[part 4 of 22: package /Cluster]
AUTOSAR XML (schema 4-3-0)
package /Cluster  (continued)
  can cluster E3V_CCAN: baudrate=500000, protocol-name=CAN, protocol-version=2.0, bus-off-recovery={bor-counter-l-1-to-l-2=1, bor-time-l-1=0.05, bor-time-l-2=0.2}  (continued)
    can physical channel CHNL: comm-connectors=CN_E3V_CCAN  (continued)
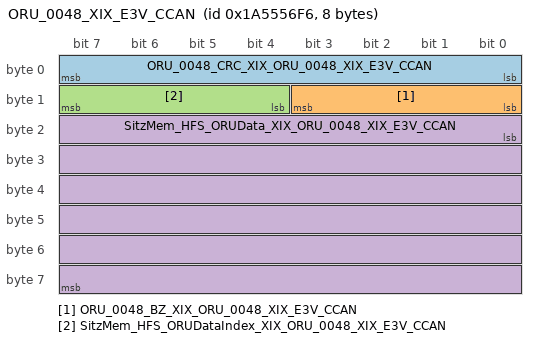
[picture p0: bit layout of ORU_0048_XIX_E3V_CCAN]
      frame ORU_0048_XIX_E3V_CCAN: id 0x1A5556F6, to SAM, frame-length=8, can-addressing-mode=EXTENDED, can-frame-rx-behavior=CAN-20, can-frame-tx-behavior=CAN-20
        pdu ORU_0048_XIX_E3V_CCAN_E2E: length=8, transmission-mode-true-timing=event-controlled-timing={number-of-repetitions=0, repetition-period=0.0}, unused-bit-pattern=0  # Fuer die Botschaft ist das Cyclic-Timing 0.5 zu verwenden.
          signal ORU_0048_CRC_XIX_ORU_0048_XIX_E3V_CCAN: start 0, 8 bit, little-endian, data-type-policy=OVERRIDE, i-signal-type=PRIMITIVE, init-value=0, base-type=BT_ORU_0048_CRC, compu {phys=raw for raw 0..255}, range phys 0..255, raw 0..255, to SAM(timeout 5 s)  # Für MLB: Berechnung siehe Lastenheft "Kommunikationsabsicherung für FlexRay und CAN" Ab MQB und MLBevo: Berechnung siehe Lastenheft "End-to-End Kommunikationsabsicherung" Endwerte siehe Begleitdokument "S-PDU Kennungsfolgen"
          signal ORU_0048_BZ_XIX_ORU_0048_XIX_E3V_CCAN: start 8, 4 bit, little-endian, data-type-policy=OVERRIDE, i-signal-type=PRIMITIVE, init-value=0, base-type=BT_ORU_0048_BZ, compu {phys=raw for raw 0..15}, range phys 0..15, raw 0..15, to SAM(timeout 5 s)  # 4bit Botschaftszähler, wird mit jeder Sendebotschaft inkrementiert
          signal SitzMem_HFS_ORUDataIndex_XIX_ORU_0048_XIX_E3V_CCAN: start 12, 4 bit, little-endian, data-type-policy=OVERRIDE, i-signal-type=PRIMITIVE, init-value=0, base-type=BT_SitzMem_HFS_ORUDataIndex, compu {phys=raw for raw 0..15}, range phys 0..15, raw 0..15, to SAM(timeout 5 s)  # Data index of the last 6 Bytes
          signal SitzMem_HFS_ORUData_XIX_ORU_0048_XIX_E3V_CCAN: start 16, 48 bit, little-endian, data-type-policy=OVERRIDE, i-signal-type=PRIMITIVE, init-value=0, base-type=BT_SitzMem_HFS_ORUData, compu {phys=raw for raw 0..281474976710655}, range phys 0..281474976710655, raw 0..281474976710655, to SAM(timeout 5 s)  # ORU information multiplexed - diagnostic address (2 bytes) - HW-part no (11 bytes) - HW version no. (3 bytes) - SW version no. (4 bytes) - IVD-P Value (64 bytes) need to be sent in combination with ORUDataIndex
          mapping SG_ORU_0048_XIX_E3V_CCAN: i-signal-group=SG_ORU_0048_XIX_E3V_CCAN, transfer-property=TRIGGERED-WITHOUT-REPETITION
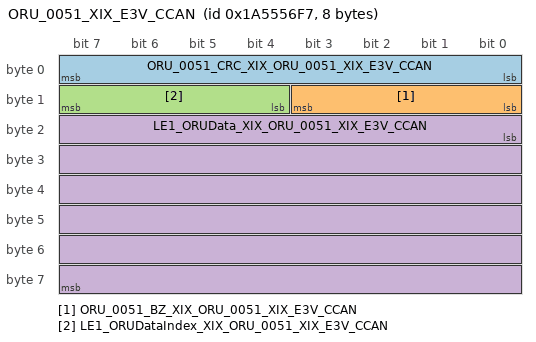
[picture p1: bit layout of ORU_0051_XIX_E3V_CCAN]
      frame ORU_0051_XIX_E3V_CCAN: id 0x1A5556F7, to SAM, frame-length=8, can-addressing-mode=EXTENDED, can-frame-rx-behavior=CAN-20, can-frame-tx-behavior=CAN-20
        pdu ORU_0051_XIX_E3V_CCAN_E2E: length=8, transmission-mode-true-timing=event-controlled-timing={number-of-repetitions=0, repetition-period=0.0}, unused-bit-pattern=0  # Fuer die Botschaft ist das Cyclic-Timing 0.5 zu verwenden.
          signal ORU_0051_CRC_XIX_ORU_0051_XIX_E3V_CCAN: start 0, 8 bit, little-endian, data-type-policy=OVERRIDE, i-signal-type=PRIMITIVE, init-value=0, base-type=BT_ORU_0051_CRC, compu {phys=raw for raw 0..255}, range phys 0..255, raw 0..255, to SAM(timeout 5 s)  # Für MLB: Berechnung siehe Lastenheft "Kommunikationsabsicherung für FlexRay und CAN" Ab MQB und MLBevo: Berechnung siehe Lastenheft "End-to-End Kommunikationsabsicherung" Endwerte siehe Begleitdokument "S-PDU Kennungsfolgen"
          signal ORU_0051_BZ_XIX_ORU_0051_XIX_E3V_CCAN: start 8, 4 bit, little-endian, data-type-policy=OVERRIDE, i-signal-type=PRIMITIVE, init-value=0, base-type=BT_ORU_0051_BZ, compu {phys=raw for raw 0..15}, range phys 0..15, raw 0..15, to SAM(timeout 5 s)  # 4bit Botschaftszähler, wird mit jeder Sendebotschaft inkrementiert
          signal LE1_ORUDataIndex_XIX_ORU_0051_XIX_E3V_CCAN: start 12, 4 bit, little-endian, data-type-policy=OVERRIDE, i-signal-type=PRIMITIVE, init-value=0, base-type=BT_LE1_ORUDataIndex, compu {phys=raw for raw 0..15}, range phys 0..15, raw 0..15, to SAM(timeout 5 s)  # Dataindex of the last 6 bytes
          signal LE1_ORUData_XIX_ORU_0051_XIX_E3V_CCAN: start 16, 48 bit, little-endian, data-type-policy=OVERRIDE, i-signal-type=PRIMITIVE, init-value=0, base-type=BT_LE1_ORUData, compu {phys=raw for raw 0..281474976710655}, range phys 0..281474976710655, raw 0..281474976710655, to SAM(timeout 5 s)  # ORU information multiplexed - diagnostic address (2 bytes) - HW-part no (11 bytes) - HW version no. (3 bytes) - SW version no. (4 bytes) - IVD-P Value (64 bytes) need to be sent in combination with ORUDataIndex
          mapping SG_ORU_0051_XIX_E3V_CCAN: i-signal-group=SG_ORU_0051_XIX_E3V_CCAN, transfer-property=TRIGGERED-WITHOUT-REPETITION
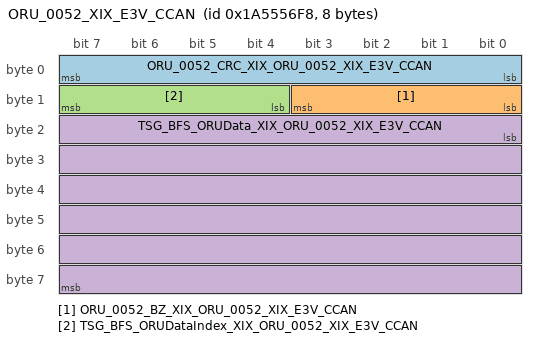
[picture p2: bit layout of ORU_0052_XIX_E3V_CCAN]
      frame ORU_0052_XIX_E3V_CCAN: id 0x1A5556F8, to SAM, frame-length=8, can-addressing-mode=EXTENDED, can-frame-rx-behavior=CAN-20, can-frame-tx-behavior=CAN-20
        pdu ORU_0052_XIX_E3V_CCAN_E2E: length=8, transmission-mode-true-timing=event-controlled-timing={number-of-repetitions=0, repetition-period=0.0}, unused-bit-pattern=0  # Fuer die Botschaft ist das Cyclic-Timing 0.5 zu verwenden.
          signal ORU_0052_CRC_XIX_ORU_0052_XIX_E3V_CCAN: start 0, 8 bit, little-endian, data-type-policy=OVERRIDE, i-signal-type=PRIMITIVE, init-value=0, base-type=BT_ORU_0052_CRC, compu {phys=raw for raw 0..255}, range phys 0..255, raw 0..255, to SAM(timeout 5 s)  # Für MLB: Berechnung siehe Lastenheft "Kommunikationsabsicherung für FlexRay und CAN" Ab MQB und MLBevo: Berechnung siehe Lastenheft "End-to-End Kommunikationsabsicherung" Endwerte siehe Begleitdokument "S-PDU Kennungsfolgen"
          signal ORU_0052_BZ_XIX_ORU_0052_XIX_E3V_CCAN: start 8, 4 bit, little-endian, data-type-policy=OVERRIDE, i-signal-type=PRIMITIVE, init-value=0, base-type=BT_ORU_0052_BZ, compu {phys=raw for raw 0..15}, range phys 0..15, raw 0..15, to SAM(timeout 5 s)  # 4bit Botschaftszähler, wird mit jeder Sendebotschaft inkrementiert
          signal TSG_BFS_ORUDataIndex_XIX_ORU_0052_XIX_E3V_CCAN: start 12, 4 bit, little-endian, data-type-policy=OVERRIDE, i-signal-type=PRIMITIVE, init-value=0, base-type=BT_TSG_BFS_ORUDataIndex, compu {phys=raw for raw 0..15}, range phys 0..15, raw 0..15, to SAM(timeout 5 s)  # Data index of the last 6 Bytes
          signal TSG_BFS_ORUData_XIX_ORU_0052_XIX_E3V_CCAN: start 16, 48 bit, little-endian, data-type-policy=OVERRIDE, i-signal-type=PRIMITIVE, init-value=0, base-type=BT_TSG_BFS_ORUData, compu {phys=raw for raw 0..281474976710655}, range phys 0..281474976710655, raw 0..281474976710655, to SAM(timeout 5 s)  # ORU information multiplexed - diagnostic address (2 bytes) - HW-part no (11 bytes) - HW version no. (3 bytes) - SW version no. (4 bytes) - IVD-P Value (64 bytes) need to be sent in combination with ORUDataIndex
          mapping SG_ORU_0052_XIX_E3V_CCAN: i-signal-group=SG_ORU_0052_XIX_E3V_CCAN, transfer-property=TRIGGERED-WITHOUT-REPETITION
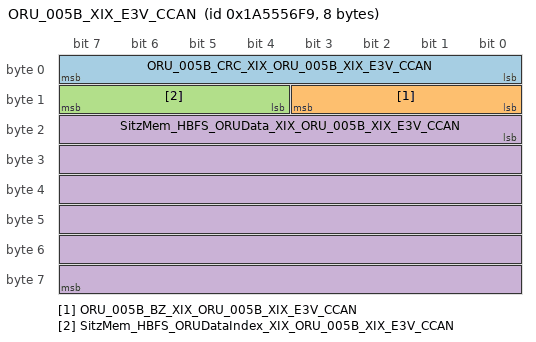
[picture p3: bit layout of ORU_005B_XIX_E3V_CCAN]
      frame ORU_005B_XIX_E3V_CCAN: id 0x1A5556F9, to SAM, frame-length=8, can-addressing-mode=EXTENDED, can-frame-rx-behavior=CAN-20, can-frame-tx-behavior=CAN-20
        pdu ORU_005B_XIX_E3V_CCAN_E2E: length=8, transmission-mode-true-timing=event-controlled-timing={number-of-repetitions=0, repetition-period=0.0}, unused-bit-pattern=0  # Fuer die Botschaft ist das Cyclic-Timing 0.5 zu verwenden.
          signal ORU_005B_CRC_XIX_ORU_005B_XIX_E3V_CCAN: start 0, 8 bit, little-endian, data-type-policy=OVERRIDE, i-signal-type=PRIMITIVE, init-value=0, base-type=BT_ORU_005B_CRC, compu {phys=raw for raw 0..255}, range phys 0..255, raw 0..255, to SAM(timeout 5 s)  # Für MLB: Berechnung siehe Lastenheft "Kommunikationsabsicherung für FlexRay und CAN" Ab MQB und MLBevo: Berechnung siehe Lastenheft "End-to-End Kommunikationsabsicherung" Endwerte siehe Begleitdokument "S-PDU Kennungsfolgen"
          signal ORU_005B_BZ_XIX_ORU_005B_XIX_E3V_CCAN: start 8, 4 bit, little-endian, data-type-policy=OVERRIDE, i-signal-type=PRIMITIVE, init-value=0, base-type=BT_ORU_005B_BZ, compu {phys=raw for raw 0..15}, range phys 0..15, raw 0..15, to SAM(timeout 5 s)  # 4bit Botschaftszähler, wird mit jeder Sendebotschaft inkrementiert
          signal SitzMem_HBFS_ORUDataIndex_XIX_ORU_005B_XIX_E3V_CCAN: start 12, 4 bit, little-endian, data-type-policy=OVERRIDE, i-signal-type=PRIMITIVE, init-value=0, base-type=BT_SitzMem_HBFS_ORUDataIndex, compu {phys=raw for raw 0..15}, range phys 0..15, raw 0..15, to SAM(timeout 5 s)  # Data index of the last 6 Bytes
          signal SitzMem_HBFS_ORUData_XIX_ORU_005B_XIX_E3V_CCAN: start 16, 48 bit, little-endian, data-type-policy=OVERRIDE, i-signal-type=PRIMITIVE, init-value=0, base-type=BT_SitzMem_HBFS_ORUData, compu {phys=raw for raw 0..281474976710655}, range phys 0..281474976710655, raw 0..281474976710655, to SAM(timeout 5 s)  # ORU information multiplexed - diagnostic address (2 bytes) - HW-part no (11 bytes) - HW version no. (3 bytes) - SW version no. (4 bytes) - IVD-P Value (64 bytes) need to be sent in combination with ORUDataIndex
          mapping SG_ORU_005B_XIX_E3V_CCAN: i-signal-group=SG_ORU_005B_XIX_E3V_CCAN, transfer-property=TRIGGERED-WITHOUT-REPETITION
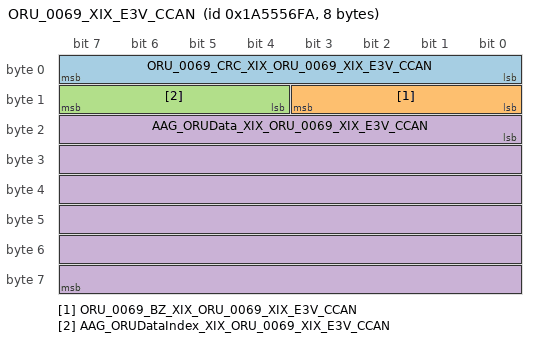
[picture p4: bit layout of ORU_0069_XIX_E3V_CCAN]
      frame ORU_0069_XIX_E3V_CCAN: id 0x1A5556FA, to SAM, frame-length=8, can-addressing-mode=EXTENDED, can-frame-rx-behavior=CAN-20, can-frame-tx-behavior=CAN-20
        pdu ORU_0069_XIX_E3V_CCAN_E2E: length=8, transmission-mode-true-timing=event-controlled-timing={number-of-repetitions=0, repetition-period=0.0}, unused-bit-pattern=0  # Fuer die Botschaft ist das Cyclic-Timing 0.5 zu verwenden.
          signal ORU_0069_CRC_XIX_ORU_0069_XIX_E3V_CCAN: start 0, 8 bit, little-endian, data-type-policy=OVERRIDE, i-signal-type=PRIMITIVE, init-value=0, base-type=BT_ORU_0069_CRC, compu {phys=raw for raw 0..255}, range phys 0..255, raw 0..255, to SAM(timeout 5 s)  # Für MLB: Berechnung siehe Lastenheft "Kommunikationsabsicherung für FlexRay und CAN" Ab MQB und MLBevo: Berechnung siehe Lastenheft "End-to-End Kommunikationsabsicherung" Endwerte siehe Begleitdokument "S-PDU Kennungsfolgen"
          signal ORU_0069_BZ_XIX_ORU_0069_XIX_E3V_CCAN: start 8, 4 bit, little-endian, data-type-policy=OVERRIDE, i-signal-type=PRIMITIVE, init-value=0, base-type=BT_ORU_0069_BZ, compu {phys=raw for raw 0..15}, range phys 0..15, raw 0..15, to SAM(timeout 5 s)  # 4bit Botschaftszähler, wird mit jeder Sendebotschaft inkrementiert
          signal AAG_ORUDataIndex_XIX_ORU_0069_XIX_E3V_CCAN: start 12, 4 bit, little-endian, data-type-policy=OVERRIDE, i-signal-type=PRIMITIVE, init-value=0, base-type=BT_AAG_ORUDataIndex, compu {phys=raw for raw 0..15}, range phys 0..15, raw 0..15, to SAM(timeout 5 s)  # Data index of the last 6 Bytes
          signal AAG_ORUData_XIX_ORU_0069_XIX_E3V_CCAN: start 16, 48 bit, little-endian, data-type-policy=OVERRIDE, i-signal-type=PRIMITIVE, init-value=0, base-type=BT_AAG_ORUData, compu {phys=raw for raw 0..281474976710655}, range phys 0..281474976710655, raw 0..281474976710655, to SAM(timeout 5 s)  # ORU information multiplexed - diagnostic address (2 bytes) - HW-part no (11 bytes) - HW version no. (3 bytes) - SW version no. (4 bytes) - IVD-P Value (64 bytes) need to be sent in combination with ORUDataIndex
          mapping SG_ORU_0069_XIX_E3V_CCAN: i-signal-group=SG_ORU_0069_XIX_E3V_CCAN, transfer-property=TRIGGERED-WITHOUT-REPETITION
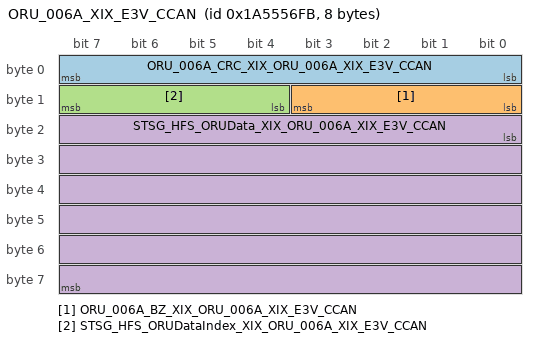
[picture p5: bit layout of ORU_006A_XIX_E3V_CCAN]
      frame ORU_006A_XIX_E3V_CCAN: id 0x1A5556FB, to SAM, frame-length=8, can-addressing-mode=EXTENDED, can-frame-rx-behavior=CAN-20, can-frame-tx-behavior=CAN-20
        pdu ORU_006A_XIX_E3V_CCAN_E2E: length=8, transmission-mode-true-timing=event-controlled-timing={number-of-repetitions=0, repetition-period=0.0}, unused-bit-pattern=0  # Fuer die Botschaft ist das Cyclic-Timing 0.5 zu verwenden.
          signal ORU_006A_CRC_XIX_ORU_006A_XIX_E3V_CCAN: start 0, 8 bit, little-endian, data-type-policy=OVERRIDE, i-signal-type=PRIMITIVE, init-value=0, base-type=BT_ORU_006A_CRC, compu {phys=raw for raw 0..255}, range phys 0..255, raw 0..255, to SAM(timeout 5 s)  # Für MLB: Berechnung siehe Lastenheft "Kommunikationsabsicherung für FlexRay und CAN" Ab MQB und MLBevo: Berechnung siehe Lastenheft "End-to-End Kommunikationsabsicherung" Endwerte siehe Begleitdokument "S-PDU Kennungsfolgen"
          signal ORU_006A_BZ_XIX_ORU_006A_XIX_E3V_CCAN: start 8, 4 bit, little-endian, data-type-policy=OVERRIDE, i-signal-type=PRIMITIVE, init-value=0, base-type=BT_ORU_006A_BZ, compu {phys=raw for raw 0..15}, range phys 0..15, raw 0..15, to SAM(timeout 5 s)  # 4bit Botschaftszähler, wird mit jeder Sendebotschaft inkrementiert
          signal STSG_HFS_ORUDataIndex_XIX_ORU_006A_XIX_E3V_CCAN: start 12, 4 bit, little-endian, data-type-policy=OVERRIDE, i-signal-type=PRIMITIVE, init-value=0, base-type=BT_STSG_HFS_ORUDataIndex, compu {phys=raw for raw 0..15}, range phys 0..15, raw 0..15, to SAM(timeout 5 s)  # Data index of the last 6 Bytes
          signal STSG_HFS_ORUData_XIX_ORU_006A_XIX_E3V_CCAN: start 16, 48 bit, little-endian, data-type-policy=OVERRIDE, i-signal-type=PRIMITIVE, init-value=0, base-type=BT_STSG_HFS_ORUData, compu {phys=raw for raw 0..281474976710655}, range phys 0..281474976710655, raw 0..281474976710655, to SAM(timeout 5 s)  # ORU information multiplexed - diagnostic address (2 bytes) - HW-part no (11 bytes) - HW version no. (3 bytes) - SW version no. (4 bytes) - IVD-P Value (64 bytes) need to be sent in combination with ORUDataIndex
          mapping SG_ORU_006A_XIX_E3V_CCAN: i-signal-group=SG_ORU_006A_XIX_E3V_CCAN, transfer-property=TRIGGERED-WITHOUT-REPETITION
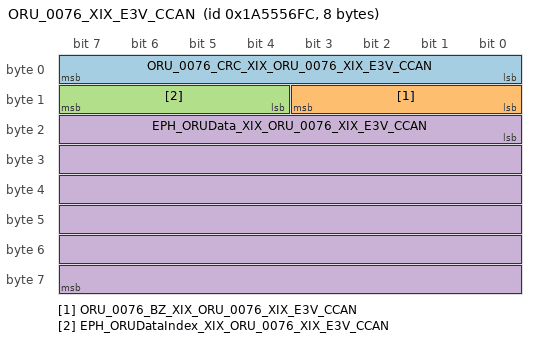
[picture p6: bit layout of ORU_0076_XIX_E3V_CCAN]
      frame ORU_0076_XIX_E3V_CCAN: id 0x1A5556FC, to SAM, frame-length=8, can-addressing-mode=EXTENDED, can-frame-rx-behavior=CAN-20, can-frame-tx-behavior=CAN-20
        pdu ORU_0076_XIX_E3V_CCAN_E2E: length=8, transmission-mode-true-timing=event-controlled-timing={number-of-repetitions=0, repetition-period=0.0}, unused-bit-pattern=0  # Fuer die Botschaft ist das Cyclic-Timing 0.5 zu verwenden.
          signal ORU_0076_CRC_XIX_ORU_0076_XIX_E3V_CCAN: start 0, 8 bit, little-endian, data-type-policy=OVERRIDE, i-signal-type=PRIMITIVE, init-value=0, base-type=BT_ORU_0076_CRC, compu {phys=raw for raw 0..255}, range phys 0..255, raw 0..255, to SAM(timeout 5 s)  # Für MLB: Berechnung siehe Lastenheft "Kommunikationsabsicherung für FlexRay und CAN" Ab MQB und MLBevo: Berechnung siehe Lastenheft "End-to-End Kommunikationsabsicherung" Endwerte siehe Begleitdokument "S-PDU Kennungsfolgen"
          signal ORU_0076_BZ_XIX_ORU_0076_XIX_E3V_CCAN: start 8, 4 bit, little-endian, data-type-policy=OVERRIDE, i-signal-type=PRIMITIVE, init-value=0, base-type=BT_ORU_0076_BZ, compu {phys=raw for raw 0..15}, range phys 0..15, raw 0..15, to SAM(timeout 5 s)  # 4bit Botschaftszähler, wird mit jeder Sendebotschaft inkrementiert
          signal EPH_ORUDataIndex_XIX_ORU_0076_XIX_E3V_CCAN: start 12, 4 bit, little-endian, data-type-policy=OVERRIDE, i-signal-type=PRIMITIVE, init-value=0, base-type=BT_EPH_ORUDataIndex, compu {phys=raw for raw 0..15}, range phys 0..15, raw 0..15, to SAM(timeout 5 s)  # Data index of the last 6 Bytes
          signal EPH_ORUData_XIX_ORU_0076_XIX_E3V_CCAN: start 16, 48 bit, little-endian, data-type-policy=OVERRIDE, i-signal-type=PRIMITIVE, init-value=0, base-type=BT_EPH_ORUData, compu {phys=raw for raw 0..281474976710655}, range phys 0..281474976710655, raw 0..281474976710655, to SAM(timeout 5 s)  # ORU information multiplexed - diagnostic address (2 bytes) - HW-part no (11 bytes) - HW version no. (3 bytes) - SW version no. (4 bytes) - IVD-P Value (64 bytes) need to be sent in combination with ORUDataIndex
          mapping SG_ORU_0076_XIX_E3V_CCAN: i-signal-group=SG_ORU_0076_XIX_E3V_CCAN, transfer-property=TRIGGERED-WITHOUT-REPETITION
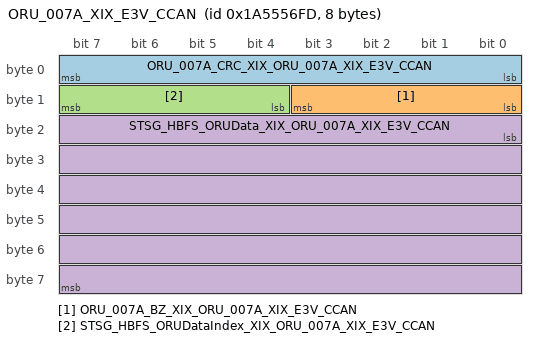
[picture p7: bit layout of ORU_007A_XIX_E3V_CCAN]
      frame ORU_007A_XIX_E3V_CCAN: id 0x1A5556FD, to SAM, frame-length=8, can-addressing-mode=EXTENDED, can-frame-rx-behavior=CAN-20, can-frame-tx-behavior=CAN-20
        pdu ORU_007A_XIX_E3V_CCAN_E2E: length=8, transmission-mode-true-timing=event-controlled-timing={number-of-repetitions=0, repetition-period=0.0}, unused-bit-pattern=0  # Fuer die Botschaft ist das Cyclic-Timing 0.5 zu verwenden.
          signal ORU_007A_CRC_XIX_ORU_007A_XIX_E3V_CCAN: start 0, 8 bit, little-endian, data-type-policy=OVERRIDE, i-signal-type=PRIMITIVE, init-value=0, base-type=BT_ORU_007A_CRC, compu {phys=raw for raw 0..255}, range phys 0..255, raw 0..255, to SAM(timeout 5 s)  # Für MLB: Berechnung siehe Lastenheft "Kommunikationsabsicherung für FlexRay und CAN" Ab MQB und MLBevo: Berechnung siehe Lastenheft "End-to-End Kommunikationsabsicherung" Endwerte siehe Begleitdokument "S-PDU Kennungsfolgen"
          signal ORU_007A_BZ_XIX_ORU_007A_XIX_E3V_CCAN: start 8, 4 bit, little-endian, data-type-policy=OVERRIDE, i-signal-type=PRIMITIVE, init-value=0, base-type=BT_ORU_007A_BZ, compu {phys=raw for raw 0..15}, range phys 0..15, raw 0..15, to SAM(timeout 5 s)  # 4bit Botschaftszähler, wird mit jeder Sendebotschaft inkrementiert
          signal STSG_HBFS_ORUDataIndex_XIX_ORU_007A_XIX_E3V_CCAN: start 12, 4 bit, little-endian, data-type-policy=OVERRIDE, i-signal-type=PRIMITIVE, init-value=0, base-type=BT_STSG_HBFS_ORUDataIndex, compu {phys=raw for raw 0..15}, range phys 0..15, raw 0..15, to SAM(timeout 5 s)  # Data index of the last 6 Bytes
          signal STSG_HBFS_ORUData_XIX_ORU_007A_XIX_E3V_CCAN: start 16, 48 bit, little-endian, data-type-policy=OVERRIDE, i-signal-type=PRIMITIVE, init-value=0, base-type=BT_STSG_HBFS_ORUData, compu {phys=raw for raw 0..281474976710655}, range phys 0..281474976710655, raw 0..281474976710655, to SAM(timeout 5 s)  # ORU information multiplexed - diagnostic address (2 bytes) - HW-part no (11 bytes) - HW version no. (3 bytes) - SW version no. (4 bytes) - IVD-P Value (64 bytes) need to be sent in combination with ORUDataIndex
          mapping SG_ORU_007A_XIX_E3V_CCAN: i-signal-group=SG_ORU_007A_XIX_E3V_CCAN, transfer-property=TRIGGERED-WITHOUT-REPETITION
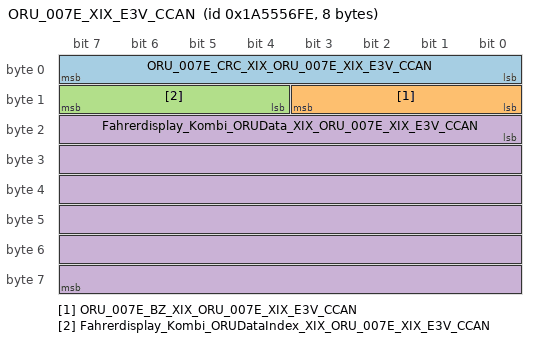
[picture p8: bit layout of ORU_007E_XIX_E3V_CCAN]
      frame ORU_007E_XIX_E3V_CCAN: id 0x1A5556FE, to SAM, frame-length=8, can-addressing-mode=EXTENDED, can-frame-rx-behavior=CAN-20, can-frame-tx-behavior=CAN-20
        pdu ORU_007E_XIX_E3V_CCAN_E2E: length=8, transmission-mode-true-timing=event-controlled-timing={number-of-repetitions=0, repetition-period=0.0}, unused-bit-pattern=0  # Fuer die Botschaft ist das Cyclic-Timing 0.5 zu verwenden.
          signal ORU_007E_CRC_XIX_ORU_007E_XIX_E3V_CCAN: start 0, 8 bit, little-endian, data-type-policy=OVERRIDE, i-signal-type=PRIMITIVE, init-value=0, base-type=BT_ORU_007E_CRC, compu {phys=raw for raw 0..255}, range phys 0..255, raw 0..255, to SAM(timeout 5 s)  # Für MLB: Berechnung siehe Lastenheft "Kommunikationsabsicherung für FlexRay und CAN" Ab MQB und MLBevo: Berechnung siehe Lastenheft "End-to-End Kommunikationsabsicherung" Endwerte siehe Begleitdokument "S-PDU Kennungsfolgen"
          signal ORU_007E_BZ_XIX_ORU_007E_XIX_E3V_CCAN: start 8, 4 bit, little-endian, data-type-policy=OVERRIDE, i-signal-type=PRIMITIVE, init-value=0, base-type=BT_ORU_007E_BZ, compu {phys=raw for raw 0..15}, range phys 0..15, raw 0..15, to SAM(timeout 5 s)  # 4bit Botschaftszähler, wird mit jeder Sendebotschaft inkrementiert
          signal Fahrerdisplay_Kombi_ORUDataIndex_XIX_ORU_007E_XIX_E3V_CCAN: start 12, 4 bit, little-endian, data-type-policy=OVERRIDE, i-signal-type=PRIMITIVE, init-value=0, base-type=BT_Fahrerdisplay_Kombi_ORUDataIndex, compu {phys=raw for raw 0..15}, range phys 0..15, raw 0..15, to SAM(timeout 5 s)  # Data index of the last 6 Bytes
          signal Fahrerdisplay_Kombi_ORUData_XIX_ORU_007E_XIX_E3V_CCAN: start 16, 48 bit, little-endian, data-type-policy=OVERRIDE, i-signal-type=PRIMITIVE, init-value=0, base-type=BT_Fahrerdisplay_Kombi_ORUData, compu {phys=raw for raw 0..281474976710655}, range phys 0..281474976710655, raw 0..281474976710655, to SAM(timeout 5 s)  # '- diagnostic address LowByte=a / Highbyte=b (2 bytes) - HW-part no cde.fgh.ijk.lm (11 bytes ASCII) - HW version no. nop (3 bytes ACII) - SW version no. qrst (4 bytes ASCII) - IVD-P Value (32 bytes) lowest byte = I1 / highest byte = I32
          mapping SG_ORU_007E_XIX_E3V_CCAN: i-signal-group=SG_ORU_007E_XIX_E3V_CCAN, transfer-property=TRIGGERED-WITHOUT-REPETITION
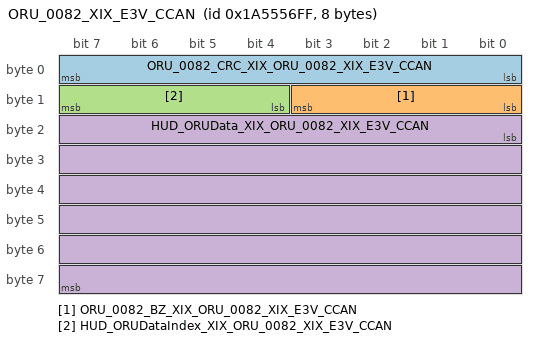
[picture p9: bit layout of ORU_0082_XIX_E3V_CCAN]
      frame ORU_0082_XIX_E3V_CCAN: id 0x1A5556FF, to SAM, frame-length=8, can-addressing-mode=EXTENDED, can-frame-rx-behavior=CAN-20, can-frame-tx-behavior=CAN-20
        pdu ORU_0082_XIX_E3V_CCAN_E2E: length=8, transmission-mode-true-timing=event-controlled-timing={number-of-repetitions=0, repetition-period=0.0}, unused-bit-pattern=0  # Fuer die Botschaft ist das Cyclic-Timing 0.5 zu verwenden.
          signal ORU_0082_CRC_XIX_ORU_0082_XIX_E3V_CCAN: start 0, 8 bit, little-endian, data-type-policy=OVERRIDE, i-signal-type=PRIMITIVE, init-value=0, base-type=BT_ORU_0082_CRC, compu {phys=raw for raw 0..255}, range phys 0..255, raw 0..255, to SAM(timeout 5 s)  # Für MLB: Berechnung siehe Lastenheft "Kommunikationsabsicherung für FlexRay und CAN" Ab MQB und MLBevo: Berechnung siehe Lastenheft "End-to-End Kommunikationsabsicherung" Endwerte siehe Begleitdokument "S-PDU Kennungsfolgen"
          signal ORU_0082_BZ_XIX_ORU_0082_XIX_E3V_CCAN: start 8, 4 bit, little-endian, data-type-policy=OVERRIDE, i-signal-type=PRIMITIVE, init-value=0, base-type=BT_ORU_0082_BZ, compu {phys=raw for raw 0..15}, range phys 0..15, raw 0..15, to SAM(timeout 5 s)  # 4bit Botschaftszähler, wird mit jeder Sendebotschaft inkrementiert
          signal HUD_ORUDataIndex_XIX_ORU_0082_XIX_E3V_CCAN: start 12, 4 bit, little-endian, data-type-policy=OVERRIDE, i-signal-type=PRIMITIVE, init-value=0, base-type=BT_HUD_ORUDataIndex, compu {phys=raw for raw 0..15}, range phys 0..15, raw 0..15, to SAM(timeout 5 s)  # Data index of the last 6 Bytes
          signal HUD_ORUData_XIX_ORU_0082_XIX_E3V_CCAN: start 16, 48 bit, little-endian, data-type-policy=OVERRIDE, i-signal-type=PRIMITIVE, init-value=0, base-type=BT_HUD_ORUData, compu {phys=raw for raw 0..281474976710655}, range phys 0..281474976710655, raw 0..281474976710655, to SAM(timeout 5 s)  # ORU information multiplexed - diagnostic address (2 bytes) - HW-part no (11 bytes) - HW version no. (3 bytes) - SW version no. (4 bytes) - IVD-P Value (64 bytes) need to be sent in combination with ORUDataIndex
          mapping SG_ORU_0082_XIX_E3V_CCAN: i-signal-group=SG_ORU_0082_XIX_E3V_CCAN, transfer-property=TRIGGERED-WITHOUT-REPETITION
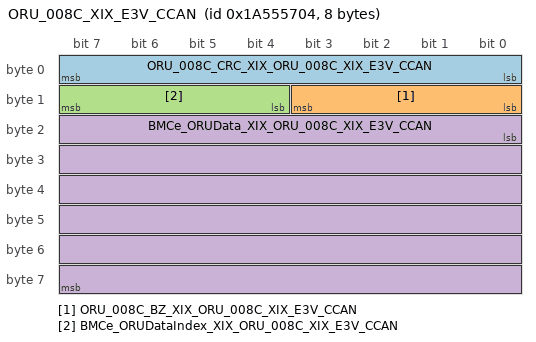
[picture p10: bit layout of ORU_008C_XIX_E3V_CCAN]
      frame ORU_008C_XIX_E3V_CCAN: id 0x1A555704, to SAM, frame-length=8, can-addressing-mode=EXTENDED, can-frame-rx-behavior=CAN-20, can-frame-tx-behavior=CAN-20
        pdu ORU_008C_XIX_E3V_CCAN_E2E: length=8, transmission-mode-true-timing=event-controlled-timing={number-of-repetitions=0, repetition-period=0.0}, unused-bit-pattern=0  # Fuer die Botschaft ist das Cyclic-Timing 0.5 zu verwenden.
          signal ORU_008C_CRC_XIX_ORU_008C_XIX_E3V_CCAN: start 0, 8 bit, little-endian, data-type-policy=OVERRIDE, i-signal-type=PRIMITIVE, init-value=0, base-type=BT_ORU_008C_CRC, compu {phys=raw for raw 0..255}, range phys 0..255, raw 0..255, to SAM(timeout 5 s)  # Für MLB: Berechnung siehe Lastenheft "Kommunikationsabsicherung für FlexRay und CAN" Ab MQB und MLBevo: Berechnung siehe Lastenheft "End-to-End Kommunikationsabsicherung" Endwerte siehe Begleitdokument "S-PDU Kennungsfolgen"
          signal ORU_008C_BZ_XIX_ORU_008C_XIX_E3V_CCAN: start 8, 4 bit, little-endian, data-type-policy=OVERRIDE, i-signal-type=PRIMITIVE, init-value=0, base-type=BT_ORU_008C_BZ, compu {phys=raw for raw 0..15}, range phys 0..15, raw 0..15, to SAM(timeout 5 s)  # 4bit Botschaftszähler, wird mit jeder Sendebotschaft inkrementiert
          signal BMCe_ORUDataIndex_XIX_ORU_008C_XIX_E3V_CCAN: start 12, 4 bit, little-endian, data-type-policy=OVERRIDE, i-signal-type=PRIMITIVE, init-value=0, base-type=BT_BMCe_ORUDataIndex, compu {phys=raw for raw 0..15}, range phys 0..15, raw 0..15, to SAM(timeout 5 s)  # Data index of the last 6 Bytes
          signal BMCe_ORUData_XIX_ORU_008C_XIX_E3V_CCAN: start 16, 48 bit, little-endian, data-type-policy=OVERRIDE, i-signal-type=PRIMITIVE, init-value=0, base-type=BT_BMCe_ORUData, compu {phys=raw for raw 0..281474976710655}, range phys 0..281474976710655, raw 0..281474976710655, to SAM(timeout 5 s)  # ORU information multiplexed - diagnostic address (2 bytes) - HW-part no (11 bytes) - HW version no. (3 bytes) - SW version no. (4 bytes) - IVD-P Value (64 bytes) need to be sent in combination with ORUDataIndex
          mapping SG_ORU_008C_XIX_E3V_CCAN: i-signal-group=SG_ORU_008C_XIX_E3V_CCAN, transfer-property=TRIGGERED-WITHOUT-REPETITION
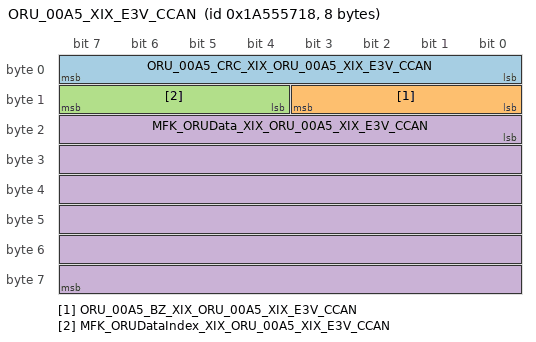
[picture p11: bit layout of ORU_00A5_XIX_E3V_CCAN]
      frame ORU_00A5_XIX_E3V_CCAN: id 0x1A555718, to SAM, frame-length=8, can-addressing-mode=EXTENDED, can-frame-rx-behavior=CAN-20, can-frame-tx-behavior=CAN-20
        pdu ORU_00A5_XIX_E3V_CCAN_E2E: length=8, transmission-mode-true-timing=event-controlled-timing={number-of-repetitions=0, repetition-period=0.0}, unused-bit-pattern=0  # Fuer die Botschaft ist das Cyclic-Timing 0.5 zu verwenden.
          signal ORU_00A5_CRC_XIX_ORU_00A5_XIX_E3V_CCAN: start 0, 8 bit, little-endian, data-type-policy=OVERRIDE, i-signal-type=PRIMITIVE, init-value=0, base-type=BT_ORU_00A5_CRC, compu {phys=raw for raw 0..255}, range phys 0..255, raw 0..255, to SAM(timeout 5 s)  # Für MLB: Berechnung siehe Lastenheft "Kommunikationsabsicherung für FlexRay und CAN" Ab MQB und MLBevo: Berechnung siehe Lastenheft "End-to-End Kommunikationsabsicherung" Endwerte siehe Begleitdokument "S-PDU Kennungsfolgen"
          signal ORU_00A5_BZ_XIX_ORU_00A5_XIX_E3V_CCAN: start 8, 4 bit, little-endian, data-type-policy=OVERRIDE, i-signal-type=PRIMITIVE, init-value=0, base-type=BT_ORU_00A5_BZ, compu {phys=raw for raw 0..15}, range phys 0..15, raw 0..15, to SAM(timeout 5 s)  # 4bit Botschaftszähler, wird mit jeder Sendebotschaft inkrementiert
          signal MFK_ORUDataIndex_XIX_ORU_00A5_XIX_E3V_CCAN: start 12, 4 bit, little-endian, data-type-policy=OVERRIDE, i-signal-type=PRIMITIVE, init-value=0, base-type=BT_MFK_ORUDataIndex, compu {0=Cx0_Init_no_data_is_transmitted (CM_MFK_ORUDataIndex_Cx0_Init_no_data_is_transmitted), 1=Cx1_index_for_data (CM_MFK_ORUDataIndex_Cx1_index_for_data), 2=Cx2_index_for_data (CM_MFK_ORUDataIndex_Cx2_index_for_data), 3=Cx3_index_for_data (CM_MFK_ORUDataIndex_Cx3_index_for_data), 4=Cx4_index_for_data (CM_MFK_ORUDataIndex_Cx4_index_for_data), 5=Cx5_index_for_data (CM_MFK_ORUDataIndex_Cx5_index_for_data), 6=Cx6_index_for_data (CM_MFK_ORUDataIndex_Cx6_index_for_data), 7=Cx7_index_for_data (CM_MFK_ORUDataIndex_Cx7_index_for_data), 8=Cx8_index_for_data (CM_MFK_ORUDataIndex_Cx8_index_for_data), 9=Cx9_index_for_data (CM_MFK_ORUDataIndex_Cx9_index_for_data), 10=Cxa_index_for_data (CM_MFK_ORUDataIndex_Cxa_index_for_data), 11=Cxb_index_for_data (CM_MFK_ORUDataIndex_Cxb_index_for_data), 12=Cxc_index_for_data (CM_MFK_ORUDataIndex_Cxc_index_for_data), 13=Cxd_index_for_data (CM_MFK_ORUDataIndex_Cxd_index_for_data), 14=Cxe_index_for_data (CM_MFK_ORUDataIndex_Cxe_index_for_data), 15=Cxf_unused (CM_MFK_ORUDataIndex_Cxf_unused)}, range raw 0..15, to SAM(timeout 5 s)  # Data index of the last 6 Bytes
          signal MFK_ORUData_XIX_ORU_00A5_XIX_E3V_CCAN: start 16, 48 bit, little-endian, data-type-policy=OVERRIDE, i-signal-type=PRIMITIVE, init-value=0, base-type=BT_MFK_ORUData, compu {phys=raw for raw 0..281474976710655}, range phys 0..281474976710655, raw 0..281474976710655, to SAM(timeout 5 s)  # - diagnostic address LowByte=a / Highbyte=b (2 bytes) - HW-part no cde.fgh.ijk.lm (11 bytes ASCII) - HW version no. nop (3 bytes ACII) - SW version no. qrst (4 bytes ASCII) - IVD-P Value (32 bytes) lowest byte = I1 / highest byte = I32
          mapping SG_ORU_00A5_XIX_E3V_CCAN: i-signal-group=SG_ORU_00A5_XIX_E3V_CCAN, transfer-property=TRIGGERED-WITHOUT-REPETITION
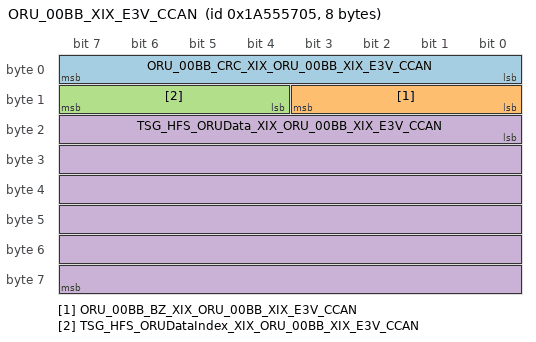
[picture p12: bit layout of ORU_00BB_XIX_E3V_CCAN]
      frame ORU_00BB_XIX_E3V_CCAN: id 0x1A555705, to SAM, frame-length=8, can-addressing-mode=EXTENDED, can-frame-rx-behavior=CAN-20, can-frame-tx-behavior=CAN-20
        pdu ORU_00BB_XIX_E3V_CCAN_E2E: length=8, transmission-mode-true-timing=event-controlled-timing={number-of-repetitions=0, repetition-period=0.0}, unused-bit-pattern=0  # Fuer die Botschaft ist das Cyclic-Timing 0.5 zu verwenden.
          signal ORU_00BB_CRC_XIX_ORU_00BB_XIX_E3V_CCAN: start 0, 8 bit, little-endian, data-type-policy=OVERRIDE, i-signal-type=PRIMITIVE, init-value=0, base-type=BT_ORU_00BB_CRC, compu {phys=raw for raw 0..255}, range phys 0..255, raw 0..255, to SAM(timeout 5 s)  # Für MLB: Berechnung siehe Lastenheft "Kommunikationsabsicherung für FlexRay und CAN" Ab MQB und MLBevo: Berechnung siehe Lastenheft "End-to-End Kommunikationsabsicherung" Endwerte siehe Begleitdokument "S-PDU Kennungsfolgen"
          signal ORU_00BB_BZ_XIX_ORU_00BB_XIX_E3V_CCAN: start 8, 4 bit, little-endian, data-type-policy=OVERRIDE, i-signal-type=PRIMITIVE, init-value=0, base-type=BT_ORU_00BB_BZ, compu {phys=raw for raw 0..15}, range phys 0..15, raw 0..15, to SAM(timeout 5 s)  # 4bit Botschaftszähler, wird mit jeder Sendebotschaft inkrementiert
          signal TSG_HFS_ORUDataIndex_XIX_ORU_00BB_XIX_E3V_CCAN: start 12, 4 bit, little-endian, data-type-policy=OVERRIDE, i-signal-type=PRIMITIVE, init-value=0, base-type=BT_TSG_HFS_ORUDataIndex, compu {phys=raw for raw 0..15}, range phys 0..15, raw 0..15, to SAM(timeout 5 s)  # Data index of the last 6 Bytes
          signal TSG_HFS_ORUData_XIX_ORU_00BB_XIX_E3V_CCAN: start 16, 48 bit, little-endian, data-type-policy=OVERRIDE, i-signal-type=PRIMITIVE, init-value=0, base-type=BT_TSG_HFS_ORUData, compu {phys=raw for raw 0..281474976710655}, range phys 0..281474976710655, raw 0..281474976710655, to SAM(timeout 5 s)  # ORU information multiplexed - diagnostic address (2 bytes) - HW-part no (11 bytes) - HW version no. (3 bytes) - SW version no. (4 bytes) - IVD-P Value (64 bytes) need to be sent in combination with ORUDataIndex
          mapping SG_ORU_00BB_XIX_E3V_CCAN: i-signal-group=SG_ORU_00BB_XIX_E3V_CCAN, transfer-property=TRIGGERED-WITHOUT-REPETITION
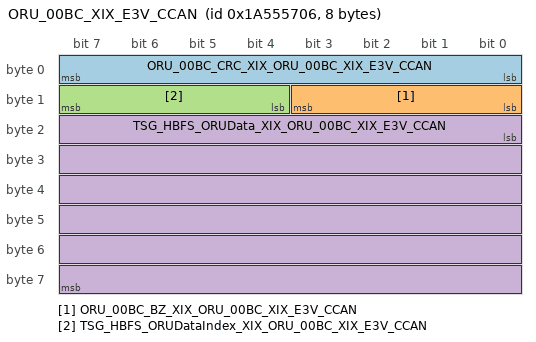
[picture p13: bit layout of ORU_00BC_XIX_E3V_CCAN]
      frame ORU_00BC_XIX_E3V_CCAN: id 0x1A555706, to SAM, frame-length=8, can-addressing-mode=EXTENDED, can-frame-rx-behavior=CAN-20, can-frame-tx-behavior=CAN-20
        pdu ORU_00BC_XIX_E3V_CCAN_E2E: length=8, transmission-mode-true-timing=event-controlled-timing={number-of-repetitions=0, repetition-period=0.0}, unused-bit-pattern=0  # Fuer die Botschaft ist das Cyclic-Timing 0.5 zu verwenden.
          signal ORU_00BC_CRC_XIX_ORU_00BC_XIX_E3V_CCAN: start 0, 8 bit, little-endian, data-type-policy=OVERRIDE, i-signal-type=PRIMITIVE, init-value=0, base-type=BT_ORU_00BC_CRC, compu {phys=raw for raw 0..255}, range phys 0..255, raw 0..255, to SAM(timeout 5 s)  # Für MLB: Berechnung siehe Lastenheft "Kommunikationsabsicherung für FlexRay und CAN" Ab MQB und MLBevo: Berechnung siehe Lastenheft "End-to-End Kommunikationsabsicherung" Endwerte siehe Begleitdokument "S-PDU Kennungsfolgen"
          signal ORU_00BC_BZ_XIX_ORU_00BC_XIX_E3V_CCAN: start 8, 4 bit, little-endian, data-type-policy=OVERRIDE, i-signal-type=PRIMITIVE, init-value=0, base-type=BT_ORU_00BC_BZ, compu {phys=raw for raw 0..15}, range phys 0..15, raw 0..15, to SAM(timeout 5 s)  # 4bit Botschaftszähler, wird mit jeder Sendebotschaft inkrementiert
          signal TSG_HBFS_ORUDataIndex_XIX_ORU_00BC_XIX_E3V_CCAN: start 12, 4 bit, little-endian, data-type-policy=OVERRIDE, i-signal-type=PRIMITIVE, init-value=0, base-type=BT_TSG_HBFS_ORUDataIndex, compu {phys=raw for raw 0..15}, range phys 0..15, raw 0..15, to SAM(timeout 5 s)  # Data index of the last 6 Bytes
          signal TSG_HBFS_ORUData_XIX_ORU_00BC_XIX_E3V_CCAN: start 16, 48 bit, little-endian, data-type-policy=OVERRIDE, i-signal-type=PRIMITIVE, init-value=0, base-type=BT_TSG_HBFS_ORUData, compu {phys=raw for raw 0..281474976710655}, range phys 0..281474976710655, raw 0..281474976710655, to SAM(timeout 5 s)  # ORU information multiplexed - diagnostic address (2 bytes) - HW-part no (11 bytes) - HW version no. (3 bytes) - SW version no. (4 bytes) - IVD-P Value (64 bytes) need to be sent in combination with ORUDataIndex
          mapping SG_ORU_00BC_XIX_E3V_CCAN: i-signal-group=SG_ORU_00BC_XIX_E3V_CCAN, transfer-property=TRIGGERED-WITHOUT-REPETITION
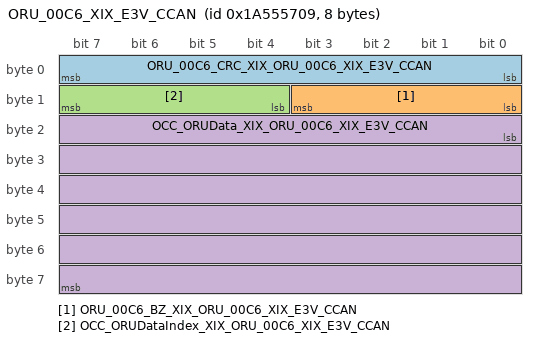
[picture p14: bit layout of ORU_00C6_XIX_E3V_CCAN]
      frame ORU_00C6_XIX_E3V_CCAN: id 0x1A555709, to SAM, frame-length=8, can-addressing-mode=EXTENDED, can-frame-rx-behavior=CAN-20, can-frame-tx-behavior=CAN-20
        pdu ORU_00C6_XIX_E3V_CCAN_E2E: length=8, transmission-mode-true-timing=event-controlled-timing={number-of-repetitions=0, repetition-period=0.0}, unused-bit-pattern=0  # Fuer die Botschaft ist das Cyclic-Timing 0.5 zu verwenden.
          signal ORU_00C6_CRC_XIX_ORU_00C6_XIX_E3V_CCAN: start 0, 8 bit, little-endian, data-type-policy=OVERRIDE, i-signal-type=PRIMITIVE, init-value=0, base-type=BT_ORU_00C6_CRC, compu {phys=raw for raw 0..255}, range phys 0..255, raw 0..255, to SAM(timeout 5 s)  # Für MLB: Berechnung siehe Lastenheft "Kommunikationsabsicherung für FlexRay und CAN" Ab MQB und MLBevo: Berechnung siehe Lastenheft "End-to-End Kommunikationsabsicherung" Endwerte siehe Begleitdokument "S-PDU Kennungsfolgen"
          signal ORU_00C6_BZ_XIX_ORU_00C6_XIX_E3V_CCAN: start 8, 4 bit, little-endian, data-type-policy=OVERRIDE, i-signal-type=PRIMITIVE, init-value=0, base-type=BT_ORU_00C6_BZ, compu {phys=raw for raw 0..15}, range phys 0..15, raw 0..15, to SAM(timeout 5 s)  # 4bit Botschaftszähler, wird mit jeder Sendebotschaft inkrementiert
          signal OCC_ORUDataIndex_XIX_ORU_00C6_XIX_E3V_CCAN: start 12, 4 bit, little-endian, data-type-policy=OVERRIDE, i-signal-type=PRIMITIVE, init-value=0, base-type=BT_OCC_ORUDataIndex, compu {phys=raw for raw 0..15}, range phys 0..15, raw 0..15, to SAM(timeout 5 s)  # Data index of the last 6 Bytes
          signal OCC_ORUData_XIX_ORU_00C6_XIX_E3V_CCAN: start 16, 48 bit, little-endian, data-type-policy=OVERRIDE, i-signal-type=PRIMITIVE, init-value=0, base-type=BT_OCC_ORUData, compu {phys=raw for raw 0..281474976710655}, range phys 0..281474976710655, raw 0..281474976710655, to SAM(timeout 5 s)  # ORU information multiplexed - diagnostic address (2 bytes) - HW-part no (11 bytes) - HW version no. (3 bytes) - SW version no. (4 bytes) - IVD-P Value (64 bytes) need to be sent in combination with ORUDataIndex
          mapping SG_ORU_00C6_XIX_E3V_CCAN: i-signal-group=SG_ORU_00C6_XIX_E3V_CCAN, transfer-property=TRIGGERED-WITHOUT-REPETITION
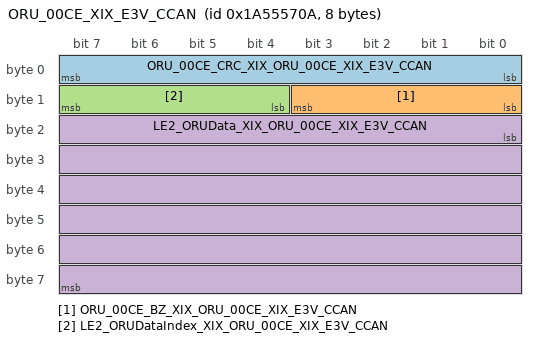
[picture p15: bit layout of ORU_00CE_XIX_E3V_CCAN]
      frame ORU_00CE_XIX_E3V_CCAN: id 0x1A55570A, to SAM, frame-length=8, can-addressing-mode=EXTENDED, can-frame-rx-behavior=CAN-20, can-frame-tx-behavior=CAN-20
        pdu ORU_00CE_XIX_E3V_CCAN_E2E: length=8, transmission-mode-true-timing=event-controlled-timing={number-of-repetitions=0, repetition-period=0.0}, unused-bit-pattern=0  # Fuer die Botschaft ist das Cyclic-Timing 0.5 zu verwenden.
          signal ORU_00CE_CRC_XIX_ORU_00CE_XIX_E3V_CCAN: start 0, 8 bit, little-endian, data-type-policy=OVERRIDE, i-signal-type=PRIMITIVE, init-value=0, base-type=BT_ORU_00CE_CRC, compu {phys=raw for raw 0..255}, range phys 0..255, raw 0..255, to SAM(timeout 5 s)  # Für MLB: Berechnung siehe Lastenheft "Kommunikationsabsicherung für FlexRay und CAN" Ab MQB und MLBevo: Berechnung siehe Lastenheft "End-to-End Kommunikationsabsicherung" Endwerte siehe Begleitdokument "S-PDU Kennungsfolgen"
          signal ORU_00CE_BZ_XIX_ORU_00CE_XIX_E3V_CCAN: start 8, 4 bit, little-endian, data-type-policy=OVERRIDE, i-signal-type=PRIMITIVE, init-value=0, base-type=BT_ORU_00CE_BZ, compu {phys=raw for raw 0..15}, range phys 0..15, raw 0..15, to SAM(timeout 5 s)  # 4bit Botschaftszähler, wird mit jeder Sendebotschaft inkrementiert
          signal LE2_ORUDataIndex_XIX_ORU_00CE_XIX_E3V_CCAN: start 12, 4 bit, little-endian, data-type-policy=OVERRIDE, i-signal-type=PRIMITIVE, init-value=0, base-type=BT_LE2_ORUDataIndex, compu {phys=raw for raw 0..15}, range phys 0..15, raw 0..15, to SAM(timeout 5 s)  # Data index of the last 6 Bytes
          signal LE2_ORUData_XIX_ORU_00CE_XIX_E3V_CCAN: start 16, 48 bit, little-endian, data-type-policy=OVERRIDE, i-signal-type=PRIMITIVE, init-value=0, base-type=BT_LE2_ORUData, compu {phys=raw for raw 0..281474976710655}, range phys 0..281474976710655, raw 0..281474976710655, to SAM(timeout 5 s)  # ORU information multiplexed - diagnostic address (2 bytes) - HW-part no (11 bytes) - HW version no. (3 bytes) - SW version no. (4 bytes) - IVD-P Value (64 bytes) need to be sent in combination with ORUDataIndex
          mapping SG_ORU_00CE_XIX_E3V_CCAN: i-signal-group=SG_ORU_00CE_XIX_E3V_CCAN, transfer-property=TRIGGERED-WITHOUT-REPETITION
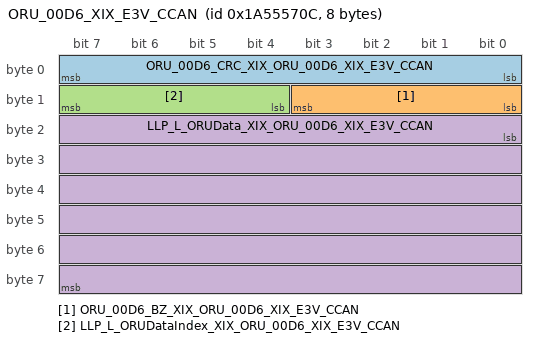
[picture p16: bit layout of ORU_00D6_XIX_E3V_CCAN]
      frame ORU_00D6_XIX_E3V_CCAN: id 0x1A55570C, to SAM, frame-length=8, can-addressing-mode=EXTENDED, can-frame-rx-behavior=CAN-20, can-frame-tx-behavior=CAN-20
        pdu ORU_00D6_XIX_E3V_CCAN_E2E: length=8, transmission-mode-true-timing=event-controlled-timing={number-of-repetitions=0, repetition-period=0.0}, unused-bit-pattern=0  # Fuer die Botschaft ist das Cyclic-Timing 0.5 zu verwenden.
          signal ORU_00D6_CRC_XIX_ORU_00D6_XIX_E3V_CCAN: start 0, 8 bit, little-endian, data-type-policy=OVERRIDE, i-signal-type=PRIMITIVE, init-value=0, base-type=BT_ORU_00D6_CRC, compu {phys=raw for raw 0..255}, range phys 0..255, raw 0..255, to SAM(timeout 5 s)  # Für MLB: Berechnung siehe Lastenheft "Kommunikationsabsicherung für FlexRay und CAN" Ab MQB und MLBevo: Berechnung siehe Lastenheft "End-to-End Kommunikationsabsicherung" Endwerte siehe Begleitdokument "S-PDU Kennungsfolgen"
          signal ORU_00D6_BZ_XIX_ORU_00D6_XIX_E3V_CCAN: start 8, 4 bit, little-endian, data-type-policy=OVERRIDE, i-signal-type=PRIMITIVE, init-value=0, base-type=BT_ORU_00D6_BZ, compu {phys=raw for raw 0..15}, range phys 0..15, raw 0..15, to SAM(timeout 5 s)  # 4bit Botschaftszähler, wird mit jeder Sendebotschaft inkrementiert
          signal LLP_L_ORUDataIndex_XIX_ORU_00D6_XIX_E3V_CCAN: start 12, 4 bit, little-endian, data-type-policy=OVERRIDE, i-signal-type=PRIMITIVE, init-value=0, base-type=BT_LLP_L_ORUDataIndex, compu {phys=raw for raw 0..15}, range phys 0..15, raw 0..15, to SAM(timeout 5 s)  # Data index of the last 6 Bytes
          signal LLP_L_ORUData_XIX_ORU_00D6_XIX_E3V_CCAN: start 16, 48 bit, little-endian, data-type-policy=OVERRIDE, i-signal-type=PRIMITIVE, init-value=0, base-type=BT_LLP_L_ORUData, compu {phys=raw for raw 0..281474976710655}, range phys 0..281474976710655, raw 0..281474976710655, to SAM(timeout 5 s)  # ORU information multiplexed - diagnostic address (2 bytes) - HW-part no (11 bytes) - HW version no. (3 bytes) - SW version no. (4 bytes) - IVD-P Value (64 bytes) need to be sent in combination with ORUDataIndex
          mapping SG_ORU_00D6_XIX_E3V_CCAN: i-signal-group=SG_ORU_00D6_XIX_E3V_CCAN, transfer-property=TRIGGERED-WITHOUT-REPETITION
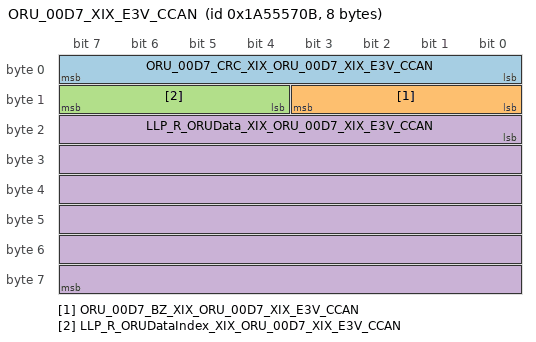
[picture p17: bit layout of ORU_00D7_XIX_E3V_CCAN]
      frame ORU_00D7_XIX_E3V_CCAN: id 0x1A55570B, to SAM, frame-length=8, can-addressing-mode=EXTENDED, can-frame-rx-behavior=CAN-20, can-frame-tx-behavior=CAN-20
        pdu ORU_00D7_XIX_E3V_CCAN_E2E: length=8, transmission-mode-true-timing=event-controlled-timing={number-of-repetitions=0, repetition-period=0.0}, unused-bit-pattern=0  # Fuer die Botschaft ist das Cyclic-Timing 0.5 zu verwenden.
          signal ORU_00D7_CRC_XIX_ORU_00D7_XIX_E3V_CCAN: start 0, 8 bit, little-endian, data-type-policy=OVERRIDE, i-signal-type=PRIMITIVE, init-value=0, base-type=BT_ORU_00D7_CRC, compu {phys=raw for raw 0..255}, range phys 0..255, raw 0..255, to SAM(timeout 5 s)  # Für MLB: Berechnung siehe Lastenheft "Kommunikationsabsicherung für FlexRay und CAN" Ab MQB und MLBevo: Berechnung siehe Lastenheft "End-to-End Kommunikationsabsicherung" Endwerte siehe Begleitdokument "S-PDU Kennungsfolgen"
          signal ORU_00D7_BZ_XIX_ORU_00D7_XIX_E3V_CCAN: start 8, 4 bit, little-endian, data-type-policy=OVERRIDE, i-signal-type=PRIMITIVE, init-value=0, base-type=BT_ORU_00D7_BZ, compu {phys=raw for raw 0..15}, range phys 0..15, raw 0..15, to SAM(timeout 5 s)  # 4bit Botschaftszähler, wird mit jeder Sendebotschaft inkrementiert
          signal LLP_R_ORUDataIndex_XIX_ORU_00D7_XIX_E3V_CCAN: start 12, 4 bit, little-endian, data-type-policy=OVERRIDE, i-signal-type=PRIMITIVE, init-value=0, base-type=BT_LLP_R_ORUDataIndex, compu {phys=raw for raw 0..15}, range phys 0..15, raw 0..15, to SAM(timeout 5 s)  # Data index of the last 6 Bytes
          signal LLP_R_ORUData_XIX_ORU_00D7_XIX_E3V_CCAN: start 16, 48 bit, little-endian, data-type-policy=OVERRIDE, i-signal-type=PRIMITIVE, init-value=0, base-type=BT_LLP_R_ORUData, compu {phys=raw for raw 0..281474976710655}, range phys 0..281474976710655, raw 0..281474976710655, to SAM(timeout 5 s)  # ORU information multiplexed - diagnostic address (2 bytes) - HW-part no (11 bytes) - HW version no. (3 bytes) - SW version no. (4 bytes) - IVD-P Value (64 bytes) need to be sent in combination with ORUDataIndex
          mapping SG_ORU_00D7_XIX_E3V_CCAN: i-signal-group=SG_ORU_00D7_XIX_E3V_CCAN, transfer-property=TRIGGERED-WITHOUT-REPETITION
      frame ORU_03_XIX_E3V_CCAN: id 0x1A555842, to SAM, frame-length=8, can-addressing-mode=EXTENDED, can-frame-rx-behavior=CAN-20, can-frame-tx-behavior=CAN-20
        pdu ORU_03_XIX_E3V_CCAN: length=8, transmission-mode-true-timing=cyclic-timing={time-offset=0, time-period=1.0}, unused-bit-pattern=0
          signal ORU_AP_Mode_XIX_ORU_03_XIX_E3V_CCAN: start 12, 2 bit, little-endian, data-type-policy=OVERRIDE, i-signal-type=PRIMITIVE, init-value=3, base-type=BT_ORU_AP_Mode, compu {0=Cx0_NO_AP_MODE (CM_ORU_AP_Mode_Cx0_NO_AP_MODE), 1=Cx1_AP_MODE (CM_ORU_AP_Mode_Cx1_AP_MODE), 2=Cx2_RESERVED (CM_ORU_AP_Mode_Cx2_RESERVED), 3=Cx3_INIT (CM_ORU_AP_Mode_Cx3_INIT)}, range raw 0..3, transfer-property=PENDING, to SAM(timeout 5 s)  # AfterProd Mode für ORU@Factory und weitere zukünftige Anwendungsfälle wie AFiF
      frame ORU_0631_XIX_E3V_CCAN: id 0x1A55570D, to SAM, frame-length=8, can-addressing-mode=EXTENDED, can-frame-rx-behavior=CAN-20, can-frame-tx-behavior=CAN-20
        pdu ORU_0631_XIX_E3V_CCAN_E2E: length=8, transmission-mode-true-timing=event-controlled-timing={number-of-repetitions=0, repetition-period=0.0}, unused-bit-pattern=0  # Fuer die Botschaft ist das Cyclic-Timing 0.5 zu verwenden.
          signal ORU_0631_CRC_XIX_ORU_0631_XIX_E3V_CCAN: start 0, 8 bit, little-endian, data-type-policy=OVERRIDE, i-signal-type=PRIMITIVE, init-value=0, base-type=BT_ORU_0631_CRC, compu {phys=raw for raw 0..255}, range phys 0..255, raw 0..255, to SAM(timeout 5 s)  # Für MLB: Berechnung siehe Lastenheft "Kommunikationsabsicherung für FlexRay und CAN" Ab MQB und MLBevo: Berechnung siehe Lastenheft "End-to-End Kommunikationsabsicherung" Endwerte siehe Begleitdokument "S-PDU Kennungsfolgen"
          signal ORU_0631_BZ_XIX_ORU_0631_XIX_E3V_CCAN: start 8, 4 bit, little-endian, data-type-policy=OVERRIDE, i-signal-type=PRIMITIVE, init-value=0, base-type=BT_ORU_0631_BZ, compu {phys=raw for raw 0..15}, range phys 0..15, raw 0..15, to SAM(timeout 5 s)  # 4bit Botschaftszähler, wird mit jeder Sendebotschaft inkrementiert
          signal MFL_CAN_ORUDataIndex_XIX_ORU_0631_XIX_E3V_CCAN: start 12, 4 bit, little-endian, data-type-policy=OVERRIDE, i-signal-type=PRIMITIVE, init-value=0, base-type=BT_MFL_CAN_ORUDataIndex, compu {phys=raw for raw 0..15}, range phys 0..15, raw 0..15, to SAM(timeout 5 s)  # Data index of the last 6 Bytes
          signal MFL_CAN_ORUData_XIX_ORU_0631_XIX_E3V_CCAN: start 16, 48 bit, little-endian, data-type-policy=OVERRIDE, i-signal-type=PRIMITIVE, init-value=0, base-type=BT_MFL_CAN_ORUData, compu {phys=raw for raw 0..281474976710655}, range phys 0..281474976710655, raw 0..281474976710655, to SAM(timeout 5 s)  # ORU information multiplexed - diagnostic address (2 bytes) - HW-part no (11 bytes) - HW version no. (3 bytes) - SW version no. (4 bytes) - IVD-P Value (64 bytes) need to be sent in combination with ORUDataIndex
          mapping SG_ORU_0631_XIX_E3V_CCAN: i-signal-group=SG_ORU_0631_XIX_E3V_CCAN, transfer-property=TRIGGERED-WITHOUT-REPETITION
      frame ORU_8105_XIX_E3V_CCAN: id 0x1A55570E, to SAM, frame-length=8, can-addressing-mode=EXTENDED, can-frame-rx-behavior=CAN-20, can-frame-tx-behavior=CAN-20
        pdu ORU_8105_XIX_E3V_CCAN_E2E: length=8, transmission-mode-true-timing=event-controlled-timing={number-of-repetitions=0, repetition-period=0.0}, unused-bit-pattern=0  # Fuer die Botschaft ist das Cyclic-Timing 0.5 zu verwenden.
          signal ORU_8105_CRC_XIX_ORU_8105_XIX_E3V_CCAN: start 0, 8 bit, little-endian, data-type-policy=OVERRIDE, i-signal-type=PRIMITIVE, init-value=0, base-type=BT_ORU_8105_CRC, compu {phys=raw for raw 0..255}, range phys 0..255, raw 0..255, to SAM(timeout 5 s)  # Für MLB: Berechnung siehe Lastenheft "Kommunikationsabsicherung für FlexRay und CAN" Ab MQB und MLBevo: Berechnung siehe Lastenheft "End-to-End Kommunikationsabsicherung" Endwerte siehe Begleitdokument "S-PDU Kennungsfolgen"
          signal ORU_8105_BZ_XIX_ORU_8105_XIX_E3V_CCAN: start 8, 4 bit, little-endian, data-type-policy=OVERRIDE, i-signal-type=PRIMITIVE, init-value=0, base-type=BT_ORU_8105_BZ, compu {phys=raw for raw 0..15}, range phys 0..15, raw 0..15, to SAM(timeout 5 s)  # 4bit Botschaftszähler, wird mit jeder Sendebotschaft inkrementiert
          signal DCDC_NV_ORUDataIndex_XIX_ORU_8105_XIX_E3V_CCAN: start 12, 4 bit, little-endian, data-type-policy=OVERRIDE, i-signal-type=PRIMITIVE, init-value=0, base-type=BT_DCDC_NV_ORUDataIndex, compu {phys=raw for raw 0..15}, range phys 0..15, raw 0..15, to SAM(timeout 5 s)  # Data index of the last 6 Bytes
          signal DCDC_ORUData_XIX_ORU_8105_XIX_E3V_CCAN: start 16, 48 bit, little-endian, data-type-policy=OVERRIDE, i-signal-type=PRIMITIVE, init-value=0, base-type=BT_DCDC_ORUData, compu {phys=raw for raw 0..281474976710655}, range phys 0..281474976710655, raw 0..281474976710655, to SAM(timeout 5 s)  # ORU information multiplexed - diagnostic address (2 bytes) - HW-part no (11 bytes) - HW version no. (3 bytes) - SW version no. (4 bytes) - IVD-P Value (64 bytes) need to be sent in combination with ORUDataIndex
          mapping SG_ORU_8105_XIX_E3V_CCAN: i-signal-group=SG_ORU_8105_XIX_E3V_CCAN, transfer-property=TRIGGERED-WITHOUT-REPETITION
      frame ORU_8109_XIX_E3V_CCAN: id 0x1A55583A, to SAM, frame-length=8, can-addressing-mode=EXTENDED, can-frame-rx-behavior=CAN-20, can-frame-tx-behavior=CAN-20
        pdu ORU_8109_XIX_E3V_CCAN_E2E: length=8, transmission-mode-true-timing=event-controlled-timing={number-of-repetitions=0, repetition-period=0.0}, unused-bit-pattern=0  # Fuer die Botschaft ist das Cyclic-Timing 0.5 zu verwenden.
          signal ORU_8109_CRC_XIX_ORU_8109_XIX_E3V_CCAN: start 0, 8 bit, little-endian, data-type-policy=OVERRIDE, i-signal-type=PRIMITIVE, init-value=0, base-type=BT_ORU_8109_CRC, compu {phys=raw for raw 0..255}, range phys 0..255, raw 0..255, to SAM(timeout 5 s)  # Für MLB: Berechnung siehe Lastenheft "Kommunikationsabsicherung für FlexRay und CAN" Ab MQB und MLBevo: Berechnung siehe Lastenheft "End-to-End Kommunikationsabsicherung" Endwerte siehe Begleitdokument "S-PDU Kennungsfolgen"
          signal ORU_8109_BZ_XIX_ORU_8109_XIX_E3V_CCAN: start 8, 4 bit, little-endian, data-type-policy=OVERRIDE, i-signal-type=PRIMITIVE, init-value=0, base-type=BT_ORU_8109_BZ, compu {phys=raw for raw 0..15}, range phys 0..15, raw 0..15, to SAM(timeout 5 s)  # 4bit Botschaftszähler, wird mit jeder Sendebotschaft inkrementiert
          signal NR1_ORUDataIndex_XIX_ORU_8109_XIX_E3V_CCAN: start 12, 4 bit, little-endian, data-type-policy=OVERRIDE, i-signal-type=PRIMITIVE, init-value=0, base-type=BT_NR1_ORUDataIndex, compu {phys=raw for raw 0..15}, range phys 0..15, raw 0..15, to SAM(timeout 5 s)  # Data index of the last 6 Bytes
          signal NR1_ORUData_XIX_ORU_8109_XIX_E3V_CCAN: start 16, 48 bit, little-endian, data-type-policy=OVERRIDE, i-signal-type=PRIMITIVE, init-value=0, base-type=BT_NR1_ORUData, compu {phys=raw for raw 0..281474976710655}, range phys 0..281474976710655, raw 0..281474976710655, to SAM(timeout 5 s)  # ORU information multiplexed - diagnostic address (2 bytes) - HW-part no (11 bytes) - HW version no. (3 bytes) - SW version no. (4 bytes) - IVD-P Value (32 bytes) need to be sent in combination with ORUDataIndex
          mapping SG_ORU_8109_XIX_E3V_CCAN: i-signal-group=SG_ORU_8109_XIX_E3V_CCAN, transfer-property=TRIGGERED-WITHOUT-REPETITION
      frame ORU_810A_XIX_E3V_CCAN: id 0x1A555839, to SAM, frame-length=8, can-addressing-mode=EXTENDED, can-frame-rx-behavior=CAN-20, can-frame-tx-behavior=CAN-20
        pdu ORU_810A_XIX_E3V_CCAN_E2E: length=8, transmission-mode-true-timing=event-controlled-timing={number-of-repetitions=0, repetition-period=0.0}, unused-bit-pattern=0  # Fuer die Botschaft ist das Cyclic-Timing 0.5 zu verwenden.
          signal ORU_810A_CRC_XIX_ORU_810A_XIX_E3V_CCAN: start 0, 8 bit, little-endian, data-type-policy=OVERRIDE, i-signal-type=PRIMITIVE, init-value=0, base-type=BT_ORU_810A_CRC, compu {phys=raw for raw 0..255}, range phys 0..255, raw 0..255, to SAM(timeout 5 s)  # Für MLB: Berechnung siehe Lastenheft "Kommunikationsabsicherung für FlexRay und CAN" Ab MQB und MLBevo: Berechnung siehe Lastenheft "End-to-End Kommunikationsabsicherung" Endwerte siehe Begleitdokument "S-PDU Kennungsfolgen"
          signal ORU_810A_BZ_XIX_ORU_810A_XIX_E3V_CCAN: start 8, 4 bit, little-endian, data-type-policy=OVERRIDE, i-signal-type=PRIMITIVE, init-value=0, base-type=BT_ORU_810A_BZ, compu {phys=raw for raw 0..15}, range phys 0..15, raw 0..15, to SAM(timeout 5 s)  # 4bit Botschaftszähler, wird mit jeder Sendebotschaft inkrementiert
          signal NR2_ORUDataIndex_XIX_ORU_810A_XIX_E3V_CCAN: start 12, 4 bit, little-endian, data-type-policy=OVERRIDE, i-signal-type=PRIMITIVE, init-value=0, base-type=BT_NR2_ORUDataIndex, compu {phys=raw for raw 0..15}, range phys 0..15, raw 0..15, to SAM(timeout 5 s)  # Data index of the last 6 Bytes
          signal NR2_ORUData_XIX_ORU_810A_XIX_E3V_CCAN: start 16, 48 bit, little-endian, data-type-policy=OVERRIDE, i-signal-type=PRIMITIVE, init-value=0, base-type=BT_NR2_ORUData, compu {phys=raw for raw 0..281474976710655}, range phys 0..281474976710655, raw 0..281474976710655, to SAM(timeout 5 s)  # ORU information multiplexed - diagnostic address (2 bytes) - HW-part no (11 bytes) - HW version no. (3 bytes) - SW version no. (4 bytes) - IVD-P Value (32 bytes) need to be sent in combination with ORUDataIndex
          mapping SG_ORU_810A_XIX_E3V_CCAN: i-signal-group=SG_ORU_810A_XIX_E3V_CCAN, transfer-property=TRIGGERED-WITHOUT-REPETITION
      frame ORU_810B_XIX_E3V_CCAN: id 0x1A555841, to SAM, frame-length=8, can-addressing-mode=EXTENDED, can-frame-rx-behavior=CAN-20, can-frame-tx-behavior=CAN-20
        pdu ORU_810B_XIX_E3V_CCAN_E2E: length=8, transmission-mode-true-timing=event-controlled-timing={number-of-repetitions=0, repetition-period=0.0}, unused-bit-pattern=0  # Fuer die Botschaft ist das Cyclic-Timing 0.5 zu verwenden.
          signal ORU_810B_CRC_XIX_ORU_810B_XIX_E3V_CCAN: start 0, 8 bit, little-endian, data-type-policy=OVERRIDE, i-signal-type=PRIMITIVE, init-value=0, base-type=BT_ORU_810B_CRC, compu {phys=raw for raw 0..255}, range phys 0..255, raw 0..255, to SAM(timeout 5 s)  # Für MLB: "Berechnung siehe Lastenheft "Kommunikationsabsicherung für FlexRay und CAN"" Ab MQB und MLBevo: "Berechnung siehe Lastenheft "End-to-End Kommunikationsabsicherung"" Endwerte siehe Begleitdokument "S-PDU Kennungsfolgen"
          signal ORU_810B_BZ_XIX_ORU_810B_XIX_E3V_CCAN: start 8, 4 bit, little-endian, data-type-policy=OVERRIDE, i-signal-type=PRIMITIVE, init-value=0, base-type=BT_ORU_810B_BZ, compu {phys=raw for raw 0..15}, range phys 0..15, raw 0..15, to SAM(timeout 5 s)
          signal NR3_ORUDataIndex_XIX_ORU_810B_XIX_E3V_CCAN: start 12, 4 bit, little-endian, data-type-policy=OVERRIDE, i-signal-type=PRIMITIVE, init-value=0, base-type=BT_NR3_ORUDataIndex, compu {phys=raw for raw 0..15}, range phys 0..15, raw 0..15, to SAM(timeout 5 s)  # Data index of the last 6 Bytes
          signal NR3_ORUData_XIX_ORU_810B_XIX_E3V_CCAN: start 16, 48 bit, little-endian, data-type-policy=OVERRIDE, i-signal-type=PRIMITIVE, init-value=0, base-type=BT_NR3_ORUData, compu {phys=raw for raw 0..281474976710655}, range phys 0..281474976710655, raw 0..281474976710655, to SAM(timeout 5 s)  # ORU information multiplexed - diagnostic address (2 bytes) - HW-part no (11 bytes) - HW version no. (3 bytes) - SW version no. (4 bytes) - IVD-P Value (32 bytes) need to be sent in combination with ORUDataIndex
          mapping SG_ORU_810B_XIX_E3V_CCAN: i-signal-group=SG_ORU_810B_XIX_E3V_CCAN, transfer-property=TRIGGERED-WITHOUT-REPETITION
      frame ORU_810C_XIX_E3V_CCAN: id 0x1A55583F, to SAM, frame-length=8, can-addressing-mode=EXTENDED, can-frame-rx-behavior=CAN-20, can-frame-tx-behavior=CAN-20
        pdu ORU_810C_XIX_E3V_CCAN_E2E: length=8, transmission-mode-true-timing=event-controlled-timing={number-of-repetitions=0, repetition-period=0.0}, unused-bit-pattern=0  # Fuer die Botschaft ist das Cyclic-Timing 0.5 zu verwenden.
          signal ORU_810C_CRC_XIX_ORU_810C_XIX_E3V_CCAN: start 0, 8 bit, little-endian, data-type-policy=OVERRIDE, i-signal-type=PRIMITIVE, base-type=BT_ORU_810C_CRC, compu {phys=raw for raw 0..255}, range phys 0..255, raw 0..255, to SAM(timeout 5 s)  # Für MLB: "Berechnung siehe Lastenheft "Kommunikationsabsicherung für FlexRay und CAN"" Ab MQB und MLBevo: "Berechnung siehe Lastenheft "End-to-End Kommunikationsabsicherung"" Endwerte siehe Begleitdokument "S-PDU Kennungsfolgen"
          signal ORU_810C_BZ_XIX_ORU_810C_XIX_E3V_CCAN: start 8, 4 bit, little-endian, data-type-policy=OVERRIDE, i-signal-type=PRIMITIVE, base-type=BT_ORU_810C_BZ, compu {phys=raw for raw 0..15}, range phys 0..15, raw 0..15, to SAM(timeout 5 s)
          signal NR4_ORUDataIndex_XIX_ORU_810C_XIX_E3V_CCAN: start 12, 4 bit, little-endian, data-type-policy=OVERRIDE, i-signal-type=PRIMITIVE, init-value=0, base-type=BT_NR4_ORUDataIndex, compu {phys=raw for raw 0..15}, range phys 0..15, raw 0..15, to SAM(timeout 5 s)  # Data index of the last 6 Bytes
          signal NR4_ORUData_XIX_ORU_810C_XIX_E3V_CCAN: start 16, 48 bit, little-endian, data-type-policy=OVERRIDE, i-signal-type=PRIMITIVE, init-value=0, base-type=BT_NR4_ORUData, compu {phys=raw for raw 0..281474976710655}, range phys 0..281474976710655, raw 0..281474976710655, to SAM(timeout 5 s)  # Data index of the last 6 Bytes ORU information multiplexed - diagnostic address (2 bytes) - HW-part no (11 bytes) - HW version no. (3 bytes) - SW version no. (4 bytes) - IVD-P Value (32 bytes)
          mapping SG_ORU_810C_XIX_E3V_CCAN: i-signal-group=SG_ORU_810C_XIX_E3V_CCAN, transfer-property=TRIGGERED-WITHOUT-REPETITION
      frame SAM_01_XIX_E3V_CCAN: id 0x205, from SAM, frame-length=8, can-addressing-mode=STANDARD, can-frame-rx-behavior=CAN-20, can-frame-tx-behavior=CAN-20
        pdu SAM_01_XIX_E3V_CCAN_E2E: length=8, minimum-delay=0.01, transmission-mode-true-timing=event-controlled-timing={number-of-repetitions=0, repetition-period=0.0}, unused-bit-pattern=0  # Fuer die Botschaft ist das Cyclic-Timing 0.2 zu verwenden.
          signal SAM_01_CRC_XIX_SAM_01_XIX_E3V_CCAN: start 0, 8 bit, little-endian, data-type-policy=OVERRIDE, i-signal-type=PRIMITIVE, base-type=BT_SAM_01_CRC, compu {phys=raw for raw 0..255}, range phys 0..255, raw 0..255  # Für MLB: Berechnung siehe Lastenheft "Kommunikationsabsicherung für FlexRay und CAN" Ab MQB und MLBevo: Berechnung siehe Lastenheft "End-to-End Kommunikationsabsicherung" Endwerte siehe Begleitdokument "S-PDU Kennungsfolgen"
          signal SAM_01_BZ_XIX_SAM_01_XIX_E3V_CCAN: start 8, 4 bit, little-endian, data-type-policy=OVERRIDE, i-signal-type=PRIMITIVE, base-type=BT_SAM_01_BZ, compu {phys=raw for raw 0..15}, range phys 0..15, raw 0..15  # 4bit Botschaftszähler, wird mit jeder Sendebotschaft inkrementiert
          signal ZV_Ladeklappe_VerEntriegeln_XIX_SAM_01_XIX_E3V_CCAN: start 12, 2 bit, little-endian, data-type-policy=OVERRIDE, i-signal-type=PRIMITIVE, init-value=0, base-type=BT_ZV_Ladeklappe_VerEntriegeln, compu {0=Cx0_Init (CM_ZV_Ladeklappe_VerEntriegeln_Cx0_Init), 1=Cx1_Ladeklappe_verriegeln (CM_ZV_Ladeklappe_VerEntriegeln_Cx1_Ladeklappe_verriegeln), 2=Cx2_Ladeklappe_entriegeln (CM_ZV_Ladeklappe_VerEntriegeln_Cx2_Ladeklappe_entriegeln), 3=Cx3_keine_Anforderung (CM_ZV_Ladeklappe_VerEntriegeln_Cx3_keine_Anforderung)}, range raw 0..3  # Ver- u. Entriegeln der Ladeklappe
          signal ZV_LadeklappenStatus_XIX_SAM_01_XIX_E3V_CCAN: start 14, 1 bit, little-endian, data-type-policy=OVERRIDE, i-signal-type=PRIMITIVE, init-value=0, base-type=BT_ZV_LadeklappenStatus, compu {0=Cx0_Ladeklappe_geschlossen (CM_ZV_LadeklappenStatus_Cx0_Ladeklappe_geschlossen), 1=Cx1_Ladeklappe_geoeffnet (CM_ZV_LadeklappenStatus_Cx1_Ladeklappe_geoeffnet)}, range raw 0..1  # Gibt den Staus der Ladeklappe aus
          signal ISignalVoid_SAM_01_XIX_E3V_CCAN_0: start 15, 1 bit, little-endian, system signal SignalVoid_SAM_01_0, data-type-policy=OVERRIDE, i-signal-type=PRIMITIVE, base-type=BT_SignalVoid
          signal ISignalVoid_SAM_01_XIX_E3V_CCAN_1: start 16, 8 bit, little-endian, system signal SignalVoid_SAM_01_1, data-type-policy=OVERRIDE, i-signal-type=PRIMITIVE, base-type=BT_SignalVoid
          signal ISignalVoid_SAM_01_XIX_E3V_CCAN_2: start 24, 5 bit, little-endian, system signal SignalVoid_SAM_01_2, data-type-policy=OVERRIDE, i-signal-type=PRIMITIVE, base-type=BT_SignalVoid
          signal SAM_Fehler_DC_LWR_XIX_SAM_01_XIX_E3V_CCAN: start 29, 1 bit, little-endian, data-type-policy=OVERRIDE, i-signal-type=PRIMITIVE, init-value=0, base-type=BT_SAM_Fehler_DC_LWR, invalid-value=Invalid_SAM_Fehler_DC_LWR_XIX_SAM_01_XIX_E3V_CCAN:1, compu {0=Cx0_kein_Fehler (CM_SAM_Fehler_DC_LWR_Cx0_kein_Fehler), 1=Cx1_Fehler (CM_SAM_Fehler_DC_LWR_Cx1_Fehler)}, range raw 0..1  # Fehler im DC-Steller
          signal BCM_Bremsbelag_Sensor_Rdw_XIX_SAM_01_XIX_E3V_CCAN: start 30, 2 bit, little-endian, data-type-policy=OVERRIDE, i-signal-type=PRIMITIVE, init-value=0, base-type=BT_BCM_Bremsbelag_Sensor_Rdw, compu {0=Cx0_OK (CM_BCM_Bremsbelag_Sensor_Rdw_Cx0_OK), 1=Cx1_Bremsbelag_unter_min_iID (CM_BCM_Bremsbelag_Sensor_Rdw_Cx1_Bremsbelag_unter_min_iID), 2=Cx2_Bremsbelag_unter_min_MOD (CM_BCM_Bremsbelag_Sensor_Rdw_Cx2_Bremsbelag_unter_min_MOD)}, range raw 0..2  # Fahrerinformation Warnfall RdW wenn ISO-Symbol (ggf. auch im Display) oder auch für US, wenn eigene BRAKE WARE- Symbolik vorhanden.
          signal BCM_Bremsbelag_Sensor_NAR_XIX_SAM_01_XIX_E3V_CCAN: start 32, 1 bit, little-endian, data-type-policy=OVERRIDE, i-signal-type=PRIMITIVE, init-value=0, base-type=BT_BCM_Bremsbelag_Sensor_NAR, compu {0=Cx0_OK (CM_BCM_Bremsbelag_Sensor_NAR_Cx0_OK), 1=Cx1_Bremsbelag_unter_min (CM_BCM_Bremsbelag_Sensor_NAR_Cx1_Bremsbelag_unter_min)}, range raw 0..1  # Fahrerinformation Warnfall US (sofern keine eigne BRAKE WARE- Symbolik vorhanden und daher die Gesetzeserfüllung über eine statische BKL-Ansteuerung erfolgen muss.
          signal BCM_Bremsbelag_Sensor_CND_XIX_SAM_01_XIX_E3V_CCAN: start 33, 1 bit, little-endian, data-type-policy=OVERRIDE, i-signal-type=PRIMITIVE, init-value=0, base-type=BT_BCM_Bremsbelag_Sensor_CND, compu {0=Cx0_OK (CM_BCM_Bremsbelag_Sensor_CND_Cx0_OK), 1=Cx1_Bremsbelag_unter_min (CM_BCM_Bremsbelag_Sensor_CND_Cx1_Bremsbelag_unter_min)}, range raw 0..1  # Fahrerinformation Warnfall CND wenn ISO-Symbol (ggf. auch im Display)
          signal KST_BSW_Klemme_15_HW_Ist_XIX_SAM_01_XIX_E3V_CCAN: start 34, 2 bit, little-endian, data-type-policy=OVERRIDE, i-signal-type=PRIMITIVE, init-value=0, base-type=BT_KST_BSW_Klemme_15_HW_Ist, invalid-value=Invalid_KST_BSW_Klemme_15_HW_Ist_XIX_SAM_01_XIX_E3V_CCAN:3, compu {0=Cx0_Klemme15HW_aus (CM_KST_BSW_Klemme_15_HW_Ist_Cx0_Klemme15HW_aus), 1=Cx1_Klemme15HW_ein (CM_KST_BSW_Klemme_15_HW_Ist_Cx1_Klemme15HW_ein), 3=Cx3_Fehler (CM_KST_BSW_Klemme_15_HW_Ist_Cx3_Fehler)}, range raw 0..3  # Spiegelung des Klemme 15 Hardware Status auf dem CAN, welcher im MEB durch das SAM gesetzt wird
          signal BRL_Bremslicht_Schalter_XIX_SAM_01_XIX_E3V_CCAN: start 36, 1 bit, little-endian, data-type-policy=OVERRIDE, i-signal-type=PRIMITIVE, init-value=0, base-type=BT_BRL_Bremslicht_Schalter, compu {0=Cx0_nicht_betaetigt (CM_BRL_Bremslicht_Schalter_Cx0_nicht_betaetigt), 1=Cx1_betaetigt (CM_BRL_Bremslicht_Schalter_Cx1_betaetigt)}, range raw 0..1  # Einlesen des Bremslicht-Schalters
          signal SAL_li1_Blinker_Status_XIX_SAM_01_XIX_E3V_CCAN: start 37, 1 bit, little-endian, data-type-policy=OVERRIDE, i-signal-type=PRIMITIVE, init-value=0, base-type=BT_SAL_li1_Blinker_Status, compu {0=Cx0_Blinker_aus (CM_SAL_li1_Blinker_Status_Cx0_Blinker_aus), 1=Cx1_Blinker_an (CM_SAL_li1_Blinker_Status_Cx1_Blinker_an)}, range raw 0..1  # Blinker-Statusüberwachung des SAM zur Erfüllung der funktionalen Sicherheit (Falschblinken, Blinken ohne Anforderung).
          signal SAL_re1_Blinker_Status_XIX_SAM_01_XIX_E3V_CCAN: start 38, 1 bit, little-endian, data-type-policy=OVERRIDE, i-signal-type=PRIMITIVE, init-value=0, base-type=BT_SAL_re1_Blinker_Status, compu {0=Cx0_Blinker_aus (CM_SAL_re1_Blinker_Status_Cx0_Blinker_aus), 1=Cx1_Blinker_an (CM_SAL_re1_Blinker_Status_Cx1_Blinker_an)}, range raw 0..1  # Blinker-Statusüberwachung des SAM zur Erfüllung der funktionalen Sicherheit (Falschblinken, Blinken ohne Anforderung).
          signal KST_BSW_Fehlermode2_XIX_SAM_01_XIX_E3V_CCAN: start 39, 1 bit, little-endian, data-type-policy=OVERRIDE, i-signal-type=PRIMITIVE, init-value=0, base-type=BT_KST_BSW_Fehlermode2, compu {0=Cx0_Aus (CM_KST_BSW_Fehlermode2_Cx0_Aus), 1=Cx1_Ein (CM_KST_BSW_Fehlermode2_Cx1_Ein)}, range raw 0..1  # Signal wird gesetzt, wenn das SAM einen klemmensteuerungs-relevanten Fehler diagnostiziert. Fehler, die das Weiterfahren mit der Anforderung eines zeitnahen Werkstattbesuches erlauben, werden in den Fehlermode 2 eingestuft.
          signal HW_Drehfalle_Tuer_HR_XIX_SAM_01_XIX_E3V_CCAN: start 40, 1 bit, little-endian, data-type-policy=OVERRIDE, i-signal-type=PRIMITIVE, init-value=0, base-type=BT_HW_Drehfalle_Tuer_HR, compu {0=Cx0_geschlossen (CM_HW_Drehfalle_Tuer_HR_Cx0_geschlossen), 1=Cx1_offen (CM_HW_Drehfalle_Tuer_HR_Cx1_offen)}, range raw 0..1  # Hardwaresignal der Drehfalle der Tür Hinten Rechts
          signal HW_Drehfalle_Tuer_HL_XIX_SAM_01_XIX_E3V_CCAN: start 41, 1 bit, little-endian, data-type-policy=OVERRIDE, i-signal-type=PRIMITIVE, init-value=0, base-type=BT_HW_Drehfalle_Tuer_HL, compu {0=Cx0_geschlossen (CM_HW_Drehfalle_Tuer_HL_Cx0_geschlossen), 1=Cx1_offen (CM_HW_Drehfalle_Tuer_HL_Cx1_offen)}, range raw 0..1  # Hardwaresignal der Drehfalle der Tür Hinten Links
          signal HW_Status_Schloss_verriegelt_HR_XIX_SAM_01_XIX_E3V_CCAN: start 42, 1 bit, little-endian, data-type-policy=OVERRIDE, i-signal-type=PRIMITIVE, init-value=0, base-type=BT_HW_Status_Schloss_verriegelt_HR, compu {0=Cx0_nicht_verriegelt (CM_HW_Status_Schloss_verriegelt_HR_Cx0_nicht_verriegelt), 1=Cx1_verriegelt (CM_HW_Status_Schloss_verriegelt_HR_Cx1_verriegelt)}, range raw 0..1  # Hardwaresignal Schlossstatus verriegelt
          signal HW_Status_Schloss_verriegelt_HL_XIX_SAM_01_XIX_E3V_CCAN: start 43, 1 bit, little-endian, data-type-policy=OVERRIDE, i-signal-type=PRIMITIVE, init-value=0, base-type=BT_HW_Status_Schloss_verriegelt_HL, compu {0=Cx0_nicht_verriegelt (CM_HW_Status_Schloss_verriegelt_HL_Cx0_nicht_verriegelt), 1=Cx1_verriegelt (CM_HW_Status_Schloss_verriegelt_HL_Cx1_verriegelt)}, range raw 0..1  # Hardwaresignal Schlossstatus verriegelt
          signal HW_Status_Schloss_gesafet_HR_XIX_SAM_01_XIX_E3V_CCAN: start 44, 1 bit, little-endian, data-type-policy=OVERRIDE, i-signal-type=PRIMITIVE, init-value=0, base-type=BT_HW_Status_Schloss_gesafet_HR, compu {0=Cx0_nicht_gesafet (CM_HW_Status_Schloss_gesafet_HR_Cx0_nicht_gesafet), 1=Cx1_gesafet (CM_HW_Status_Schloss_gesafet_HR_Cx1_gesafet)}, range raw 0..1  # HW-Signal Schlossstatus gesafet
          signal HW_Status_Schloss_gesafet_HL_XIX_SAM_01_XIX_E3V_CCAN: start 45, 1 bit, little-endian, data-type-policy=OVERRIDE, i-signal-type=PRIMITIVE, init-value=0, base-type=BT_HW_Status_Schloss_gesafet_HL, compu {0=Cx0_nicht_gesafet (CM_HW_Status_Schloss_gesafet_HL_Cx0_nicht_gesafet), 1=Cx1_gesafet (CM_HW_Status_Schloss_gesafet_HL_Cx1_gesafet)}, range raw 0..1  # HW-Signal Schlossstatus gesafet
          signal HW_Tankdeckel_offen_XIX_SAM_01_XIX_E3V_CCAN: start 46, 1 bit, little-endian, data-type-policy=OVERRIDE, i-signal-type=PRIMITIVE, init-value=0, base-type=BT_HW_Tankdeckel_offen, compu {0=Cx0_geschlossen (CM_HW_Tankdeckel_offen_Cx0_geschlossen), 1=Cx1_offen (CM_HW_Tankdeckel_offen_Cx1_offen)}, range raw 0..1  # Signal zum Erfassen des Status des Tankdeckels. Signal vom Aktor Steuergerät für die Auswertung im ZV-Master
          signal BCM_KiSi_Umschalt_gesperrt_XIX_SAM_01_XIX_E3V_CCAN: start 47, 1 bit, little-endian, data-type-policy=OVERRIDE, i-signal-type=PRIMITIVE, init-value=0, base-type=BT_BCM_KiSi_Umschalt_gesperrt, compu {0=Cx0_nicht_gesperrt (CM_BCM_KiSi_Umschalt_gesperrt_Cx0_nicht_gesperrt), 1=Cx1_gesperrt (CM_BCM_KiSi_Umschalt_gesperrt_Cx1_gesperrt)}, range raw 0..1  # Umschalten der Kindersicherung gesperrt
          signal Fronthaube_geoeffnet_XIX_SAM_01_XIX_E3V_CCAN: start 48, 1 bit, little-endian, data-type-policy=OVERRIDE, i-signal-type=PRIMITIVE, init-value=0, base-type=BT_Fronthaube_geoeffnet, compu {0=Cx0_geschlossen (CM_Fronthaube_geoeffnet_Cx0_geschlossen), 1=Cx1_geoeffnet (CM_Fronthaube_geoeffnet_Cx1_geoeffnet)}, range raw 0..1  # Information über den Status der Fronthaube
          signal Wischer_aktiv_XIX_SAM_01_XIX_E3V_CCAN: start 49, 1 bit, little-endian, data-type-policy=OVERRIDE, i-signal-type=PRIMITIVE, init-value=0, base-type=BT_Wischer_aktiv, compu {0=Cx0_inaktiv (CM_Wischer_aktiv_Cx0_inaktiv), 1=Cx1_aktiv (CM_Wischer_aktiv_Cx1_aktiv)}, range raw 0..1  # Frontwischermotor aktiv
          signal ISignalVoid_SAM_01_XIX_E3V_CCAN_3: start 50, 2 bit, little-endian, system signal SignalVoid_SAM_01_3, data-type-policy=OVERRIDE, i-signal-type=PRIMITIVE, base-type=BT_SignalVoid
          signal HW_HSB_erkannt_XIX_SAM_01_XIX_E3V_CCAN: start 52, 1 bit, little-endian, data-type-policy=OVERRIDE, i-signal-type=PRIMITIVE, init-value=0, base-type=BT_HW_HSB_erkannt, compu {0=Cx0_nicht_aktiv (CM_HW_HSB_erkannt_Cx0_nicht_aktiv), 1=Cx1_aktiv (CM_HW_HSB_erkannt_Cx1_aktiv)}, range raw 0..1  # Signal wird verwendet, um den DWA-Master einen Heckscheibenbruch zu signalisieren. Die Qualifizierung erfolgt im Sensorsteuergerät.
          signal HD_Hauptraste_XIX_SAM_01_XIX_E3V_CCAN: start 53, 1 bit, little-endian, data-type-policy=OVERRIDE, i-signal-type=PRIMITIVE, init-value=0, base-type=BT_HD_Hauptraste, compu {0=Cx0_geschlossen (CM_HD_Hauptraste_Cx0_geschlossen), 1=Cx1_offen (CM_HD_Hauptraste_Cx1_offen)}, range raw 0..1  # SBL-Schloss (MQB/MLBevo): Drehfalle Heckdeckel sonst (MQB): Hauptraste Heckdeckel
          signal HD_Vorraste_XIX_SAM_01_XIX_E3V_CCAN: start 54, 1 bit, little-endian, data-type-policy=OVERRIDE, i-signal-type=PRIMITIVE, init-value=0, base-type=BT_HD_Vorraste, compu {0=Cx0_geschlossen (CM_HD_Vorraste_Cx0_geschlossen), 1=Cx1_offen (CM_HD_Vorraste_Cx1_offen)}, range raw 0..1  # SBL_Schloss (MQB/MLBevo): Sperrklinke Heckdeckel sonst (MQB): Vorraste Heckdeckel
          signal KST_BSW_Klemmenhochschalten_Sper_XIX_SAM_01_XIX_E3V_CCAN: start 55, 1 bit, little-endian, data-type-policy=OVERRIDE, i-signal-type=PRIMITIVE, init-value=0, base-type=BT_KST_BSW_Klemmenhochschalten_Sper, compu {0=Cx0_nicht_gesperrt (CM_KST_BSW_Klemmenhochschalten_Sper_Cx0_nicht_gesperrt), 1=Cx1_gesperrt (CM_KST_BSW_Klemmenhochschalten_Sper_Cx1_gesperrt)}, range raw 0..1  # Hochschalten der Klemmen im SAM gesperrt
          signal BCM_Tankklappensteller_Fehler_XIX_SAM_01_XIX_E3V_CCAN: start 56, 1 bit, little-endian, data-type-policy=OVERRIDE, i-signal-type=PRIMITIVE, init-value=0, base-type=BT_BCM_Tankklappensteller_Fehler, invalid-value=Invalid_BCM_Tankklappensteller_Fehler_XIX_SAM_01_XIX_E3V_CCAN:1, compu {0=Cx0_kein_Fehler (CM_BCM_Tankklappensteller_Fehler_Cx0_kein_Fehler), 1=Cx1_Fehler (CM_BCM_Tankklappensteller_Fehler_Cx1_Fehler)}, range raw 0..1  # Fehler: nicht Funktionalität des Tankklappenstellers
          signal HW_HD_Taste_Innenraum_XIX_SAM_01_XIX_E3V_CCAN: start 57, 1 bit, little-endian, data-type-policy=OVERRIDE, i-signal-type=PRIMITIVE, init-value=0, base-type=BT_HW_HD_Taste_Innenraum, compu {0=Cx0_Innentaster_nicht_betaetigt (CM_HW_HD_Taste_Innenraum_Cx0_Innentaster_nicht_betaetigt), 1=Cx1_Innentaster_betaetigt (CM_HW_HD_Taste_Innenraum_Cx1_Innentaster_betaetigt)}, range raw 0..1  # Hardwaresignal des Heckdeckeltasters im Innenraum
          signal HW_Softtouch_betaetigt_XIX_SAM_01_XIX_E3V_CCAN: start 58, 1 bit, little-endian, data-type-policy=OVERRIDE, i-signal-type=PRIMITIVE, init-value=0, base-type=BT_HW_Softtouch_betaetigt, compu {0=Cx0_Softtouch_nicht_betaetigt (CM_HW_Softtouch_betaetigt_Cx0_Softtouch_nicht_betaetigt), 1=Cx1_Softtouch_betaetigt (CM_HW_Softtouch_betaetigt_Cx1_Softtouch_betaetigt)}, range raw 0..1  # Hardwaresignal des Softtouchs.
          signal ISignalVoid_SAM_01_XIX_E3V_CCAN_4: start 59, 3 bit, little-endian, system signal SignalVoid_SAM_01_4, data-type-policy=OVERRIDE, i-signal-type=PRIMITIVE, base-type=BT_SignalVoid
          signal KST_BSW_Not_Taster_betaetigt_XIX_SAM_01_XIX_E3V_CCAN: start 62, 1 bit, little-endian, data-type-policy=OVERRIDE, i-signal-type=PRIMITIVE, init-value=0, base-type=BT_KST_BSW_Not_Taster_betaetigt, compu {0=Cx0_nicht_betaetigt (CM_KST_BSW_Not_Taster_betaetigt_Cx0_nicht_betaetigt), 1=Cx1_betaetigt (CM_KST_BSW_Not_Taster_betaetigt_Cx1_betaetigt)}, range raw 0..1  # Not-Taster betätigt
          signal KST_BSW_ZAT_betaetigt_XIX_SAM_01_XIX_E3V_CCAN: start 63, 1 bit, little-endian, data-type-policy=OVERRIDE, i-signal-type=PRIMITIVE, init-value=0, base-type=BT_KST_BSW_ZAT_betaetigt, compu {0=Cx0_Aus (CM_KST_BSW_ZAT_betaetigt_Cx0_Aus), 1=Cx1_Ein (CM_KST_BSW_ZAT_betaetigt_Cx1_Ein)}, range raw 0..1  # Zündanlass-Taster (ZAT) betätigt
          mapping SG_SAM_01_XIX_E3V_CCAN: i-signal-group=SG_SAM_01_XIX_E3V_CCAN, transfer-property=TRIGGERED-WITHOUT-REPETITION
      frame Systeminfo_01_XIX_E3V_CCAN: id 0x585, to SAM, frame-length=8, can-addressing-mode=STANDARD, can-frame-rx-behavior=CAN-20, can-frame-tx-behavior=CAN-20
        pdu Systeminfo_01_XIX_E3V_CCAN: length=8, minimum-delay=0.01, transmission-mode-true-timing={cyclic-timing={time-offset=0.0, time-period=1.0}, event-controlled-timing={number-of-repetitions=0, repetition-period=0.0}}, unused-bit-pattern=0  # MQB, MLBevo
          signal SI_Sammel_SG_Fehler_XIX_Systeminfo_01_XIX_E3V_CCAN: start 0, 6 bit, little-endian, data-type-policy=OVERRIDE, i-signal-type=PRIMITIVE, init-value=63, base-type=BT_SI_Sammel_SG_Fehler, compu {phys=raw for raw 0..60, 61=Cx3d_Reserviert (CM_SI_Sammel_SG_Fehler_Cx3d_Reserviert), 62=Cx3e_Overflow (CM_SI_Sammel_SG_Fehler_Cx3e_Overflow), 63=Cx3f_ungueltig (CM_SI_Sammel_SG_Fehler_Cx3f_ungueltig)}, range phys 0..60, raw 0..63, transfer-property=PENDING  # Anzahl der gesetzten KD-Fehler direkt angeschlossener Steuergeräte der DK3 und DK4 gemäß 80127. Hinweis: Ein Subbusmaster stellt nur die gesammelte Information der an ihn angeschlossenen Steuergeräte der DK3 und DK4 zur Verfügung. Für ServiceKey Auswertung
          signal SI_P_Mode_gueltig_XIX_Systeminfo_01_XIX_E3V_CCAN: start 6, 1 bit, little-endian, data-type-policy=OVERRIDE, i-signal-type=PRIMITIVE, init-value=0, base-type=BT_SI_P_Mode_gueltig, compu {0=Cx0_dezentraler_Produktionsmode (CM_SI_P_Mode_gueltig_Cx0_dezentraler_Produktionsmode), 1=Cx1_zentraler_Produktionsmode (CM_SI_P_Mode_gueltig_Cx1_zentraler_Produktionsmode)}, range raw 0..1, transfer-property=TRIGGERED-ON-CHANGE-WITHOUT-REPETITION, to SAM(timeout 5 s)  # zeigt an, ob es sich um ein Fahrzeug mit zentraler oder dezentraler Steu-erung des Produktionsmodes handelt Siehe Q-LAH Produktionsmode (LAH.DUM.907.AS)
          signal SI_Diagnose_Aktiv_XIX_Systeminfo_01_XIX_E3V_CCAN: start 7, 1 bit, little-endian, data-type-policy=OVERRIDE, i-signal-type=PRIMITIVE, init-value=0, base-type=BT_SI_Diagnose_Aktiv, compu {0=Cx0_inaktiv (CM_SI_Diagnose_Aktiv_Cx0_inaktiv), 1=Cx1_aktiv (CM_SI_Diagnose_Aktiv_Cx1_aktiv)}, range raw 0..1, transfer-property=TRIGGERED-ON-CHANGE-WITHOUT-REPETITION  # Gibt an ob Diagnose-Botschaften empfangen werden und somit eine Diagnose aktiv ist. MQB: Gibt an ob Diagnose-Bus Botschaften empfangen werden und somit eine Diagnose aktiv ist.
          signal SI_QRS_Mode_XIX_Systeminfo_01_XIX_E3V_CCAN: start 8, 1 bit, little-endian, data-type-policy=OVERRIDE, i-signal-type=PRIMITIVE, init-value=0, base-type=BT_SI_QRS_Mode, compu {0=Cx0_QRS_Messmodus_nicht_aktiv (CM_SI_QRS_Mode_Cx0_QRS_Messmodus_nicht_aktiv), 1=Cx1_QRS_Messmodus_aktiv (CM_SI_QRS_Mode_Cx1_QRS_Messmodus_aktiv)}, range raw 0..1, transfer-property=TRIGGERED-ON-CHANGE-WITHOUT-REPETITION, to SAM(timeout 5 s)  # Messmodus Quick-Ruhestrom
          signal SI_T_Mode_XIX_Systeminfo_01_XIX_E3V_CCAN: start 9, 1 bit, little-endian, data-type-policy=OVERRIDE, i-signal-type=PRIMITIVE, init-value=0, base-type=BT_SI_T_Mode, compu {0=Cx0_Transportmodus_nicht_aktiv (CM_SI_T_Mode_Cx0_Transportmodus_nicht_aktiv), 1=Cx1_Transportmodus_aktiv (CM_SI_T_Mode_Cx1_Transportmodus_aktiv)}, range raw 0..1, transfer-property=TRIGGERED-ON-CHANGE-WITHOUT-REPETITION, to SAM(timeout 5 s)  # 0x0: Transportmodus nicht aktiv 0x1: Transportmodus aktiv
          signal SI_NWDF_XIX_Systeminfo_01_XIX_E3V_CCAN: start 10, 1 bit, little-endian, data-type-policy=OVERRIDE, i-signal-type=PRIMITIVE, init-value=0, base-type=BT_SI_NWDF, compu {0=Cx0_Ueberwachung_nicht_freigegeben (CM_SI_NWDF_Cx0_Ueberwachung_nicht_freigegeben), 1=Cx1_Ueberwachung_freigegeben (CM_SI_NWDF_Cx1_Ueberwachung_freigegeben)}, range raw 0..1, transfer-property=TRIGGERED-ON-CHANGE-WITHOUT-REPETITION, to SAM(timeout 5 s)  # Netzwerk-Diagnose Freigebe zur zentralen Aktivierung der Netzwerkdiagnose
          signal SI_NWDF_gueltig_XIX_Systeminfo_01_XIX_E3V_CCAN: start 11, 1 bit, little-endian, data-type-policy=OVERRIDE, i-signal-type=PRIMITIVE, base-type=BT_SI_NWDF_gueltig, compu {0=Cx0_NWDF_wird_nicht_unterstuetzt (CM_SI_NWDF_gueltig_Cx0_NWDF_wird_nicht_unterstuetzt), 1=Cx1_NWDF_wird_unterstuetzt (CM_SI_NWDF_gueltig_Cx1_NWDF_wird_unterstuetzt)}, range raw 0..1, transfer-property=TRIGGERED-ON-CHANGE-WITHOUT-REPETITION, to SAM(timeout 5 s)  # Gültigkeitsbit zu SI_NWDF gemäß Lastenheft: Zentrale Aktivierung Netzwerkdiagnose
          signal SI_Sammelfehler_XIX_Systeminfo_01_XIX_E3V_CCAN: start 12, 1 bit, little-endian, data-type-policy=OVERRIDE, i-signal-type=PRIMITIVE, init-value=0, base-type=BT_SI_Sammelfehler, compu {0=Cx0_kein_Sammelfehler (CM_SI_Sammelfehler_Cx0_kein_Sammelfehler), 1=Cx1_Sammelfehler (CM_SI_Sammelfehler_Cx1_Sammelfehler)}, range raw 0..1, transfer-property=TRIGGERED-ON-CHANGE-WITHOUT-REPETITION  # Sammelfehlermeldung zur Anzeige im Kombi - siehe Spez. Sammelfehlermeldung Hinweis: Einzelne Steuergeräte können zur Anpassung an den Produktionsprozess im Gateway auskodiert werden!
          signal GW_KD_Fehler_XIX_Systeminfo_01_XIX_E3V_CCAN: start 13, 1 bit, little-endian, data-type-policy=OVERRIDE, i-signal-type=PRIMITIVE, init-value=0, base-type=BT_GW_KD_Fehler, compu {0=Cx0_kein_KD_Fehler (CM_GW_KD_Fehler_Cx0_kein_KD_Fehler), 1=Cx1_KD_Fehler (CM_GW_KD_Fehler_Cx1_KD_Fehler)}, range raw 0..1, transfer-property=TRIGGERED-ON-CHANGE-WITHOUT-REPETITION  # Kundendienstfehlerbit Gateway zur Anzeige eines im Gateway abgelegten Fehlerspeichereintrages.
          signal SI_T_Schutz_XIX_Systeminfo_01_XIX_E3V_CCAN: start 14, 1 bit, little-endian, data-type-policy=OVERRIDE, i-signal-type=PRIMITIVE, init-value=0, base-type=BT_SI_T_Schutz, compu {0=Cx0_Transportschutz_nicht_aktiv (CM_SI_T_Schutz_Cx0_Transportschutz_nicht_aktiv), 1=Cx1_Transportschutz_aktiv (CM_SI_T_Schutz_Cx1_Transportschutz_aktiv)}, range raw 0..1, transfer-property=TRIGGERED-ON-CHANGE-WITHOUT-REPETITION, to SAM(timeout 5 s)  # Transportschutz-Signal, das bei Transportmodus und Motorlauf aktiv bleibt 0x0: Transportschutz nicht aktiv 0x1: Transportschutz aktiv
          signal SI_P_Mode_XIX_Systeminfo_01_XIX_E3V_CCAN: start 15, 1 bit, little-endian, data-type-policy=OVERRIDE, i-signal-type=PRIMITIVE, init-value=0, base-type=BT_SI_P_Mode, compu {0=Cx0_inaktiv (CM_SI_P_Mode_Cx0_inaktiv), 1=Cx1_aktiv (CM_SI_P_Mode_Cx1_aktiv)}, range raw 0..1, transfer-property=TRIGGERED-ON-CHANGE-WITHOUT-REPETITION, to SAM(timeout 5 s)  # Zentrale Steuerung des Produktionsmodes gemäß Q-LAH-Produktionsmode (LAH.DUM.907.AS)
          signal SI_BUS_01_XIX_Systeminfo_01_XIX_E3V_CCAN: start 16, 1 bit, little-endian, data-type-policy=OVERRIDE, i-signal-type=PRIMITIVE, init-value=1, base-type=BT_SI_BUS_01, compu {0=Cx0_keine_Busruhe (CM_SI_BUS_01_Cx0_keine_Busruhe), 1=Cx1_Busruhe (CM_SI_BUS_01_Cx1_Busruhe)}, range raw 0..1, transfer-property=TRIGGERED-ON-CHANGE-WITHOUT-REPETITION, to SAM(timeout 5 s)  # MQB/MQB_A0/PQ26: ACAN MQB2020: ACAN(FD) MLBevo: HCAN E3_Volumen: ACAN(FD) MQBw_Baseline: ACAN(FD)
          signal SI_BUS_02_XIX_Systeminfo_01_XIX_E3V_CCAN: start 17, 1 bit, little-endian, data-type-policy=OVERRIDE, i-signal-type=PRIMITIVE, init-value=1, base-type=BT_SI_BUS_02, compu {0=Cx0_keine_Busruhe (CM_SI_BUS_02_Cx0_keine_Busruhe), 1=Cx1_Busruhe (CM_SI_BUS_02_Cx1_Busruhe)}, range raw 0..1, transfer-property=TRIGGERED-ON-CHANGE-WITHOUT-REPETITION, to SAM(timeout 5 s)  # MQB/MQB A0 Standard+, High: FCAN MQB2020: FCAN(FD) MLBevo: Frei E3_Volumen: FCAN(FD) MQBw_Baseline: FCAN(FD)
          signal SI_BUS_03_XIX_Systeminfo_01_XIX_E3V_CCAN: start 18, 1 bit, little-endian, data-type-policy=OVERRIDE, i-signal-type=PRIMITIVE, init-value=1, base-type=BT_SI_BUS_03, compu {0=Cx0_keine_Busruhe (CM_SI_BUS_03_Cx0_keine_Busruhe), 1=Cx1_Busruhe (CM_SI_BUS_03_Cx1_Busruhe)}, range raw 0..1, transfer-property=TRIGGERED-ON-CHANGE-WITHOUT-REPETITION, to SAM(timeout 5 s)  # MQB/MQB A0/PQ26: KCAN MQB2020: KCAN MLBevo: KCAN E3_Volumen: KCAN(HS) / K2CAN(FD) (Buskopplung) MQBw_Baseline: KCAN(HS)
          signal SI_BUS_04_XIX_Systeminfo_01_XIX_E3V_CCAN: start 19, 1 bit, little-endian, data-type-policy=OVERRIDE, i-signal-type=PRIMITIVE, init-value=1, base-type=BT_SI_BUS_04, compu {0=Cx0_keine_Busruhe (CM_SI_BUS_04_Cx0_keine_Busruhe), 1=Cx1_Busruhe (CM_SI_BUS_04_Cx1_Busruhe)}, range raw 0..1, transfer-property=TRIGGERED-ON-CHANGE-WITHOUT-REPETITION  # MQB/MQB A0 Standard+, High: ICAN MQB2020: ICAN(HS) MLBevo: ICAN E3_Volumen: ABCAN(FD) MQBw_Baseline: ICAN(HS)
          signal SI_BUS_05_XIX_Systeminfo_01_XIX_E3V_CCAN: start 20, 1 bit, little-endian, data-type-policy=OVERRIDE, i-signal-type=PRIMITIVE, init-value=1, base-type=BT_SI_BUS_05, compu {0=Cx0_keine_Busruhe (CM_SI_BUS_05_Cx0_keine_Busruhe), 1=Cx1_Busruhe (CM_SI_BUS_05_Cx1_Busruhe)}, range raw 0..1, transfer-property=TRIGGERED-ON-CHANGE-WITHOUT-REPETITION, to SAM(timeout 5 s)  # MQB/MQB A0/PQ26: DiagCAN MQB2020: DiagCAN(FD) MLBevo: DiagCAN E3_Volumen: DiagCAN(FD) MQBw_Baseline: DiagCAN(FD)
          signal SI_BUS_06_XIX_Systeminfo_01_XIX_E3V_CCAN: start 21, 1 bit, little-endian, data-type-policy=OVERRIDE, i-signal-type=PRIMITIVE, init-value=1, base-type=BT_SI_BUS_06, compu {0=Cx0_keine_Busruhe (CM_SI_BUS_06_Cx0_keine_Busruhe), 1=Cx1_Busruhe (CM_SI_BUS_06_Cx1_Busruhe)}, range raw 0..1, transfer-property=TRIGGERED-ON-CHANGE-WITHOUT-REPETITION, to SAM(timeout 5 s)  # MQB/MQB A0/PQ26: ECAN MQB2020: FASCAN(FD) MLBevo: ECAN E3_Volumen: FASCAN_1(FD) MQBw_Baseline: FASCAN_1(FD)
          signal SI_BUS_07_XIX_Systeminfo_01_XIX_E3V_CCAN: start 22, 1 bit, little-endian, data-type-policy=OVERRIDE, i-signal-type=PRIMITIVE, init-value=1, base-type=BT_SI_BUS_07, compu {0=Cx0_keine_Busruhe (CM_SI_BUS_07_Cx0_keine_Busruhe), 1=Cx1_Busruhe (CM_SI_BUS_07_Cx1_Busruhe)}, range raw 0..1, transfer-property=TRIGGERED-ON-CHANGE-WITHOUT-REPETITION  # MQB: LIN1 (Energie) MQB2020: LIN1 (Energie) MLBevo: LIN1 (Energie) E3_Volumen: LIN 1 (Energie) MQBw_Baseline: LIN1 (Energie)
          signal SI_BUS_08_XIX_Systeminfo_01_XIX_E3V_CCAN: start 23, 1 bit, little-endian, data-type-policy=OVERRIDE, i-signal-type=PRIMITIVE, init-value=1, base-type=BT_SI_BUS_08, compu {0=Cx0_keine_Busruhe (CM_SI_BUS_08_Cx0_keine_Busruhe), 1=Cx1_Busruhe (CM_SI_BUS_08_Cx1_Busruhe)}, range raw 0..1, transfer-property=TRIGGERED-ON-CHANGE-WITHOUT-REPETITION  # MQB: LIN2 (MFL) MQB2020: LIN2 (MFL) MLBevo: LIN2 (MFL) E3_Volumen: LIN2 (MFL) MQBw_Baseline: LIN2 (MFL)
          signal SI_BUS_09_XIX_Systeminfo_01_XIX_E3V_CCAN: start 24, 1 bit, little-endian, data-type-policy=OVERRIDE, i-signal-type=PRIMITIVE, init-value=1, base-type=BT_SI_BUS_09, compu {0=Cx0_keine_Busruhe (CM_SI_BUS_09_Cx0_keine_Busruhe), 1=Cx1_Busruhe (CM_SI_BUS_09_Cx1_Busruhe)}, range raw 0..1, transfer-property=TRIGGERED-ON-CHANGE-WITHOUT-REPETITION, to SAM(timeout 5 s)  # MQB: LIN3 (unbelegt) MQB2020: LIN3 (Uhr/FES) MLBevo: LIN3 (Energie2) MEB: LIN3 E³ 1.1 UNECE: MDKCAN
          signal SI_BUS_10_XIX_Systeminfo_01_XIX_E3V_CCAN: start 25, 1 bit, little-endian, data-type-policy=OVERRIDE, i-signal-type=PRIMITIVE, init-value=1, base-type=BT_SI_BUS_10, compu {0=Cx0_keine_Busruhe (CM_SI_BUS_10_Cx0_keine_Busruhe), 1=Cx1_Busruhe (CM_SI_BUS_10_Cx1_Busruhe)}, range raw 0..1, transfer-property=TRIGGERED-ON-CHANGE-WITHOUT-REPETITION, to SAM(timeout 5 s)  # MLBevo: Flexray MQB2020: MCAN MQBw_Baseline: FASCAN_2(FD) E³ 1.1 UNECE: FASCAN_2(FD)
          signal SI_BUS_11_XIX_Systeminfo_01_XIX_E3V_CCAN: start 26, 1 bit, little-endian, data-type-policy=OVERRIDE, i-signal-type=PRIMITIVE, init-value=1, base-type=BT_SI_BUS_11, compu {0=Cx0_keine_Busruhe (CM_SI_BUS_11_Cx0_keine_Busruhe), 1=Cx1_Busruhe (CM_SI_BUS_11_Cx1_Busruhe)}, range raw 0..1, transfer-property=TRIGGERED-ON-CHANGE-WITHOUT-REPETITION  # MLBevo: Ethernet MEB: LIN4
          signal SI_BUS_12_XIX_Systeminfo_01_XIX_E3V_CCAN: start 27, 1 bit, little-endian, data-type-policy=OVERRIDE, i-signal-type=PRIMITIVE, init-value=1, base-type=BT_SI_BUS_12, compu {0=Cx0_keine_Busruhe (CM_SI_BUS_12_Cx0_keine_Busruhe), 1=Cx1_Busruhe (CM_SI_BUS_12_Cx1_Busruhe)}, range raw 0..1, transfer-property=TRIGGERED-ON-CHANGE-WITHOUT-REPETITION  # MQB: unbelegt MLBevo: K2CAN E3_Volumen: MFLCAN MQBw_Baseline: K2CAN(FD)
          signal SI_BUS_13_XIX_Systeminfo_01_XIX_E3V_CCAN: start 28, 1 bit, little-endian, data-type-policy=OVERRIDE, i-signal-type=PRIMITIVE, init-value=1, base-type=BT_SI_BUS_13, compu {0=Cx0_keine_Busruhe (CM_SI_BUS_13_Cx0_keine_Busruhe), 1=Cx1_Busruhe (CM_SI_BUS_13_Cx1_Busruhe)}, range raw 0..1, transfer-property=TRIGGERED-ON-CHANGE-WITHOUT-REPETITION, to SAM(timeout 5 s)  # MQB: unbelegt MLBevo: DCAN MEB: CCAN MQBw_Baseline: K3CAN(FD)
          signal SI_BUS_14_XIX_Systeminfo_01_XIX_E3V_CCAN: start 29, 1 bit, little-endian, data-type-policy=OVERRIDE, i-signal-type=PRIMITIVE, init-value=1, base-type=BT_SI_BUS_14, compu {0=Cx0_keine_Busruhe (CM_SI_BUS_14_Cx0_keine_Busruhe), 1=Cx1_Busruhe (CM_SI_BUS_14_Cx1_Busruhe)}, range raw 0..1, transfer-property=TRIGGERED-ON-CHANGE-WITHOUT-REPETITION, to SAM(timeout 5 s)  # MQB/MQB A0: unbelegt MQB2020: HCAN MLBevo: CCAN E3_Volumen: EVCAN(FD) MQBw_Baseline: EVCANFD(FD)
          signal SI_BUS_15_XIX_Systeminfo_01_XIX_E3V_CCAN: start 30, 1 bit, little-endian, data-type-policy=OVERRIDE, i-signal-type=PRIMITIVE, init-value=1, base-type=BT_SI_BUS_15, compu {0=Cx0_keine_Busruhe (CM_SI_BUS_15_Cx0_keine_Busruhe), 1=Cx1_Busruhe (CM_SI_BUS_15_Cx1_Busruhe)}, range raw 0..1, transfer-property=TRIGGERED-ON-CHANGE-WITHOUT-REPETITION  # MQB: frei MQB2020: frei MLBevo: frei MEB: AFSCAN
          signal SI_NWDF_30_XIX_Systeminfo_01_XIX_E3V_CCAN: start 31, 1 bit, little-endian, data-type-policy=OVERRIDE, i-signal-type=PRIMITIVE, init-value=0, base-type=BT_SI_NWDF_30, compu {0=Cx0_Ueberwachung_nicht_freigegeben (CM_SI_NWDF_30_Cx0_Ueberwachung_nicht_freigegeben), 1=Cx1_Ueberwachung_freigegeben (CM_SI_NWDF_30_Cx1_Ueberwachung_freigegeben)}, range raw 0..1, transfer-property=PENDING  # Netzwerk-Diagnose Freigabe zur zentralen Aktivierung der Netzwerkdiagnose (keine Ausblendbedingung aktiv)
          signal SI_Bus_Identifikation_XIX_Systeminfo_01_XIX_E3V_CCAN: start 32, 8 bit, little-endian, data-type-policy=OVERRIDE, i-signal-type=PRIMITIVE, base-type=BT_SI_Bus_Identifikation, compu {16=Cx10_CAN_Diagnose (CM_SI_Bus_Identifikation_Cx10_CAN_Diagnose), 17=Cx11_CAN_Antrieb (CM_SI_Bus_Identifikation_Cx11_CAN_Antrieb), 18=Cx12_CAN_Komfort (CM_SI_Bus_Identifikation_Cx12_CAN_Komfort), 19=Cx13_CAN_Infotainment (CM_SI_Bus_Identifikation_Cx13_CAN_Infotainment), 20=Cx14_CAN_Fahrwerk (CM_SI_Bus_Identifikation_Cx14_CAN_Fahrwerk), 21=Cx15_CAN_Extended (CM_SI_Bus_Identifikation_Cx15_CAN_Extended), 22=Cx16_CAN_Hybrid (CM_SI_Bus_Identifikation_Cx16_CAN_Hybrid), 23=Cx17_CAN_Lade (CM_SI_Bus_Identifikation_Cx17_CAN_Lade), 24=Cx18_CAN_Kombi (CM_SI_Bus_Identifikation_Cx18_CAN_Kombi), 25=Cx19_CAN_Komfort_2 (CM_SI_Bus_Identifikation_Cx19_CAN_Komfort_2), 26=Cx1a_CAN_AFS (CM_SI_Bus_Identifikation_Cx1a_CAN_AFS), 27=Cx1b_CAN_MIB (CM_SI_Bus_Identifikation_Cx1b_CAN_MIB), 28=Cx1c_CAN_Batterie_BMC (CM_SI_Bus_Identifikation_Cx1c_CAN_Batterie_BMC), 29=Cx1d_CAN_Motor (CM_SI_Bus_Identifikation_Cx1d_CAN_Motor), 31=Cx1f_CAN_Airbag_Sicherheitssysteme (CM_SI_Bus_Identifikation_Cx1f_CAN_Airbag_Sicherheitssysteme), 33=Cx21_CAN_FahrerAssistenzSysteme (CM_SI_Bus_Identifikation_Cx21_CAN_FahrerAssistenzSysteme), 34=Cx22_CAN_Migration (CM_SI_Bus_Identifikation_Cx22_CAN_Migration), 35=Cx23_CAN_Connect (CM_SI_Bus_Identifikation_Cx23_CAN_Connect), 36=Cx24_CAN_AnzeigeBedienung (CM_SI_Bus_Identifikation_Cx24_CAN_AnzeigeBedienung), 37=Cx25_CAN_ElectricalVehicle (CM_SI_Bus_Identifikation_Cx25_CAN_ElectricalVehicle), 40=Cx28_CAN_Telematik (CM_SI_Bus_Identifikation_Cx28_CAN_Telematik), 41=Cx29_CAN_MFL (CM_SI_Bus_Identifikation_Cx29_CAN_MFL), 42=Cx2a_CAN_FahrerAssistenzSysteme_2 (CM_SI_Bus_Identifikation_Cx2a_CAN_FahrerAssistenzSysteme_2), 43=Cx2b_CAN_FahrerAssistenzSysteme_3 (CM_SI_Bus_Identifikation_Cx2b_CAN_FahrerAssistenzSysteme_3), 45=Cx2d_CAN_Fahrwerk_2 (CM_SI_Bus_Identifikation_Cx2d_CAN_Fahrwerk_2), 47=Cx2f_CAN_Komfort_3 (CM_SI_Bus_Identifikation_Cx2f_CAN_Komfort_3), 48=Cx30_FlexRay_A (CM_SI_Bus_Identifikation_Cx30_FlexRay_A), 49=Cx31_FlexRay_B (CM_SI_Bus_Identifikation_Cx31_FlexRay_B), 70=Cx46_CAN_PowerSupply (CM_SI_Bus_Identifikation_Cx46_CAN_PowerSupply), 71=Cx47_CAN_Passenger (CM_SI_Bus_Identifikation_Cx47_CAN_Passenger), 72=Cx48_CAN_Connect_2 (CM_SI_Bus_Identifikation_Cx48_CAN_Connect_2), 73=Cx49_CAN_ElectricalVehicle_2 (CM_SI_Bus_Identifikation_Cx49_CAN_ElectricalVehicle_2), 74=Cx4a_CAN_ElectricalVehicle_3 (CM_SI_Bus_Identifikation_Cx4a_CAN_ElectricalVehicle_3), 75=Cx4b_CAN_ElectricalVehicle_4 (CM_SI_Bus_Identifikation_Cx4b_CAN_ElectricalVehicle_4), 76=Cx4c_CAN_AutonomousDriving_1 (CM_SI_Bus_Identifikation_Cx4c_CAN_AutonomousDriving_1), 77=Cx4d_CAN_AutonomousDriving_2 (CM_SI_Bus_Identifikation_Cx4d_CAN_AutonomousDriving_2), 78=Cx4e_CAN_Drive (CM_SI_Bus_Identifikation_Cx4e_CAN_Drive), 79=Cx4f_CAN_NVEV (CM_SI_Bus_Identifikation_Cx4f_CAN_NVEV), 97=Cx61_VLAN_FAS (CM_SI_Bus_Identifikation_Cx61_VLAN_FAS), 98=Cx62_VLAN_Infotainment (CM_SI_Bus_Identifikation_Cx62_VLAN_Infotainment), 99=Cx63_VLAN_Connect (CM_SI_Bus_Identifikation_Cx63_VLAN_Connect), 100=Cx64_VLAN_Komfort (CM_SI_Bus_Identifikation_Cx64_VLAN_Komfort), 101=Cx65_VLAN_Antrieb (CM_SI_Bus_Identifikation_Cx65_VLAN_Antrieb), 102=Cx66_VLAN_Diagnose (CM_SI_Bus_Identifikation_Cx66_VLAN_Diagnose), 103=Cx67_VLAN_Internet (CM_SI_Bus_Identifikation_Cx67_VLAN_Internet), 104=Cx68_VLAN_Gateway (CM_SI_Bus_Identifikation_Cx68_VLAN_Gateway), 105=Cx69_VLAN_Remote_FC (CM_SI_Bus_Identifikation_Cx69_VLAN_Remote_FC), 106=Cx6a_VLAN_Connect_2 (CM_SI_Bus_Identifikation_Cx6a_VLAN_Connect_2), 107=Cx6b_VLAN_Licht (CM_SI_Bus_Identifikation_Cx6b_VLAN_Licht), 108=Cx6c_VLAN_Charge (CM_SI_Bus_Identifikation_Cx6c_VLAN_Charge), 109=Cx6d_VLAN_Cockpit (CM_SI_Bus_Identifikation_Cx6d_VLAN_Cockpit), 110=Cx6e_VLAN_Connect_3 (CM_SI_Bus_Identifikation_Cx6e_VLAN_Connect_3), 111=Cx6f_VLAN_IoT (CM_SI_Bus_Identifikation_Cx6f_VLAN_IoT), 112=Cx70_VLAN_CarPerformance (CM_SI_Bus_Identifikation_Cx70_VLAN_CarPerformance), 113=Cx71_VLAN_ConMod (CM_SI_Bus_Identifikation_Cx71_VLAN_ConMod), 114=Cx72_VLAN_FAS2 (CM_SI_Bus_Identifikation_Cx72_VLAN_FAS2), 115=Cx73_VLAN_DMZ_1 (CM_SI_Bus_Identifikation_Cx73_VLAN_DMZ_1), 116=Cx74_VLAN_SDS (CM_SI_Bus_Identifikation_Cx74_VLAN_SDS), 117=Cx75_VLAN_Rechenplattform (CM_SI_Bus_Identifikation_Cx75_VLAN_Rechenplattform), 118=Cx76_VLAN_Internet_2 (CM_SI_Bus_Identifikation_Cx76_VLAN_Internet_2), 119=Cx77_VLAN_MaaS (CM_SI_Bus_Identifikation_Cx77_VLAN_MaaS), 176=Cxb0_HCP1_CANFD01 (CM_SI_Bus_Identifikation_Cxb0_HCP1_CANFD01), 177=Cxb1_HCP1_CANFD02 (CM_SI_Bus_Identifikation_Cxb1_HCP1_CANFD02), 178=Cxb2_HCP1_CANFD03 (CM_SI_Bus_Identifikation_Cxb2_HCP1_CANFD03), 179=Cxb3_HCP1_CANFD04 (CM_SI_Bus_Identifikation_Cxb3_HCP1_CANFD04), 180=Cxb4_HCP1_CANFD05 (CM_SI_Bus_Identifikation_Cxb4_HCP1_CANFD05), 181=Cxb5_HCP1_CANFD06 (CM_SI_Bus_Identifikation_Cxb5_HCP1_CANFD06), 182=Cxb6_HCP1_CANFD07 (CM_SI_Bus_Identifikation_Cxb6_HCP1_CANFD07), 183=Cxb7_HCP1_CANFD08 (CM_SI_Bus_Identifikation_Cxb7_HCP1_CANFD08), 186=Cxba_HCP4_CANFD03 (CM_SI_Bus_Identifikation_Cxba_HCP4_CANFD03), 187=Cxbb_HCP4_CANFD04 (CM_SI_Bus_Identifikation_Cxbb_HCP4_CANFD04), 188=Cxbc_HCP1_CANFD09 (CM_SI_Bus_Identifikation_Cxbc_HCP1_CANFD09), 189=Cxbd_HCP4_CANFD06 (CM_SI_Bus_Identifikation_Cxbd_HCP4_CANFD06), 190=Cxbe_HCP4_CANFD07 (CM_SI_Bus_Identifikation_Cxbe_HCP4_CANFD07), 191=Cxbf_HCP4_CANFD08 (CM_SI_Bus_Identifikation_Cxbf_HCP4_CANFD08), 192=Cxc0_HCP4_CANFD09 (CM_SI_Bus_Identifikation_Cxc0_HCP4_CANFD09), 193=Cxc1_HCP4_CANFD10 (CM_SI_Bus_Identifikation_Cxc1_HCP4_CANFD10), 194=Cxc2_HCP1_CANFD10 (CM_SI_Bus_Identifikation_Cxc2_HCP1_CANFD10), 195=Cxc3_ICAS1_CANFD2_HCP5_CANFD02 (CM_SI_Bus_Identifikation_Cxc3_ICAS1_CANFD2_HCP5_CANFD02), 196=Cxc4_HCP1_CANFD11 (CM_SI_Bus_Identifikation_Cxc4_HCP1_CANFD11), 197=Cxc5_WU_HCP1_CANFD (CM_SI_Bus_Identifikation_Cxc5_WU_HCP1_CANFD), 199=Cxc7_WU_HCP2_CANFD (CM_SI_Bus_Identifikation_Cxc7_WU_HCP2_CANFD), 200=Cxc8_WU_HCP3_CANFD (CM_SI_Bus_Identifikation_Cxc8_WU_HCP3_CANFD), 201=Cxc9_WU_HCP4_CANFD (CM_SI_Bus_Identifikation_Cxc9_WU_HCP4_CANFD), 202=Cxca_HCP3_CANFD02 (CM_SI_Bus_Identifikation_Cxca_HCP3_CANFD02), 204=Cxcc_ESC_CANFD (CM_SI_Bus_Identifikation_Cxcc_ESC_CANFD), 205=Cxcd_HCP4_CANFD11 (CM_SI_Bus_Identifikation_Cxcd_HCP4_CANFD11), 206=Cxce_HCP4_CANFD12 (CM_SI_Bus_Identifikation_Cxce_HCP4_CANFD12), 207=Cxcf_CAN_Innenraumsensorik (CM_SI_Bus_Identifikation_Cxcf_CAN_Innenraumsensorik), 212=Cxd4_WU_ConMod_CANFD (CM_SI_Bus_Identifikation_Cxd4_WU_ConMod_CANFD), 213=Cxd5_WU_PASD_CANFD (CM_SI_Bus_Identifikation_Cxd5_WU_PASD_CANFD), 215=Cxd7_CAN_MobileDeviceKey (CM_SI_Bus_Identifikation_Cxd7_CAN_MobileDeviceKey), 217=Cxd9_CAN_Tuerantrieb_VL (CM_SI_Bus_Identifikation_Cxd9_CAN_Tuerantrieb_VL), 218=Cxda_CAN_Tuerantrieb_VR (CM_SI_Bus_Identifikation_Cxda_CAN_Tuerantrieb_VR), 219=Cxdb_CAN_Tuerantrieb_HL (CM_SI_Bus_Identifikation_Cxdb_CAN_Tuerantrieb_HL), 220=Cxdc_CAN_Tuerantrieb_HR (CM_SI_Bus_Identifikation_Cxdc_CAN_Tuerantrieb_HR), 221=Cxdd_CAN_Komfort_4 (CM_SI_Bus_Identifikation_Cxdd_CAN_Komfort_4), 222=Cxde_CAN_Komfort_5 (CM_SI_Bus_Identifikation_Cxde_CAN_Komfort_5)}, range raw 16..222, transfer-property=PENDING, to SAM(timeout 5 s)  # Das Signal identifiziert den Bus eindeutig. Das Signal ist konstant auf jedem Bus. Der Signalwert entspricht dem Wert "Busnummer" aus der VW80127 Gateway_component_list_databus_identification (0x2A2D) "Bus-Identifier".
          signal SI_CAB_V15_XIX_Systeminfo_01_XIX_E3V_CCAN: start 40, 24 bit, opaque, data-type-policy=OVERRIDE, i-signal-type=ARRAY, base-type=BT_SI_CAB_V15, compu {0=Cx0_Init (CM_SI_CAB_V15_Cx0_Init), 1=Cx1_CAB_01_Antrieb (CM_SI_CAB_V15_Cx1_CAB_01_Antrieb), 2=Cx2_CAB_02_Hybrid_Laden (CM_SI_CAB_V15_Cx2_CAB_02_Hybrid_Laden), 4=Cx4_CAB_03_Fahrwerk (CM_SI_CAB_V15_Cx4_CAB_03_Fahrwerk), 8=Cx8_CAB_04_Fahrerassistenz (CM_SI_CAB_V15_Cx8_CAB_04_Fahrerassistenz), 16=Cx10_CAB_05_Komfort (CM_SI_CAB_V15_Cx10_CAB_05_Komfort), 32=Cx20_CAB_06_Anzeige (CM_SI_CAB_V15_Cx20_CAB_06_Anzeige), 64=Cx40_CAB_07_Connect (CM_SI_CAB_V15_Cx40_CAB_07_Connect), 128=Cx80_CAB_08_MIB (CM_SI_CAB_V15_Cx80_CAB_08_MIB), 256=Cx100_CAB_09_Standheizung (CM_SI_CAB_V15_Cx100_CAB_09_Standheizung), 512=Cx200_CAB_10_MDK (CM_SI_CAB_V15_Cx200_CAB_10_MDK), 1024=Cx400_CAB_11_VLAN_Fahrerassistenz (CM_SI_CAB_V15_Cx400_CAB_11_VLAN_Fahrerassistenz), 4096=Cx1000_CAB_13_VLAN_Connect (CM_SI_CAB_V15_Cx1000_CAB_13_VLAN_Connect), 8192=Cx2000_CAB_14_VLAN_Infotainment (CM_SI_CAB_V15_Cx2000_CAB_14_VLAN_Infotainment), 16384=Cx4000_CAB_15_Laden (CM_SI_CAB_V15_Cx4000_CAB_15_Laden), 32768=Cx8000_CAB_16_Licht (CM_SI_CAB_V15_Cx8000_CAB_16_Licht), 65536=Cx10000_CAB_17_RTM (CM_SI_CAB_V15_Cx10000_CAB_17_RTM)}, range raw 0..65536, transfer-property=TRIGGERED-ON-CHANGE-WITHOUT-REPETITION  # CAB = Clusteraktivbits (V15)
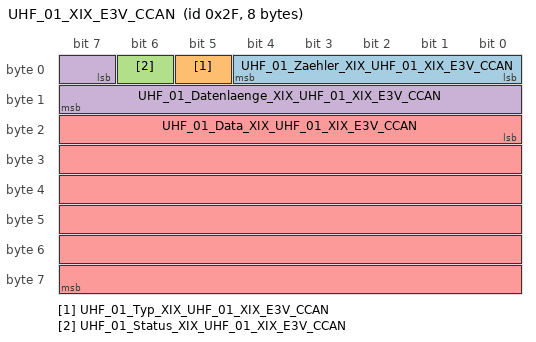
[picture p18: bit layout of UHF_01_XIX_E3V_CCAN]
      frame UHF_01_XIX_E3V_CCAN: id 0x2F, to SAM, frame-length=8, can-addressing-mode=STANDARD, can-frame-rx-behavior=CAN-20, can-frame-tx-behavior=CAN-20
        pdu UHF_01_XIX_E3V_CCAN: length=8, minimum-delay=0.007, transmission-mode-true-timing=event-controlled-timing={number-of-repetitions=0, repetition-period=0.0}, unused-bit-pattern=0
          signal UHF_01_Zaehler_XIX_UHF_01_XIX_E3V_CCAN: start 0, 5 bit, little-endian, data-type-policy=OVERRIDE, i-signal-type=PRIMITIVE, init-value=0, base-type=BT_UHF_01_Zaehler, compu {phys=raw for raw 0..31}, range phys 0..31, raw 0..31, transfer-property=TRIGGERED-ON-CHANGE-WITHOUT-REPETITION, to SAM  # Zähler der UHF-Botschaft
          signal UHF_01_Typ_XIX_UHF_01_XIX_E3V_CCAN: start 5, 1 bit, little-endian, data-type-policy=OVERRIDE, i-signal-type=PRIMITIVE, init-value=0, base-type=BT_UHF_01_Typ, compu {0=Cx0_CRC (CM_UHF_01_Typ_Cx0_CRC), 1=Cx1_Response (CM_UHF_01_Typ_Cx1_Response)}, range raw 0..1, transfer-property=TRIGGERED-ON-CHANGE-WITHOUT-REPETITION, to SAM  # Typ der Botschaft
          signal UHF_01_Status_XIX_UHF_01_XIX_E3V_CCAN: start 6, 1 bit, little-endian, data-type-policy=OVERRIDE, i-signal-type=PRIMITIVE, init-value=0, base-type=BT_UHF_01_Status, compu {0=Cx0_false (CM_UHF_01_Status_Cx0_false), 1=Cx1_true (CM_UHF_01_Status_Cx1_true)}, range raw 0..1, transfer-property=TRIGGERED-ON-CHANGE-WITHOUT-REPETITION, to SAM  # Status der Botschaft
          signal UHF_01_Datenlaenge_XIX_UHF_01_XIX_E3V_CCAN: start 7, 9 bit, little-endian, data-type-policy=OVERRIDE, i-signal-type=PRIMITIVE, init-value=0, base-type=BT_UHF_01_Datenlaenge, compu {phys=raw for raw 0..511; unit Unit_Bit}, range phys 0..511 Unit_Bit, raw 0..511, unit=Unit_Bit, transfer-property=TRIGGERED-ON-CHANGE-WITHOUT-REPETITION, to SAM  # Anzahl der zu übertragenden Bits in der UHF-Botschaft
          signal UHF_01_Data_XIX_UHF_01_XIX_E3V_CCAN: start 16, 48 bit, little-endian, data-type-policy=OVERRIDE, i-signal-type=PRIMITIVE, init-value=0, base-type=BT_UHF_01_Data, compu {phys=raw for raw 0..281474976710655; unit Unit_None}, range phys 0..281474976710655 Unit_None, raw 0..281474976710655, unit=Unit_None, transfer-property=TRIGGERED-ON-CHANGE-WITHOUT-REPETITION, to SAM  # Daten der UHF-Botschaft
      frame UHF_02_XIX_E3V_CCAN: id 0x30, to SAM, frame-length=8, can-addressing-mode=STANDARD, can-frame-rx-behavior=CAN-20, can-frame-tx-behavior=CAN-20
        pdu UHF_02_XIX_E3V_CCAN: length=8, minimum-delay=0.007, transmission-mode-true-timing=event-controlled-timing={number-of-repetitions=0, repetition-period=0.0}, unused-bit-pattern=0
          signal UHF_02_Zaehler_XIX_UHF_02_XIX_E3V_CCAN: start 0, 5 bit, little-endian, data-type-policy=OVERRIDE, i-signal-type=PRIMITIVE, init-value=0, base-type=BT_UHF_02_Zaehler, compu {phys=raw for raw 0..31}, range phys 0..31, raw 0..31, transfer-property=TRIGGERED-ON-CHANGE-WITHOUT-REPETITION, to SAM  # Zähler der UHF-Botschaft
          signal UHF_02_Data_XIX_UHF_02_XIX_E3V_CCAN: start 8, 56 bit, little-endian, data-type-policy=OVERRIDE, i-signal-type=PRIMITIVE, init-value=0, base-type=BT_UHF_02_Data, compu {phys=raw for raw 0..72057594037927935; unit Unit_None}, range phys 0..72057594037927935 Unit_None, raw 0..72057594037927935, unit=Unit_None, transfer-property=TRIGGERED-ON-CHANGE-WITHOUT-REPETITION, to SAM  # Daten der UHF-Botschaft
      frame UHF_03_XIX_E3V_CCAN: id 0x31, to SAM, frame-length=8, can-addressing-mode=STANDARD, can-frame-rx-behavior=CAN-20, can-frame-tx-behavior=CAN-20
        pdu UHF_03_XIX_E3V_CCAN: length=8, minimum-delay=0.007, transmission-mode-true-timing=event-controlled-timing={number-of-repetitions=0, repetition-period=0.0}, unused-bit-pattern=0
          signal UHF_03_Zaehler_XIX_UHF_03_XIX_E3V_CCAN: start 0, 5 bit, little-endian, data-type-policy=OVERRIDE, i-signal-type=PRIMITIVE, init-value=0, base-type=BT_UHF_03_Zaehler, compu {phys=raw for raw 0..31}, range phys 0..31, raw 0..31, transfer-property=TRIGGERED-ON-CHANGE-WITHOUT-REPETITION, to SAM  # Zähler der UHF-Botschaft
          signal UHF_03_Data_XIX_UHF_03_XIX_E3V_CCAN: start 8, 56 bit, little-endian, data-type-policy=OVERRIDE, i-signal-type=PRIMITIVE, init-value=0, base-type=BT_UHF_03_Data, compu {phys=raw for raw 0..72057594037927935; unit Unit_None}, range phys 0..72057594037927935 Unit_None, raw 0..72057594037927935, unit=Unit_None, transfer-property=TRIGGERED-ON-CHANGE-WITHOUT-REPETITION, to SAM  # Daten der UHF-Botschaft
      frame UHF_04_XIX_E3V_CCAN: id 0x32, to SAM, frame-length=8, can-addressing-mode=STANDARD, can-frame-rx-behavior=CAN-20, can-frame-tx-behavior=CAN-20
        pdu UHF_04_XIX_E3V_CCAN: length=8, minimum-delay=0.007, transmission-mode-true-timing=event-controlled-timing={number-of-repetitions=0, repetition-period=0.0}, unused-bit-pattern=0
          signal UHF_04_Zaehler_XIX_UHF_04_XIX_E3V_CCAN: start 0, 5 bit, little-endian, data-type-policy=OVERRIDE, i-signal-type=PRIMITIVE, init-value=0, base-type=BT_UHF_04_Zaehler, compu {phys=raw for raw 0..31}, range phys 0..31, raw 0..31, transfer-property=TRIGGERED-ON-CHANGE-WITHOUT-REPETITION, to SAM  # Zähler der UHF-Botschaft
          signal UHF_04_Data_XIX_UHF_04_XIX_E3V_CCAN: start 8, 56 bit, little-endian, data-type-policy=OVERRIDE, i-signal-type=PRIMITIVE, init-value=0, base-type=BT_UHF_04_Data, compu {phys=raw for raw 0..72057594037927935; unit Unit_None}, range phys 0..72057594037927935 Unit_None, raw 0..72057594037927935, unit=Unit_None, transfer-property=TRIGGERED-ON-CHANGE-WITHOUT-REPETITION, to SAM  # Daten der UHF-Botschaft
      frame UHF_05_XIX_E3V_CCAN: id 0x33, to SAM, frame-length=8, can-addressing-mode=STANDARD, can-frame-rx-behavior=CAN-20, can-frame-tx-behavior=CAN-20
        pdu UHF_05_XIX_E3V_CCAN: length=8, minimum-delay=0.007, transmission-mode-true-timing=event-controlled-timing={number-of-repetitions=0, repetition-period=0.0}, unused-bit-pattern=0
          signal UHF_05_Zaehler_XIX_UHF_05_XIX_E3V_CCAN: start 0, 5 bit, little-endian, data-type-policy=OVERRIDE, i-signal-type=PRIMITIVE, init-value=0, base-type=BT_UHF_05_Zaehler, compu {phys=raw for raw 0..31}, range phys 0..31, raw 0..31, transfer-property=TRIGGERED-ON-CHANGE-WITHOUT-REPETITION, to SAM  # Zähler der UHF-Botschaft
          signal UHF_05_Data_XIX_UHF_05_XIX_E3V_CCAN: start 8, 56 bit, little-endian, data-type-policy=OVERRIDE, i-signal-type=PRIMITIVE, init-value=0, base-type=BT_UHF_05_Data, compu {phys=raw for raw 0..72057594037927935; unit Unit_None}, range phys 0..72057594037927935 Unit_None, raw 0..72057594037927935, unit=Unit_None, transfer-property=TRIGGERED-ON-CHANGE-WITHOUT-REPETITION, to SAM  # Daten der UHF-Botschaft
      frame UHF_06_XIX_E3V_CCAN: id 0x34, to SAM, frame-length=8, can-addressing-mode=STANDARD, can-frame-rx-behavior=CAN-20, can-frame-tx-behavior=CAN-20
        pdu UHF_06_XIX_E3V_CCAN: length=8, minimum-delay=0.007, transmission-mode-true-timing=event-controlled-timing={number-of-repetitions=0, repetition-period=0.0}, unused-bit-pattern=0
          signal UHF_06_Zaehler_XIX_UHF_06_XIX_E3V_CCAN: start 0, 5 bit, little-endian, data-type-policy=OVERRIDE, i-signal-type=PRIMITIVE, init-value=0, base-type=BT_UHF_06_Zaehler, compu {phys=raw for raw 0..31}, range phys 0..31, raw 0..31, transfer-property=TRIGGERED-ON-CHANGE-WITHOUT-REPETITION, to SAM  # Zähler der UHF-Botschaft
          signal UHF_06_Data_XIX_UHF_06_XIX_E3V_CCAN: start 8, 56 bit, little-endian, data-type-policy=OVERRIDE, i-signal-type=PRIMITIVE, init-value=0, base-type=BT_UHF_06_Data, compu {phys=raw for raw 0..72057594037927935; unit Unit_None}, range phys 0..72057594037927935 Unit_None, raw 0..72057594037927935, unit=Unit_None, transfer-property=TRIGGERED-ON-CHANGE-WITHOUT-REPETITION, to SAM  # Daten der UHF-Botschaft
      frame UHF_07_XIX_E3V_CCAN: id 0x35, to SAM, frame-length=8, can-addressing-mode=STANDARD, can-frame-rx-behavior=CAN-20, can-frame-tx-behavior=CAN-20
        pdu UHF_07_XIX_E3V_CCAN: length=8, minimum-delay=0.007, transmission-mode-true-timing=event-controlled-timing={number-of-repetitions=0, repetition-period=0.0}, unused-bit-pattern=0
          signal UHF_07_Zaehler_XIX_UHF_07_XIX_E3V_CCAN: start 0, 5 bit, little-endian, data-type-policy=OVERRIDE, i-signal-type=PRIMITIVE, init-value=0, base-type=BT_UHF_07_Zaehler, compu {phys=raw for raw 0..31}, range phys 0..31, raw 0..31, transfer-property=TRIGGERED-ON-CHANGE-WITHOUT-REPETITION, to SAM  # Zähler der UHF-Botschaft
          signal UHF_07_Data_XIX_UHF_07_XIX_E3V_CCAN: start 8, 56 bit, little-endian, data-type-policy=OVERRIDE, i-signal-type=PRIMITIVE, init-value=0, base-type=BT_UHF_07_Data, compu {phys=raw for raw 0..72057594037927935; unit Unit_None}, range phys 0..72057594037927935 Unit_None, raw 0..72057594037927935, unit=Unit_None, transfer-property=TRIGGERED-ON-CHANGE-WITHOUT-REPETITION, to SAM  # Daten der UHF-Botschaft
      frame UHF_08_XIX_E3V_CCAN: id 0x36, to SAM, frame-length=8, can-addressing-mode=STANDARD, can-frame-rx-behavior=CAN-20, can-frame-tx-behavior=CAN-20
        pdu UHF_08_XIX_E3V_CCAN: length=8, minimum-delay=0.007, transmission-mode-true-timing=event-controlled-timing={number-of-repetitions=0, repetition-period=0.0}, unused-bit-pattern=0
          signal UHF_08_Zaehler_XIX_UHF_08_XIX_E3V_CCAN: start 0, 5 bit, little-endian, data-type-policy=OVERRIDE, i-signal-type=PRIMITIVE, init-value=0, base-type=BT_UHF_08_Zaehler, compu {phys=raw for raw 0..31}, range phys 0..31, raw 0..31, transfer-property=TRIGGERED-ON-CHANGE-WITHOUT-REPETITION, to SAM  # Zähler der UHF-Botschaft
          signal UHF_08_Data_XIX_UHF_08_XIX_E3V_CCAN: start 8, 56 bit, little-endian, data-type-policy=OVERRIDE, i-signal-type=PRIMITIVE, init-value=0, base-type=BT_UHF_08_Data, compu {phys=raw for raw 0..72057594037927935; unit Unit_None}, range phys 0..72057594037927935 Unit_None, raw 0..72057594037927935, unit=Unit_None, transfer-property=TRIGGERED-ON-CHANGE-WITHOUT-REPETITION, to SAM  # Daten der UHF-Botschaft
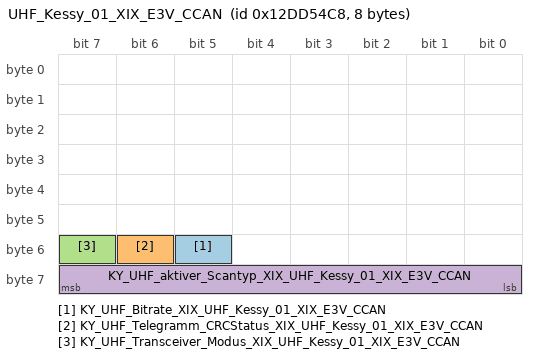
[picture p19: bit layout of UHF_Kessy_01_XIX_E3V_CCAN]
      frame UHF_Kessy_01_XIX_E3V_CCAN: id 0x12DD54C8, from SAM, frame-length=8, can-addressing-mode=EXTENDED, can-frame-rx-behavior=CAN-20, can-frame-tx-behavior=CAN-20
        pdu UHF_Kessy_01_XIX_E3V_CCAN: length=8, minimum-delay=0.02, transmission-mode-true-timing={cyclic-timing={time-offset=0.0, time-period=0.2}, event-controlled-timing={number-of-repetitions=0, repetition-period=0.0}}, unused-bit-pattern=0
          signal KY_UHF_Bitrate_XIX_UHF_Kessy_01_XIX_E3V_CCAN: start 53, 1 bit, little-endian, data-type-policy=OVERRIDE, i-signal-type=PRIMITIVE, init-value=0, base-type=BT_KY_UHF_Bitrate, compu {0=Cx0_Bitrate_19200kbit_s (CM_KY_UHF_Bitrate_Cx0_Bitrate_19200kbit_s), 1=Cx1_Bitrate_7800kbit_s (CM_KY_UHF_Bitrate_Cx1_Bitrate_7800kbit_s)}, range raw 0..1, transfer-property=TRIGGERED-ON-CHANGE-WITHOUT-REPETITION  # Signalisiert Kessy, mit welcher Bitrate der UHF-Transceiver sendet oder empfängt.
          signal KY_UHF_Telegramm_CRCStatus_XIX_UHF_Kessy_01_XIX_E3V_CCAN: start 54, 1 bit, little-endian, data-type-policy=OVERRIDE, i-signal-type=PRIMITIVE, init-value=0, base-type=BT_KY_UHF_Telegramm_CRCStatus, compu {0=Cx0_ungueltig (CM_KY_UHF_Telegramm_CRCStatus_Cx0_ungueltig), 1=Cx1_gueltig (CM_KY_UHF_Telegramm_CRCStatus_Cx1_gueltig)}, range raw 0..1, transfer-property=TRIGGERED-ON-CHANGE-WITHOUT-REPETITION  # Signalisiert den CRC-Prüfstatus eines empfangenen UHF-Telegramms
          signal KY_UHF_Transceiver_Modus_XIX_UHF_Kessy_01_XIX_E3V_CCAN: start 55, 1 bit, little-endian, data-type-policy=OVERRIDE, i-signal-type=PRIMITIVE, init-value=0, base-type=BT_KY_UHF_Transceiver_Modus, compu {0=Cx0_UHF_Senden_aktiv (CM_KY_UHF_Transceiver_Modus_Cx0_UHF_Senden_aktiv), 1=Cx1_UHF_Empfang_aktiv (CM_KY_UHF_Transceiver_Modus_Cx1_UHF_Empfang_aktiv)}, range raw 0..1, transfer-property=TRIGGERED-ON-CHANGE-WITHOUT-REPETITION  # Signalisierung ob der UHF-Transceiver im Sende- oder Empfangsmodus ist.
          signal KY_UHF_aktiver_Scantyp_XIX_UHF_Kessy_01_XIX_E3V_CCAN: start 56, 8 bit, little-endian, data-type-policy=OVERRIDE, i-signal-type=PRIMITIVE, init-value=0, base-type=BT_KY_UHF_aktiver_Scantyp, compu {0=Cx0_inaktiv (CM_KY_UHF_aktiver_Scantyp_Cx0_inaktiv), 1=Cx1_Registering_KSY (CM_KY_UHF_aktiver_Scantyp_Cx1_Registering_KSY), 2=Cx2_Entry_Authentifikation_KSY (CM_KY_UHF_aktiver_Scantyp_Cx2_Entry_Authentifikation_KSY), 3=Cx3_Exit_Authentifikation_KSY (CM_KY_UHF_aktiver_Scantyp_Cx3_Exit_Authentifikation_KSY), 4=Cx4_GO_Authentifikation_KSY (CM_KY_UHF_aktiver_Scantyp_Cx4_GO_Authentifikation_KSY), 5=Cx5_GO_Authentifikation_UDATA_KSY (CM_KY_UHF_aktiver_Scantyp_Cx5_GO_Authentifikation_UDATA_KSY), 6=Cx6_GO_UDATA_KSY (CM_KY_UHF_aktiver_Scantyp_Cx6_GO_UDATA_KSY), 16=Cx10_FZV_Telegramm_FZV (CM_KY_UHF_aktiver_Scantyp_Cx10_FZV_Telegramm_FZV), 17=Cx11_ComfortFrame_FZV (CM_KY_UHF_aktiver_Scantyp_Cx11_ComfortFrame_FZV), 18=Cx12_ReleaseFrame_FZV (CM_KY_UHF_aktiver_Scantyp_Cx12_ReleaseFrame_FZV), 32=Cx20_LF_Polling_Response_WEL (CM_KY_UHF_aktiver_Scantyp_Cx20_LF_Polling_Response_WEL), 48=Cx30_ServiceKey_Frame1_SK (CM_KY_UHF_aktiver_Scantyp_Cx30_ServiceKey_Frame1_SK), 49=Cx31_ServiceKey_Frame2_SK (CM_KY_UHF_aktiver_Scantyp_Cx31_ServiceKey_Frame2_SK), 50=Cx32_ServiceKey_Frame3_SK (CM_KY_UHF_aktiver_Scantyp_Cx32_ServiceKey_Frame3_SK)}, range raw 0..50, transfer-property=TRIGGERED-ON-CHANGE-WITHOUT-REPETITION  # Signalisierung aktiver UHF-Scantypen an Kessy-Funktionen die auf andere Komponenten auf dem SUBCAN ausgelagert sind.
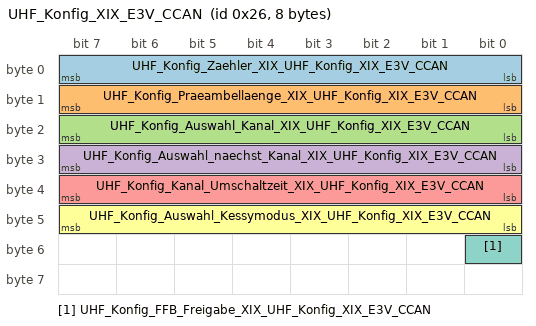
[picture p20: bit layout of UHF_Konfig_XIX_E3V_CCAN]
      frame UHF_Konfig_XIX_E3V_CCAN: id 0x26, to SAM, frame-length=8, can-addressing-mode=STANDARD, can-frame-rx-behavior=CAN-20, can-frame-tx-behavior=CAN-20
        pdu UHF_Konfig_XIX_E3V_CCAN: length=8, minimum-delay=0.007, transmission-mode-true-timing={cyclic-timing={time-offset=0.0, time-period=2.0}, event-controlled-timing={number-of-repetitions=0, repetition-period=0.0}}, unused-bit-pattern=0
          signal UHF_Konfig_Zaehler_XIX_UHF_Konfig_XIX_E3V_CCAN: start 0, 8 bit, little-endian, data-type-policy=OVERRIDE, i-signal-type=PRIMITIVE, init-value=0, base-type=BT_UHF_Konfig_Zaehler, compu {phys=raw for raw 0..255}, range phys 0..255, raw 0..255, transfer-property=TRIGGERED-ON-CHANGE-WITHOUT-REPETITION, to SAM(timeout 5 s)  # Zähler der UHF-Botschaft
          signal UHF_Konfig_Praeambellaenge_XIX_UHF_Konfig_XIX_E3V_CCAN: start 8, 8 bit, little-endian, data-type-policy=OVERRIDE, i-signal-type=PRIMITIVE, init-value=0, base-type=BT_UHF_Konfig_Praeambellaenge, compu {phys=raw for raw 0..255; unit Unit_None}, range phys 0..255 Unit_None, raw 0..255, unit=Unit_None, transfer-property=TRIGGERED-ON-CHANGE-WITHOUT-REPETITION, to SAM(timeout 5 s)  # UHF Konfiguration: Laenge der Präambel
          signal UHF_Konfig_Auswahl_Kanal_XIX_UHF_Konfig_XIX_E3V_CCAN: start 16, 8 bit, little-endian, data-type-policy=OVERRIDE, i-signal-type=PRIMITIVE, init-value=0, base-type=BT_UHF_Konfig_Auswahl_Kanal, compu {phys=raw+1 for raw 0..255; unit Unit_None}, range phys 1..256 Unit_None, raw 0..255, unit=Unit_None, transfer-property=TRIGGERED-ON-CHANGE-WITHOUT-REPETITION, to SAM(timeout 5 s)  # Kanal, auf dem gesendet oder empfangen werden soll (Tx_Ch0, Tx_Ch1, Tx_Same, Tx_Other, Released)
          signal UHF_Konfig_Auswahl_naechst_Kanal_XIX_UHF_Konfig_XIX_E3V_CCAN: start 24, 8 bit, little-endian, data-type-policy=OVERRIDE, i-signal-type=PRIMITIVE, init-value=0, base-type=BT_UHF_Konfig_Auswahl_naechst_Kanal, compu {phys=raw for raw 0..255; unit Unit_None}, range phys 0..255 Unit_None, raw 0..255, unit=Unit_None, transfer-property=TRIGGERED-ON-CHANGE-WITHOUT-REPETITION, to SAM(timeout 5 s)  # Modus, in den nach dem Senden gewechselt werden soll (Rx_Ch0, Rx_Ch1, Rx_Same, Rx_Other, PollKessy, Tx_Ch0, Tx_Ch1, Tx_Same, Tx_Other, Released)
          signal UHF_Konfig_Kanal_Umschaltzeit_XIX_UHF_Konfig_XIX_E3V_CCAN: start 32, 8 bit, little-endian, data-type-policy=OVERRIDE, i-signal-type=PRIMITIVE, init-value=0, base-type=BT_UHF_Konfig_Kanal_Umschaltzeit, compu {phys=raw for raw 0..255; unit Unit_MilliSecon}, range phys 0..255 Unit_MilliSecon, raw 0..255, unit=Unit_MilliSecon, transfer-property=TRIGGERED-ON-CHANGE-WITHOUT-REPETITION, to SAM(timeout 5 s)  # Zeit in ms ab Beginn des Sendens, nach der bei erfolglosen Lauschen auf dem in nextMode gewählten Kanal auf den anderen Kanal umgeschaltet werden soll (Parameter wird bei Channel Hopping oder Tx ignoriert)
          signal UHF_Konfig_Auswahl_Kessymodus_XIX_UHF_Konfig_XIX_E3V_CCAN: start 40, 8 bit, little-endian, data-type-policy=OVERRIDE, i-signal-type=PRIMITIVE, init-value=0, base-type=BT_UHF_Konfig_Auswahl_Kessymodus, compu {phys=raw for raw 0..255; unit Unit_None}, range phys 0..255 Unit_None, raw 0..255, unit=Unit_None, transfer-property=TRIGGERED-ON-CHANGE-WITHOUT-REPETITION, to SAM(timeout 5 s)  # Diese Meldung teilt der Transceiver-SW den Kessy-Kanal für die nächste Kessykommunikation (u.U. nach Sleep) mit.
          signal UHF_Konfig_FFB_Freigabe_XIX_UHF_Konfig_XIX_E3V_CCAN: start 48, 1 bit, little-endian, data-type-policy=OVERRIDE, i-signal-type=PRIMITIVE, init-value=0, base-type=BT_UHF_Konfig_FFB_Freigabe, compu {0=Cx0_Keine_Freigabe_der_FFB (CM_UHF_Konfig_FFB_Freigabe_Cx0_Keine_Freigabe_der_FFB), 1=Cx1_Freigabe_der_FFB_erteilt (CM_UHF_Konfig_FFB_Freigabe_Cx1_Freigabe_der_FFB_erteilt)}, range raw 0..1, transfer-property=TRIGGERED-ON-CHANGE-WITHOUT-REPETITION, to SAM(timeout 5 s)  # Freigabe des UHF-Transceivers für FFB Zusätzlich oder alternativ kann die UHF-Transceiver-SW auch nach einem Timeout umschalten.
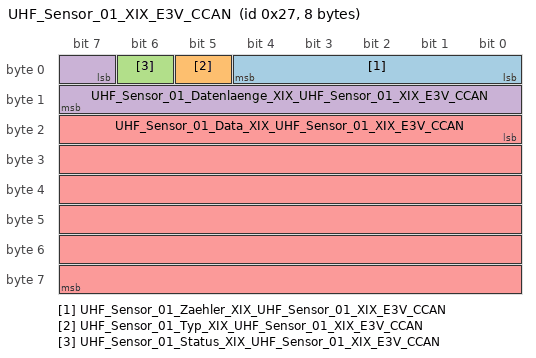
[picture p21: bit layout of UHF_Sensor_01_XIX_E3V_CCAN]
      frame UHF_Sensor_01_XIX_E3V_CCAN: id 0x27, from SAM, frame-length=8, can-addressing-mode=STANDARD, can-frame-rx-behavior=CAN-20, can-frame-tx-behavior=CAN-20
        pdu UHF_Sensor_01_XIX_E3V_CCAN: length=8, minimum-delay=0.007, transmission-mode-true-timing=event-controlled-timing={number-of-repetitions=0, repetition-period=0.0}, unused-bit-pattern=0
          signal UHF_Sensor_01_Zaehler_XIX_UHF_Sensor_01_XIX_E3V_CCAN: start 0, 5 bit, little-endian, data-type-policy=OVERRIDE, i-signal-type=PRIMITIVE, init-value=0, base-type=BT_UHF_Sensor_01_Zaehler, compu {phys=raw for raw 0..31}, range phys 0..31, raw 0..31, transfer-property=TRIGGERED-ON-CHANGE-WITHOUT-REPETITION  # Zähler der UHF-Botschaft
          signal UHF_Sensor_01_Typ_XIX_UHF_Sensor_01_XIX_E3V_CCAN: start 5, 1 bit, little-endian, data-type-policy=OVERRIDE, i-signal-type=PRIMITIVE, init-value=0, base-type=BT_UHF_Sensor_01_Typ, compu {0=Cx0_CRC (CM_UHF_Sensor_01_Typ_Cx0_CRC), 1=Cx1_Response (CM_UHF_Sensor_01_Typ_Cx1_Response)}, range raw 0..1, transfer-property=TRIGGERED-ON-CHANGE-WITHOUT-REPETITION  # Typ der Botschaft
          signal UHF_Sensor_01_Status_XIX_UHF_Sensor_01_XIX_E3V_CCAN: start 6, 1 bit, little-endian, data-type-policy=OVERRIDE, i-signal-type=PRIMITIVE, init-value=0, base-type=BT_UHF_Sensor_01_Status, compu {0=Cx0_False (CM_UHF_Sensor_01_Status_Cx0_False), 1=Cx1_True (CM_UHF_Sensor_01_Status_Cx1_True)}, range raw 0..1, transfer-property=TRIGGERED-ON-CHANGE-WITHOUT-REPETITION  # Status der Botschaft
          signal UHF_Sensor_01_Datenlaenge_XIX_UHF_Sensor_01_XIX_E3V_CCAN: start 7, 9 bit, little-endian, data-type-policy=OVERRIDE, i-signal-type=PRIMITIVE, init-value=0, base-type=BT_UHF_Sensor_01_Datenlaenge, compu {phys=raw for raw 0..511; unit Unit_Bit}, range phys 0..511 Unit_Bit, raw 0..511, unit=Unit_Bit, transfer-property=TRIGGERED-ON-CHANGE-WITHOUT-REPETITION  # Anzahl der zu übertragenden Bits in der UHF-Botschaft
          signal UHF_Sensor_01_Data_XIX_UHF_Sensor_01_XIX_E3V_CCAN: start 16, 48 bit, little-endian, data-type-policy=OVERRIDE, i-signal-type=PRIMITIVE, init-value=0, base-type=BT_UHF_Sensor_01_Data, compu {phys=raw for raw 0..281474976710655; unit Unit_None}, range phys 0..281474976710655 Unit_None, raw 0..281474976710655, unit=Unit_None, transfer-property=TRIGGERED-ON-CHANGE-WITHOUT-REPETITION  # Daten der UHF-Botschaft
      frame UHF_Sensor_02_XIX_E3V_CCAN: id 0x28, from SAM, frame-length=8, can-addressing-mode=STANDARD, can-frame-rx-behavior=CAN-20, can-frame-tx-behavior=CAN-20
        pdu UHF_Sensor_02_XIX_E3V_CCAN: length=8, minimum-delay=0.007, transmission-mode-true-timing=event-controlled-timing={number-of-repetitions=0, repetition-period=0.0}, unused-bit-pattern=0
          signal UHF_Sensor_02_Zaehler_XIX_UHF_Sensor_02_XIX_E3V_CCAN: start 0, 5 bit, little-endian, data-type-policy=OVERRIDE, i-signal-type=PRIMITIVE, init-value=0, base-type=BT_UHF_Sensor_02_Zaehler, compu {phys=raw for raw 0..31}, range phys 0..31, raw 0..31, transfer-property=TRIGGERED-ON-CHANGE-WITHOUT-REPETITION  # Zähler der UHF-Botschaft
          signal UHF_Sensor_02_Data_XIX_UHF_Sensor_02_XIX_E3V_CCAN: start 8, 56 bit, little-endian, data-type-policy=OVERRIDE, i-signal-type=PRIMITIVE, init-value=0, base-type=BT_UHF_Sensor_02_Data, compu {phys=raw for raw 0..72057594037927935; unit Unit_None}, range phys 0..72057594037927935 Unit_None, raw 0..72057594037927935, unit=Unit_None, transfer-property=TRIGGERED-ON-CHANGE-WITHOUT-REPETITION  # Daten der UHF-Botschaft
      frame UHF_Sensor_03_XIX_E3V_CCAN: id 0x29, from SAM, frame-length=8, can-addressing-mode=STANDARD, can-frame-rx-behavior=CAN-20, can-frame-tx-behavior=CAN-20
        pdu UHF_Sensor_03_XIX_E3V_CCAN: length=8, minimum-delay=0.007, transmission-mode-true-timing=event-controlled-timing={number-of-repetitions=0, repetition-period=0.0}, unused-bit-pattern=0
          signal UHF_Sensor_03_Zaehler_XIX_UHF_Sensor_03_XIX_E3V_CCAN: start 0, 5 bit, little-endian, data-type-policy=OVERRIDE, i-signal-type=PRIMITIVE, init-value=0, base-type=BT_UHF_Sensor_03_Zaehler, compu {phys=raw for raw 0..31}, range phys 0..31, raw 0..31, transfer-property=TRIGGERED-ON-CHANGE-WITHOUT-REPETITION  # Zähler der UHF-Botschaft
          signal UHF_Sensor_03_Data_XIX_UHF_Sensor_03_XIX_E3V_CCAN: start 8, 56 bit, little-endian, data-type-policy=OVERRIDE, i-signal-type=PRIMITIVE, init-value=0, base-type=BT_UHF_Sensor_03_Data, compu {phys=raw for raw 0..72057594037927935; unit Unit_None}, range phys 0..72057594037927935 Unit_None, raw 0..72057594037927935, unit=Unit_None, transfer-property=TRIGGERED-ON-CHANGE-WITHOUT-REPETITION  # Daten der UHF-Botschaft
      frame UHF_Sensor_04_XIX_E3V_CCAN: id 0x2A, from SAM, frame-length=8, can-addressing-mode=STANDARD, can-frame-rx-behavior=CAN-20, can-frame-tx-behavior=CAN-20
        pdu UHF_Sensor_04_XIX_E3V_CCAN: length=8, minimum-delay=0.007, transmission-mode-true-timing=event-controlled-timing={number-of-repetitions=0, repetition-period=0.0}, unused-bit-pattern=0
          signal UHF_Sensor_04_Zaehler_XIX_UHF_Sensor_04_XIX_E3V_CCAN: start 0, 5 bit, little-endian, data-type-policy=OVERRIDE, i-signal-type=PRIMITIVE, init-value=0, base-type=BT_UHF_Sensor_04_Zaehler, compu {phys=raw for raw 0..31}, range phys 0..31, raw 0..31, transfer-property=TRIGGERED-ON-CHANGE-WITHOUT-REPETITION  # Zähler der UHF-Botschaft
          signal UHF_Sensor_04_Data_XIX_UHF_Sensor_04_XIX_E3V_CCAN: start 8, 56 bit, little-endian, data-type-policy=OVERRIDE, i-signal-type=PRIMITIVE, init-value=0, base-type=BT_UHF_Sensor_04_Data, compu {phys=raw for raw 0..72057594037927935; unit Unit_None}, range phys 0..72057594037927935 Unit_None, raw 0..72057594037927935, unit=Unit_None, transfer-property=TRIGGERED-ON-CHANGE-WITHOUT-REPETITION  # Daten der UHF-Botschaft
      frame UHF_Sensor_05_XIX_E3V_CCAN: id 0x2B, from SAM, frame-length=8, can-addressing-mode=STANDARD, can-frame-rx-behavior=CAN-20, can-frame-tx-behavior=CAN-20
        pdu UHF_Sensor_05_XIX_E3V_CCAN: length=8, minimum-delay=0.007, transmission-mode-true-timing=event-controlled-timing={number-of-repetitions=0, repetition-period=0.0}, unused-bit-pattern=0
          signal UHF_Sensor_05_Zaehler_XIX_UHF_Sensor_05_XIX_E3V_CCAN: start 0, 5 bit, little-endian, data-type-policy=OVERRIDE, i-signal-type=PRIMITIVE, init-value=0, base-type=BT_UHF_Sensor_05_Zaehler, compu {phys=raw for raw 0..31}, range phys 0..31, raw 0..31, transfer-property=TRIGGERED-ON-CHANGE-WITHOUT-REPETITION  # Zähler der UHF-Botschaft
          signal UHF_Sensor_05_Data_XIX_UHF_Sensor_05_XIX_E3V_CCAN: start 8, 56 bit, little-endian, data-type-policy=OVERRIDE, i-signal-type=PRIMITIVE, init-value=0, base-type=BT_UHF_Sensor_05_Data, compu {phys=raw for raw 0..72057594037927935; unit Unit_None}, range phys 0..72057594037927935 Unit_None, raw 0..72057594037927935, unit=Unit_None, transfer-property=TRIGGERED-ON-CHANGE-WITHOUT-REPETITION  # Daten der UHF-Botschaft
      frame UHF_Sensor_06_XIX_E3V_CCAN: id 0x2C, from SAM, frame-length=8, can-addressing-mode=STANDARD, can-frame-rx-behavior=CAN-20, can-frame-tx-behavior=CAN-20
        pdu UHF_Sensor_06_XIX_E3V_CCAN: length=8, minimum-delay=0.007, transmission-mode-true-timing=event-controlled-timing={number-of-repetitions=0, repetition-period=0.0}, unused-bit-pattern=0
          signal UHF_Sensor_06_Zaehler_XIX_UHF_Sensor_06_XIX_E3V_CCAN: start 0, 5 bit, little-endian, data-type-policy=OVERRIDE, i-signal-type=PRIMITIVE, init-value=0, base-type=BT_UHF_Sensor_06_Zaehler, compu {phys=raw for raw 0..31}, range phys 0..31, raw 0..31, transfer-property=TRIGGERED-ON-CHANGE-WITHOUT-REPETITION  # Zähler der UHF-Botschaft
          signal UHF_Sensor_06_Data_XIX_UHF_Sensor_06_XIX_E3V_CCAN: start 8, 56 bit, little-endian, data-type-policy=OVERRIDE, i-signal-type=PRIMITIVE, init-value=0, base-type=BT_UHF_Sensor_06_Data, compu {phys=raw for raw 0..72057594037927935; unit Unit_None}, range phys 0..72057594037927935 Unit_None, raw 0..72057594037927935, unit=Unit_None, transfer-property=TRIGGERED-ON-CHANGE-WITHOUT-REPETITION  # Daten der UHF-Botschaft
      frame UHF_Sensor_07_XIX_E3V_CCAN: id 0x2D, from SAM, frame-length=8, can-addressing-mode=STANDARD, can-frame-rx-behavior=CAN-20, can-frame-tx-behavior=CAN-20
        pdu UHF_Sensor_07_XIX_E3V_CCAN: length=8, minimum-delay=0.007, transmission-mode-true-timing=event-controlled-timing={number-of-repetitions=0, repetition-period=0.0}, unused-bit-pattern=0
          signal UHF_Sensor_07_Zaehler_XIX_UHF_Sensor_07_XIX_E3V_CCAN: start 0, 5 bit, little-endian, data-type-policy=OVERRIDE, i-signal-type=PRIMITIVE, init-value=0, base-type=BT_UHF_Sensor_07_Zaehler, compu {phys=raw for raw 0..31}, range phys 0..31, raw 0..31, transfer-property=TRIGGERED-ON-CHANGE-WITHOUT-REPETITION  # Zähler der UHF-Botschaft
          signal UHF_Sensor_07_Data_XIX_UHF_Sensor_07_XIX_E3V_CCAN: start 8, 56 bit, little-endian, data-type-policy=OVERRIDE, i-signal-type=PRIMITIVE, init-value=0, base-type=BT_UHF_Sensor_07_Data, compu {phys=raw for raw 0..72057594037927935; unit Unit_None}, range phys 0..72057594037927935 Unit_None, raw 0..72057594037927935, unit=Unit_None, transfer-property=TRIGGERED-ON-CHANGE-WITHOUT-REPETITION  # Daten der UHF-Botschaft
      frame UHF_Sensor_08_XIX_E3V_CCAN: id 0x2E, from SAM, frame-length=8, can-addressing-mode=STANDARD, can-frame-rx-behavior=CAN-20, can-frame-tx-behavior=CAN-20
        pdu UHF_Sensor_08_XIX_E3V_CCAN: length=8, minimum-delay=0.007, transmission-mode-true-timing=event-controlled-timing={number-of-repetitions=0, repetition-period=0.0}, unused-bit-pattern=0
          signal UHF_Sensor_08_Zaehler_XIX_UHF_Sensor_08_XIX_E3V_CCAN: start 0, 5 bit, little-endian, data-type-policy=OVERRIDE, i-signal-type=PRIMITIVE, init-value=0, base-type=BT_UHF_Sensor_08_Zaehler, compu {phys=raw for raw 0..31}, range phys 0..31, raw 0..31, transfer-property=TRIGGERED-ON-CHANGE-WITHOUT-REPETITION  # Zähler der UHF-Botschaft
          signal UHF_Sensor_08_Data_XIX_UHF_Sensor_08_XIX_E3V_CCAN: start 8, 56 bit, little-endian, data-type-policy=OVERRIDE, i-signal-type=PRIMITIVE, init-value=0, base-type=BT_UHF_Sensor_08_Data, compu {phys=raw for raw 0..72057594037927935; unit Unit_None}, range phys 0..72057594037927935 Unit_None, raw 0..72057594037927935, unit=Unit_None, transfer-property=TRIGGERED-ON-CHANGE-WITHOUT-REPETITION  # Daten der UHF-Botschaft
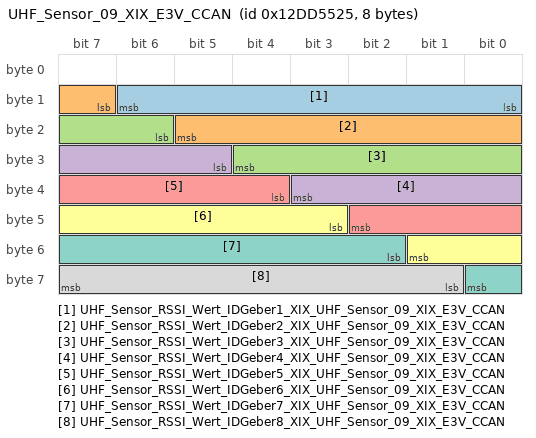
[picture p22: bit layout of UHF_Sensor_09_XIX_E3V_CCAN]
      frame UHF_Sensor_09_XIX_E3V_CCAN: id 0x12DD5525, from SAM, frame-length=8, can-addressing-mode=EXTENDED, can-frame-rx-behavior=CAN-20, can-frame-tx-behavior=CAN-20
        pdu UHF_Sensor_09_XIX_E3V_CCAN: length=8, minimum-delay=0.02, transmission-mode-true-timing={cyclic-timing={time-offset=0.0, time-period=0.2}, event-controlled-timing={number-of-repetitions=0, repetition-period=0.0}}, unused-bit-pattern=0
          signal UHF_Sensor_RSSI_Wert_IDGeber1_XIX_UHF_Sensor_09_XIX_E3V_CCAN: start 8, 7 bit, little-endian, data-type-policy=OVERRIDE, i-signal-type=PRIMITIVE, init-value=126, base-type=BT_UHF_Sensor_RSSI_Wert_IDGeber1, invalid-value=Invalid_UHF_Sensor_RSSI_Wert_IDGeber1_XIX_UHF_Sensor_09_XIX_E3V_CCAN:127, compu {phys=raw for raw 0..100, 126=Cx7e_Init (CM_UHF_Sensor_RSSI_Wert_IDGeber1_Cx7e_Init), 127=Cx7f_Fehler (CM_UHF_Sensor_RSSI_Wert_IDGeber1_Cx7f_Fehler); unit Unit_PerCent}, range phys 0..100 Unit_PerCent, raw 0..127, unit=Unit_PerCent, transfer-property=TRIGGERED-ON-CHANGE-WITHOUT-REPETITION  # Vom UHF-Transceiver empfangener zu einem UHF-Telegramm zugehöriger RSSI-Wert des ID-Geber, welcher normiert bereitgestellt wird.
          signal UHF_Sensor_RSSI_Wert_IDGeber2_XIX_UHF_Sensor_09_XIX_E3V_CCAN: start 15, 7 bit, little-endian, data-type-policy=OVERRIDE, i-signal-type=PRIMITIVE, init-value=126, base-type=BT_UHF_Sensor_RSSI_Wert_IDGeber2, invalid-value=Invalid_UHF_Sensor_RSSI_Wert_IDGeber2_XIX_UHF_Sensor_09_XIX_E3V_CCAN:127, compu {phys=raw for raw 0..100, 126=Cx7e_Init (CM_UHF_Sensor_RSSI_Wert_IDGeber2_Cx7e_Init), 127=Cx7f_Fehler (CM_UHF_Sensor_RSSI_Wert_IDGeber2_Cx7f_Fehler); unit Unit_PerCent}, range phys 0..100 Unit_PerCent, raw 0..127, unit=Unit_PerCent, transfer-property=TRIGGERED-ON-CHANGE-WITHOUT-REPETITION  # Vom UHF-Transceiver empfangener zu einem UHF-Telegramm zugehöriger RSSI-Wert des ID-Geber, welcher normiert bereitgestellt wird.
          signal UHF_Sensor_RSSI_Wert_IDGeber3_XIX_UHF_Sensor_09_XIX_E3V_CCAN: start 22, 7 bit, little-endian, data-type-policy=OVERRIDE, i-signal-type=PRIMITIVE, init-value=126, base-type=BT_UHF_Sensor_RSSI_Wert_IDGeber3, invalid-value=Invalid_UHF_Sensor_RSSI_Wert_IDGeber3_XIX_UHF_Sensor_09_XIX_E3V_CCAN:127, compu {phys=raw for raw 0..100, 126=Cx7e_Init (CM_UHF_Sensor_RSSI_Wert_IDGeber3_Cx7e_Init), 127=Cx7f_Fehler (CM_UHF_Sensor_RSSI_Wert_IDGeber3_Cx7f_Fehler); unit Unit_PerCent}, range phys 0..100 Unit_PerCent, raw 0..127, unit=Unit_PerCent, transfer-property=TRIGGERED-ON-CHANGE-WITHOUT-REPETITION  # Vom UHF-Transceiver empfangener zu einem UHF-Telegramm zugehöriger RSSI-Wert des ID-Geber, welcher normiert bereitgestellt wird.
          signal UHF_Sensor_RSSI_Wert_IDGeber4_XIX_UHF_Sensor_09_XIX_E3V_CCAN: start 29, 7 bit, little-endian, data-type-policy=OVERRIDE, i-signal-type=PRIMITIVE, init-value=126, base-type=BT_UHF_Sensor_RSSI_Wert_IDGeber4, invalid-value=Invalid_UHF_Sensor_RSSI_Wert_IDGeber4_XIX_UHF_Sensor_09_XIX_E3V_CCAN:127, compu {phys=raw for raw 0..100, 126=Cx7e_Init (CM_UHF_Sensor_RSSI_Wert_IDGeber4_Cx7e_Init), 127=Cx7f_Fehler (CM_UHF_Sensor_RSSI_Wert_IDGeber4_Cx7f_Fehler); unit Unit_PerCent}, range phys 0..100 Unit_PerCent, raw 0..127, unit=Unit_PerCent, transfer-property=TRIGGERED-ON-CHANGE-WITHOUT-REPETITION  # Vom UHF-Transceiver empfangener zu einem UHF-Telegramm zugehöriger RSSI-Wert des ID-Geber, welcher normiert bereitgestellt wird.
          signal UHF_Sensor_RSSI_Wert_IDGeber5_XIX_UHF_Sensor_09_XIX_E3V_CCAN: start 36, 7 bit, little-endian, data-type-policy=OVERRIDE, i-signal-type=PRIMITIVE, init-value=126, base-type=BT_UHF_Sensor_RSSI_Wert_IDGeber5, invalid-value=Invalid_UHF_Sensor_RSSI_Wert_IDGeber5_XIX_UHF_Sensor_09_XIX_E3V_CCAN:127, compu {phys=raw for raw 0..100, 126=Cx7e_Init (CM_UHF_Sensor_RSSI_Wert_IDGeber5_Cx7e_Init), 127=Cx7f_Fehler (CM_UHF_Sensor_RSSI_Wert_IDGeber5_Cx7f_Fehler); unit Unit_PerCent}, range phys 0..100 Unit_PerCent, raw 0..127, unit=Unit_PerCent, transfer-property=TRIGGERED-ON-CHANGE-WITHOUT-REPETITION  # Vom UHF-Transceiver empfangener zu einem UHF-Telegramm zugehöriger RSSI-Wert des ID-Geber, welcher normiert bereitgestellt wird.
          signal UHF_Sensor_RSSI_Wert_IDGeber6_XIX_UHF_Sensor_09_XIX_E3V_CCAN: start 43, 7 bit, little-endian, data-type-policy=OVERRIDE, i-signal-type=PRIMITIVE, init-value=126, base-type=BT_UHF_Sensor_RSSI_Wert_IDGeber6, invalid-value=Invalid_UHF_Sensor_RSSI_Wert_IDGeber6_XIX_UHF_Sensor_09_XIX_E3V_CCAN:127, compu {phys=raw for raw 0..100, 126=Cx7e_Init (CM_UHF_Sensor_RSSI_Wert_IDGeber6_Cx7e_Init), 127=Cx7f_Fehler (CM_UHF_Sensor_RSSI_Wert_IDGeber6_Cx7f_Fehler); unit Unit_PerCent}, range phys 0..100 Unit_PerCent, raw 0..127, unit=Unit_PerCent, transfer-property=TRIGGERED-ON-CHANGE-WITHOUT-REPETITION  # Vom UHF-Transceiver empfangener zu einem UHF-Telegramm zugehöriger RSSI-Wert des ID-Geber, welcher normiert bereitgestellt wird.
          signal UHF_Sensor_RSSI_Wert_IDGeber7_XIX_UHF_Sensor_09_XIX_E3V_CCAN: start 50, 7 bit, little-endian, data-type-policy=OVERRIDE, i-signal-type=PRIMITIVE, init-value=126, base-type=BT_UHF_Sensor_RSSI_Wert_IDGeber7, invalid-value=Invalid_UHF_Sensor_RSSI_Wert_IDGeber7_XIX_UHF_Sensor_09_XIX_E3V_CCAN:127, compu {phys=raw for raw 0..100, 126=Cx7e_Init (CM_UHF_Sensor_RSSI_Wert_IDGeber7_Cx7e_Init), 127=Cx7f_Fehler (CM_UHF_Sensor_RSSI_Wert_IDGeber7_Cx7f_Fehler); unit Unit_PerCent}, range phys 0..100 Unit_PerCent, raw 0..127, unit=Unit_PerCent, transfer-property=TRIGGERED-ON-CHANGE-WITHOUT-REPETITION  # Vom UHF-Transceiver empfangener zu einem UHF-Telegramm zugehöriger RSSI-Wert des ID-Geber, welcher normiert bereitgestellt wird.
          signal UHF_Sensor_RSSI_Wert_IDGeber8_XIX_UHF_Sensor_09_XIX_E3V_CCAN: start 57, 7 bit, little-endian, data-type-policy=OVERRIDE, i-signal-type=PRIMITIVE, init-value=126, base-type=BT_UHF_Sensor_RSSI_Wert_IDGeber8, invalid-value=Invalid_UHF_Sensor_RSSI_Wert_IDGeber8_XIX_UHF_Sensor_09_XIX_E3V_CCAN:127, compu {phys=raw for raw 0..100, 126=Cx7e_Init (CM_UHF_Sensor_RSSI_Wert_IDGeber8_Cx7e_Init), 127=Cx7f_Fehler (CM_UHF_Sensor_RSSI_Wert_IDGeber8_Cx7f_Fehler); unit Unit_PerCent}, range phys 0..100 Unit_PerCent, raw 0..127, unit=Unit_PerCent, transfer-property=TRIGGERED-ON-CHANGE-WITHOUT-REPETITION  # Vom UHF-Transceiver empfangener zu einem UHF-Telegramm zugehöriger RSSI-Wert des ID-Geber, welcher normiert bereitgestellt wird.
      frame UHF_TranspID_01_XIX_E3V_CCAN: id 0x16A954EC, to SAM, frame-length=8, can-addressing-mode=EXTENDED, can-frame-rx-behavior=CAN-20, can-frame-tx-behavior=CAN-20
        pdu UHF_TranspID_01_XIX_E3V_CCAN: length=8, minimum-delay=0.02, transmission-mode-true-timing={cyclic-timing={time-offset=0.0, time-period=2.0}, event-controlled-timing={number-of-repetitions=3, repetition-period=0.5}}, unused-bit-pattern=0
          signal UHF_TranspID_01_XIX_UHF_TranspID_01_XIX_E3V_CCAN: start 0, 32 bit, little-endian, data-type-policy=OVERRIDE, i-signal-type=PRIMITIVE, init-value=0, base-type=BT_UHF_TranspID_01, compu {phys=raw for raw 0..4294967295; unit Unit_None}, range phys 0..4294967295 Unit_None, raw 0..4294967295, unit=Unit_None, transfer-property=TRIGGERED-ON-CHANGE, to SAM(timeout 5 s)  # Transponder ID der FFB
          signal UHF_TranspID_02_XIX_UHF_TranspID_01_XIX_E3V_CCAN: start 32, 32 bit, little-endian, data-type-policy=OVERRIDE, i-signal-type=PRIMITIVE, init-value=0, base-type=BT_UHF_TranspID_02, compu {phys=raw for raw 0..4294967295; unit Unit_None}, range phys 0..4294967295 Unit_None, raw 0..4294967295, unit=Unit_None, transfer-property=TRIGGERED-ON-CHANGE, to SAM(timeout 5 s)  # Transponder ID der FFB
      frame UHF_TranspID_02_XIX_E3V_CCAN: id 0x16A954ED, to SAM, frame-length=8, can-addressing-mode=EXTENDED, can-frame-rx-behavior=CAN-20, can-frame-tx-behavior=CAN-20
        pdu UHF_TranspID_02_XIX_E3V_CCAN: length=8, minimum-delay=0.02, transmission-mode-true-timing={cyclic-timing={time-offset=0.0, time-period=2.0}, event-controlled-timing={number-of-repetitions=3, repetition-period=0.5}}, unused-bit-pattern=0
          signal UHF_TranspID_03_XIX_UHF_TranspID_02_XIX_E3V_CCAN: start 0, 32 bit, little-endian, data-type-policy=OVERRIDE, i-signal-type=PRIMITIVE, init-value=0, base-type=BT_UHF_TranspID_03, compu {phys=raw for raw 0..4294967295; unit Unit_None}, range phys 0..4294967295 Unit_None, raw 0..4294967295, unit=Unit_None, transfer-property=TRIGGERED-ON-CHANGE, to SAM(timeout 5 s)  # Transponder ID der FFB
          signal UHF_TranspID_04_XIX_UHF_TranspID_02_XIX_E3V_CCAN: start 32, 32 bit, little-endian, data-type-policy=OVERRIDE, i-signal-type=PRIMITIVE, init-value=0, base-type=BT_UHF_TranspID_04, compu {phys=raw for raw 0..4294967295; unit Unit_None}, range phys 0..4294967295 Unit_None, raw 0..4294967295, unit=Unit_None, transfer-property=TRIGGERED-ON-CHANGE, to SAM(timeout 5 s)  # Transponder ID der FFB
      frame UHF_TranspID_03_XIX_E3V_CCAN: id 0x16A954EE, to SAM, frame-length=8, can-addressing-mode=EXTENDED, can-frame-rx-behavior=CAN-20, can-frame-tx-behavior=CAN-20
        pdu UHF_TranspID_03_XIX_E3V_CCAN: length=8, minimum-delay=0.02, transmission-mode-true-timing={cyclic-timing={time-offset=0.0, time-period=2.0}, event-controlled-timing={number-of-repetitions=3, repetition-period=0.5}}, unused-bit-pattern=0
          signal UHF_TranspID_05_XIX_UHF_TranspID_03_XIX_E3V_CCAN: start 0, 32 bit, little-endian, data-type-policy=OVERRIDE, i-signal-type=PRIMITIVE, init-value=0, base-type=BT_UHF_TranspID_05, compu {phys=raw for raw 0..4294967295; unit Unit_None}, range phys 0..4294967295 Unit_None, raw 0..4294967295, unit=Unit_None, transfer-property=TRIGGERED-ON-CHANGE, to SAM(timeout 5 s)  # Transponder ID der FFB
          signal UHF_TranspID_06_XIX_UHF_TranspID_03_XIX_E3V_CCAN: start 32, 32 bit, little-endian, data-type-policy=OVERRIDE, i-signal-type=PRIMITIVE, init-value=0, base-type=BT_UHF_TranspID_06, compu {phys=raw for raw 0..4294967295; unit Unit_None}, range phys 0..4294967295 Unit_None, raw 0..4294967295, unit=Unit_None, transfer-property=TRIGGERED-ON-CHANGE, to SAM(timeout 5 s)  # Transponder ID der FFB
      frame UHF_TranspID_04_XIX_E3V_CCAN: id 0x16A954EF, to SAM, frame-length=8, can-addressing-mode=EXTENDED, can-frame-rx-behavior=CAN-20, can-frame-tx-behavior=CAN-20
        pdu UHF_TranspID_04_XIX_E3V_CCAN: length=8, minimum-delay=0.02, transmission-mode-true-timing={cyclic-timing={time-offset=0.0, time-period=2.0}, event-controlled-timing={number-of-repetitions=3, repetition-period=0.5}}, unused-bit-pattern=0
          signal UHF_TranspID_07_XIX_UHF_TranspID_04_XIX_E3V_CCAN: start 0, 32 bit, little-endian, data-type-policy=OVERRIDE, i-signal-type=PRIMITIVE, init-value=0, base-type=BT_UHF_TranspID_07, compu {phys=raw for raw 0..4294967295; unit Unit_None}, range phys 0..4294967295 Unit_None, raw 0..4294967295, unit=Unit_None, transfer-property=TRIGGERED-ON-CHANGE, to SAM(timeout 5 s)  # Transponder ID der FFB
          signal UHF_TranspID_08_XIX_UHF_TranspID_04_XIX_E3V_CCAN: start 32, 32 bit, little-endian, data-type-policy=OVERRIDE, i-signal-type=PRIMITIVE, init-value=0, base-type=BT_UHF_TranspID_08, compu {phys=raw for raw 0..4294967295; unit Unit_None}, range phys 0..4294967295 Unit_None, raw 0..4294967295, unit=Unit_None, transfer-property=TRIGGERED-ON-CHANGE, to SAM(timeout 5 s)  # Transponder ID der FFB
  can cluster E3V_K2CANFD: baudrate=500000, protocol-name=CAN, protocol-version=2.0, bus-off-recovery={bor-counter-l-1-to-l-2=1, bor-time-l-1=0.05, bor-time-l-2=0.2}, can-fd-baudrate=500000  # CAN FD Komfort
    can physical channel CHNL: comm-connectors=CN_E3V_K2CANFD
      frame ADecu1_01_XIX_E3V_K2CANFD: id 0x1A555835, to SAM, frame-length=8, can-addressing-mode=EXTENDED, can-frame-rx-behavior=CAN-FD, can-frame-tx-behavior=CAN-FD
        pdu ADecu1_01_XIX_E3V_K2CANFD_E2E: length=8, transmission-mode-true-timing=event-controlled-timing={number-of-repetitions=0, repetition-period=0.0}, unused-bit-pattern=0  # Fuer die Botschaft ist das Cyclic-Timing 0.5 zu verwenden.
          signal ADecu1_01_CRC_XIX_ADecu1_01_XIX_E3V_K2CANFD: start 0, 8 bit, little-endian, data-type-policy=OVERRIDE, i-signal-type=PRIMITIVE, init-value=0, base-type=BT_ADecu1_01_CRC, compu {phys=raw for raw 0..255}, range phys 0..255, raw 0..255, to SAM(timeout 5 s)  # Für MLB: Berechnung siehe Lastenheft "Kommunikationsabsicherung für FlexRay und CAN" Ab MQB und MLBevo: Berechnung siehe Lastenheft "End-to-End Kommunikationsabsicherung" Endwerte siehe Begleitdokument "S-PDU Kennungsfolgen"
          signal ADecu1_01_BZ_XIX_ADecu1_01_XIX_E3V_K2CANFD: start 8, 4 bit, little-endian, data-type-policy=OVERRIDE, i-signal-type=PRIMITIVE, init-value=0, base-type=BT_ADecu1_01_BZ, compu {phys=raw for raw 0..15}, range phys 0..15, raw 0..15, to SAM(timeout 5 s)
          signal ADecu1_ORUDataIndex_XIX_ADecu1_01_XIX_E3V_K2CANFD: start 12, 4 bit, little-endian, data-type-policy=OVERRIDE, i-signal-type=PRIMITIVE, init-value=0, base-type=BT_ADecu1_ORUDataIndex, compu {phys=raw for raw 0..15}, range phys 0..15, raw 0..15, to SAM(timeout 5 s)  # Data index of the last 6 Bytes
          signal ADecu1_ORUData_XIX_ADecu1_01_XIX_E3V_K2CANFD: start 16, 48 bit, little-endian, data-type-policy=OVERRIDE, i-signal-type=PRIMITIVE, init-value=0, base-type=BT_ADecu1_ORUData, compu {phys=raw for raw 0..281474976710655}, range phys 0..281474976710655, raw 0..281474976710655, to SAM(timeout 5 s)  # "ORU information multiplexed - diagnostic address (2 bytes) - HW-part no (11 bytes) - HW version no. (3 bytes) - SW version no. (4 bytes) - IVD-P Value (64 bytes) need to be sent in combination with ORUDataIndex"
          mapping SG_ADecu1_01_XIX_E3V_K2CANFD: i-signal-group=SG_ADecu1_01_XIX_E3V_K2CANFD, transfer-property=TRIGGERED-WITHOUT-REPETITION
      frame ADecu2_01_XIX_E3V_K2CANFD: id 0x1A555836, to SAM, frame-length=8, can-addressing-mode=EXTENDED, can-frame-rx-behavior=CAN-FD, can-frame-tx-behavior=CAN-FD
        pdu ADecu2_01_XIX_E3V_K2CANFD_E2E: length=8, transmission-mode-true-timing=event-controlled-timing={number-of-repetitions=0, repetition-period=0.0}, unused-bit-pattern=0  # Fuer die Botschaft ist das Cyclic-Timing 0.5 zu verwenden.
          signal ADecu2_01_CRC_XIX_ADecu2_01_XIX_E3V_K2CANFD: start 0, 8 bit, little-endian, data-type-policy=OVERRIDE, i-signal-type=PRIMITIVE, init-value=0, base-type=BT_ADecu2_01_CRC, compu {phys=raw for raw 0..255}, range phys 0..255, raw 0..255, to SAM(timeout 5 s)  # Für MLB: Berechnung siehe Lastenheft "Kommunikationsabsicherung für FlexRay und CAN" Ab MQB und MLBevo: Berechnung siehe Lastenheft "End-to-End Kommunikationsabsicherung" Endwerte siehe Begleitdokument "S-PDU Kennungsfolgen"
          signal ADecu2_01_BZ_XIX_ADecu2_01_XIX_E3V_K2CANFD: start 8, 4 bit, little-endian, data-type-policy=OVERRIDE, i-signal-type=PRIMITIVE, init-value=0, base-type=BT_ADecu2_01_BZ, compu {phys=raw for raw 0..15}, range phys 0..15, raw 0..15, to SAM(timeout 5 s)
          signal ADecu2_ORUDataIndex_XIX_ADecu2_01_XIX_E3V_K2CANFD: start 12, 4 bit, little-endian, data-type-policy=OVERRIDE, i-signal-type=PRIMITIVE, init-value=0, base-type=BT_ADecu2_ORUDataIndex, compu {phys=raw for raw 0..15}, range phys 0..15, raw 0..15, to SAM(timeout 5 s)  # Data index of the last 6 Bytes
          signal ADecu2_ORUData_XIX_ADecu2_01_XIX_E3V_K2CANFD: start 16, 48 bit, little-endian, data-type-policy=OVERRIDE, i-signal-type=PRIMITIVE, init-value=0, base-type=BT_ADecu2_ORUData, compu {phys=raw for raw 0..281474976710655}, range phys 0..281474976710655, raw 0..281474976710655, to SAM(timeout 5 s)  # "ORU information multiplexed - diagnostic address (2 bytes) - HW-part no (11 bytes) - HW version no. (3 bytes) - SW version no. (4 bytes) - IVD-P Value (64 bytes) need to be sent in combination with ORUDataIndex"
          mapping SG_ADecu2_01_XIX_E3V_K2CANFD: i-signal-group=SG_ADecu2_01_XIX_E3V_K2CANFD, transfer-property=TRIGGERED-WITHOUT-REPETITION
      frame Airbag_01_XIX_E3V_K2CANFD: id 0x40, to SAM, frame-length=8, can-addressing-mode=STANDARD, can-frame-rx-behavior=CAN-FD, can-frame-tx-behavior=CAN-FD
        pdu Airbag_01_XIX_E3V_K2CANFD_E2E: length=8, minimum-delay=0.01, transmission-mode-true-timing=event-controlled-timing={number-of-repetitions=0, repetition-period=0.0}, unused-bit-pattern=0  # Fuer die Botschaft ist das Cyclic-Timing 0.04 zu verwenden.
          signal Airbag_01_CRC_XIX_Airbag_01_XIX_E3V_K2CANFD: start 0, 8 bit, little-endian, data-type-policy=OVERRIDE, i-signal-type=PRIMITIVE, base-type=BT_Airbag_01_CRC, compu {phys=raw for raw 0..255}, range phys 0..255, raw 0..255, to SAM(timeout 0.5 s)  # Für MLB: "Berechnung siehe Lastenheft "Kommunikationsabsicherung für FlexRay und CAN"" Ab MQB und MLBevo: "Berechnung siehe Lastenheft "End-to-End Kommunikationsabsicherung"" Endwerte siehe Begleitdokument "S-PDU Kennungsfolgen"
          signal Airbag_01_BZ_XIX_Airbag_01_XIX_E3V_K2CANFD: start 8, 4 bit, little-endian, data-type-policy=OVERRIDE, i-signal-type=PRIMITIVE, base-type=BT_Airbag_01_BZ, compu {phys=raw for raw 0..15}, range phys 0..15, raw 0..15, to SAM(timeout 0.5 s)
          signal AB_RGS_Anst_XIX_Airbag_01_XIX_E3V_K2CANFD: start 12, 4 bit, little-endian, data-type-policy=OVERRIDE, i-signal-type=PRIMITIVE, init-value=8, base-type=BT_AB_RGS_Anst, compu {4=Cx4_aktiv_Niveau_1 (CM_AB_RGS_Anst_Cx4_aktiv_Niveau_1), 5=Cx5_aktiv_Niveau_2 (CM_AB_RGS_Anst_Cx5_aktiv_Niveau_2), 6=Cx6_aktiv_Niveau_3 (CM_AB_RGS_Anst_Cx6_aktiv_Niveau_3), 7=Cx7_aktiv_Niveau_4 (CM_AB_RGS_Anst_Cx7_aktiv_Niveau_4), 8=Cx8_deaktiviert (CM_AB_RGS_Anst_Cx8_deaktiviert)}, range raw 4..8  # PreCrash-Ansteuerung reversibler Gurtstraffer (Aktivierung und Kraftniveau) 10xx = deaktiviert
          signal AB_Front_Crash_XIX_Airbag_01_XIX_E3V_K2CANFD: start 16, 1 bit, little-endian, data-type-policy=OVERRIDE, i-signal-type=PRIMITIVE, init-value=0, base-type=BT_AB_Front_Crash, compu {0=Cx0_kein_Front_Crash (CM_AB_Front_Crash_Cx0_kein_Front_Crash), 1=Cx1_Front_Crash (CM_AB_Front_Crash_Cx1_Front_Crash)}, range raw 0..1, to SAM(timeout 0.5 s)  # Bit wird bei Überschreitung der Gurtstraffer-, US- und RdW-Schwelle gesetzt
          signal AB_Heck_Crash_XIX_Airbag_01_XIX_E3V_K2CANFD: start 17, 1 bit, little-endian, data-type-policy=OVERRIDE, i-signal-type=PRIMITIVE, init-value=0, base-type=BT_AB_Heck_Crash, compu {0=Cx0_kein_Heck_Crash (CM_AB_Heck_Crash_Cx0_kein_Heck_Crash), 1=Cx1_Heck_Crash (CM_AB_Heck_Crash_Cx1_Heck_Crash)}, range raw 0..1, to SAM(timeout 0.5 s)  # Wird für alle neu anlaufenden Projekte umgesetzt: AB8.4, Audi8/VW8
          signal AB_SF_Crash_XIX_Airbag_01_XIX_E3V_K2CANFD: start 18, 1 bit, little-endian, data-type-policy=OVERRIDE, i-signal-type=PRIMITIVE, init-value=0, base-type=BT_AB_SF_Crash, compu {0=Cx0_kein_Seiten_Crash_Fahrer (CM_AB_SF_Crash_Cx0_kein_Seiten_Crash_Fahrer), 1=Cx1_Seiten_Crash_Fahrer (CM_AB_SF_Crash_Cx1_Seiten_Crash_Fahrer)}, range raw 0..1, to SAM(timeout 0.5 s)  # Z.Zt. nur in Verbindung mit Crash-Intensität >= 100b (Kraftstoffpumpenabschaltung) verwendet.
          signal AB_SB_Crash_XIX_Airbag_01_XIX_E3V_K2CANFD: start 19, 1 bit, little-endian, data-type-policy=OVERRIDE, i-signal-type=PRIMITIVE, init-value=0, base-type=BT_AB_SB_Crash, compu {0=Cx0_kein_Seiten_Crash_Beifahrer (CM_AB_SB_Crash_Cx0_kein_Seiten_Crash_Beifahrer), 1=Cx1_Seiten_Crash_Beifahrer (CM_AB_SB_Crash_Cx1_Seiten_Crash_Beifahrer)}, range raw 0..1, to SAM(timeout 0.5 s)  # Z.Zt. nur in Verbindung mit Crash-Intensität >= 100b (Kraftstoffpumpenabschaltung) verwendet.
          signal AB_Rollover_Crash_XIX_Airbag_01_XIX_E3V_K2CANFD: start 20, 1 bit, little-endian, data-type-policy=OVERRIDE, i-signal-type=PRIMITIVE, init-value=0, base-type=BT_AB_Rollover_Crash, compu {0=Cx0_kein_Rollover (CM_AB_Rollover_Crash_Cx0_kein_Rollover), 1=Cx1_Rollover (CM_AB_Rollover_Crash_Cx1_Rollover)}, range raw 0..1, to SAM(timeout 0.5 s)  # Wird im B6/B7 Cabrio und New Beetle Cabrio bedient.
          signal AB_Crash_Int_XIX_Airbag_01_XIX_E3V_K2CANFD: start 21, 3 bit, little-endian, data-type-policy=OVERRIDE, i-signal-type=PRIMITIVE, init-value=0, base-type=BT_AB_Crash_Int, compu {0=Cx0_kein_Crash (CM_AB_Crash_Int_Cx0_kein_Crash), 1=Cx1_Crash_Intensitaet_1 (CM_AB_Crash_Int_Cx1_Crash_Intensitaet_1), 2=Cx2_Crash_Intensitaet_2_nur_Stellgliedtest_MLB_B8 (CM_AB_Crash_Int_Cx2_Crash_Intensitaet_2_nur_Stellgliedtest_MLB_B8) (Crash_Intensitaet_2_(nur_Stellgliedtest_MLB_B8)), 3=Cx3_Crash_Intensitaet_2_nur_D4_C7_Colorado_NF_PAG_Crash_im_MLB_B8 (CM_AB_Crash_Int_Cx3_Crash_Intensitaet_2_nur_D4_C7_Colorado_NF_PAG_Crash_im_MLB_B8) (Crash_Intensitaet_2_(nur_D4_C7_Colorado_NF_PAG__Crash_im_MLB_B8)), 4=Cx4_Crash_Intensitaet_3_alt_VW_AUDI_Stellgliedtest_MLB_B8 (CM_AB_Crash_Int_Cx4_Crash_Intensitaet_3_alt_VW_AUDI_Stellgliedtest_MLB_B8) (Crash_Intensitaet_3_(alt_VW/AUDI__Stellgliedtest_MLB_B8)), 5=Cx5_Crash_Intensitaet_3_alt_PAG (CM_AB_Crash_Int_Cx5_Crash_Intensitaet_3_alt_PAG) (Crash_Intensitaet_3_(alt_PAG)), 7=Cx7_Crash_Intensitaet_3 (CM_AB_Crash_Int_Cx7_Crash_Intensitaet_3)}, range raw 0..7, to SAM(timeout 0.5 s)  # Crash_Intensität_1 = fahrzeugabhängige Reaktionen im Crash Crash_Intensität_2 = fahrzeugabhängige Reaktionen im Crash Crash_Intensität_3 = fahrzeugabhängige Reaktionen im Crash Die jeweiligen fahrzeugabhängigen Reaktionen im Crash sind in einem separaten Doors Modul im Airbag-SG beschrieben. Die Information bleibt bei jeder Schwellwert-überschreitung für ~10 s bestehen (Achtung: Energiereserve bei abgetrennter Batterie reicht worstcase nur für 150 ms)
          signal AB_Lampe_XIX_Airbag_01_XIX_E3V_K2CANFD: start 24, 1 bit, little-endian, data-type-policy=OVERRIDE, i-signal-type=PRIMITIVE, init-value=1, base-type=BT_AB_Lampe, compu {0=Cx0_Aus (CM_AB_Lampe_Cx0_Aus), 1=Cx1_Ein (CM_AB_Lampe_Cx1_Ein)}, range raw 0..1  # Sicherheitswarnlampe im Kombi wird vom Airbag-SG angesteuert; Zustand der Lampe wird auf dem CAN-Bus ausgegeben (auch Blinkinformation).
          signal AB_Deaktiviert_XIX_Airbag_01_XIX_E3V_K2CANFD: start 25, 1 bit, little-endian, data-type-policy=OVERRIDE, i-signal-type=PRIMITIVE, init-value=0, base-type=BT_AB_Deaktiviert, compu {0=Cx0_aktiv (CM_AB_Deaktiviert_Cx0_aktiv), 1=Cx1_deaktiviert (CM_AB_Deaktiviert_Cx1_deaktiviert)}, range raw 0..1  # Airbag oder Gurtstraffer wurden per Anpassung deaktiviert: Aktualisierung erst nach Selbsttest
          signal AB_VB_deaktiviert_XIX_Airbag_01_XIX_E3V_K2CANFD: start 26, 1 bit, little-endian, data-type-policy=OVERRIDE, i-signal-type=PRIMITIVE, init-value=1, base-type=BT_AB_VB_deaktiviert, compu {0=Cx0_Beifahrerairbag_aktiv (CM_AB_VB_deaktiviert_Cx0_Beifahrerairbag_aktiv), 1=Cx1_Beifahrerairbag_deaktiviert (CM_AB_VB_deaktiviert_Cx1_Beifahrerairbag_deaktiviert)}, range raw 0..1  # Als Option vorgehalten, Beifahrerairbag wurden per Schlüsselschalter oder Insassenerkennung deaktiviert
          signal AB_Systemfehler_XIX_Airbag_01_XIX_E3V_K2CANFD: start 27, 1 bit, little-endian, data-type-policy=OVERRIDE, i-signal-type=PRIMITIVE, init-value=0, base-type=BT_AB_Systemfehler, compu {0=Cx0_kein_Fehler (CM_AB_Systemfehler_Cx0_kein_Fehler), 1=Cx1_Airbag_Systemfehler (CM_AB_Systemfehler_Cx1_Airbag_Systemfehler)}, range raw 0..1  # Systemfehler Ggf. wird Warnlampe dauernd eingeschaltet.
          signal AB_Diagnose_XIX_Airbag_01_XIX_E3V_K2CANFD: start 28, 1 bit, little-endian, data-type-policy=OVERRIDE, i-signal-type=PRIMITIVE, init-value=0, base-type=BT_AB_Diagnose, compu {0=Cx0_nicht_in_Diagnose (CM_AB_Diagnose_Cx0_nicht_in_Diagnose), 1=Cx1_in_Diagnose (CM_AB_Diagnose_Cx1_in_Diagnose)}, range raw 0..1  # Airbag in Diagnose
          signal AB_Stellgliedtest_XIX_Airbag_01_XIX_E3V_K2CANFD: start 29, 1 bit, little-endian, data-type-policy=OVERRIDE, i-signal-type=PRIMITIVE, init-value=0, base-type=BT_AB_Stellgliedtest, compu {0=Cx0_nicht_im_Stellgliedtest (CM_AB_Stellgliedtest_Cx0_nicht_im_Stellgliedtest), 1=Cx1_Airbag_im_Stellgliedtest (CM_AB_Stellgliedtest_Cx1_Airbag_im_Stellgliedtest)}, range raw 0..1  # Information, ob Airbag im Stellgliedtest ist, um eine Notrufauflösung beim Stellgliedtest zu verhindern
          signal AB_Erh_Auf_VB_XIX_Airbag_01_XIX_E3V_K2CANFD: start 30, 2 bit, little-endian, data-type-policy=OVERRIDE, i-signal-type=PRIMITIVE, init-value=0, base-type=BT_AB_Erh_Auf_VB, compu {0=Cx0_keine_Anzeige (CM_AB_Erh_Auf_VB_Cx0_keine_Anzeige), 1=Cx1_Beifahrerairbag_deaktiviert (CM_AB_Erh_Auf_VB_Cx1_Beifahrerairbag_deaktiviert), 2=Cx2_Beifahrerairbag_aktiviert (CM_AB_Erh_Auf_VB_Cx2_Beifahrerairbag_aktiviert), 3=Cx3_nicht_definiert (CM_AB_Erh_Auf_VB_Cx3_nicht_definiert)}, range raw 0..3  # Der Fahrer soll bei einem Statuswechsel des Beifahrerairbags (ausgelöst durch die Beifahrerinsassenerkennung oder den Schlüsselschloßschalter) aufmerksam gemacht werden durch eine Anzeige im Kombi. Nur Audi: gültig für: AB2 (4-Türer AU352), B7, C6, D3
          signal AB_Gurtwarn_VF_XIX_Airbag_01_XIX_E3V_K2CANFD: start 32, 1 bit, little-endian, data-type-policy=OVERRIDE, i-signal-type=PRIMITIVE, init-value=0, base-type=BT_AB_Gurtwarn_VF, compu {0=Cx0_keine_Warnung (CM_AB_Gurtwarn_VF_Cx0_keine_Warnung), 1=Cx1_Gurtwarnung_ausloesen (CM_AB_Gurtwarn_VF_Cx1_Gurtwarnung_ausloesen)}, range raw 0..1  # Fahrer hat Gurt nicht gesteckt, Anzeige im Kombi
          signal AB_Gurtwarn_VB_XIX_Airbag_01_XIX_E3V_K2CANFD: start 33, 1 bit, little-endian, data-type-policy=OVERRIDE, i-signal-type=PRIMITIVE, init-value=0, base-type=BT_AB_Gurtwarn_VB, compu {0=Cx0_keine_Warnung (CM_AB_Gurtwarn_VB_Cx0_keine_Warnung), 1=Cx1_Gurtwarnung_ausloesen (CM_AB_Gurtwarn_VB_Cx1_Gurtwarnung_ausloesen)}, range raw 0..1  # Beifahrer hat Gurt nicht gesteckt, Anzeige im Kombi
          signal AB_Anzeige_Fussg_XIX_Airbag_01_XIX_E3V_K2CANFD: start 34, 2 bit, little-endian, data-type-policy=OVERRIDE, i-signal-type=PRIMITIVE, init-value=0, base-type=BT_AB_Anzeige_Fussg, compu {0=Cx0_keine_FSG_Aktion_ausgeloest (CM_AB_Anzeige_Fussg_Cx0_keine_FSG_Aktion_ausgeloest), 1=Cx1_Motorhaube_offen (CM_AB_Anzeige_Fussg_Cx1_Motorhaube_offen), 2=Cx2_Systemfehler (CM_AB_Anzeige_Fussg_Cx2_Systemfehler)}, range raw 0..2  # Anzeige für ausgelöste Fussgängerschutz-Aktuatorik
          signal AB_Texte_AKS_XIX_Airbag_01_XIX_E3V_K2CANFD: start 36, 2 bit, little-endian, data-type-policy=OVERRIDE, i-signal-type=PRIMITIVE, init-value=0, base-type=BT_AB_Texte_AKS, compu {0=Cx0_keine_AKS_Ausloesung (CM_AB_Texte_AKS_Cx0_keine_AKS_Ausloesung), 1=Cx1_AKS_ausgeloest (CM_AB_Texte_AKS_Cx1_AKS_ausgeloest), 2=Cx2_AKS_Systemfehler (CM_AB_Texte_AKS_Cx2_AKS_Systemfehler)}, range raw 0..2  # Textanzeige für pyrotechnische Auslösung der aktiven Kopfstütze (AKS)
          signal AB_PAO_Leuchte_Anf_XIX_Airbag_01_XIX_E3V_K2CANFD: start 38, 1 bit, little-endian, data-type-policy=OVERRIDE, i-signal-type=PRIMITIVE, init-value=1, base-type=BT_AB_PAO_Leuchte_Anf, compu {0=Cx0_Leuchte_ausschalten (CM_AB_PAO_Leuchte_Anf_Cx0_Leuchte_ausschalten), 1=Cx1_Leuchte_einschalten (CM_AB_PAO_Leuchte_Anf_Cx1_Leuchte_einschalten)}, range raw 0..1  # Anforderung an die Passenger-Airbag-Off Leuchte in der Dachkonsole (ein / aus), Einsatz nur bei PAG
          signal AB_MKB_gueltig_XIX_Airbag_01_XIX_E3V_K2CANFD: start 39, 1 bit, little-endian, data-type-policy=OVERRIDE, i-signal-type=PRIMITIVE, init-value=0, base-type=BT_AB_MKB_gueltig, compu {0=Cx0_Multikollisionsbremsung_nicht_freigeschaltet (CM_AB_MKB_gueltig_Cx0_Multikollisionsbremsung_nicht_freigeschaltet), 1=Cx1_Multikollisionsbremsung_freigeschaltet (CM_AB_MKB_gueltig_Cx1_Multikollisionsbremsung_freigeschaltet)}, range raw 0..1  # Multi-Kollisions-Bremsung im Airbag freigeschaltet
          signal AB_MKB_Anforderung_XIX_Airbag_01_XIX_E3V_K2CANFD: start 40, 1 bit, little-endian, data-type-policy=OVERRIDE, i-signal-type=PRIMITIVE, init-value=0, base-type=BT_AB_MKB_Anforderung, compu {0=Cx0_Multikollisionsbremsung_nicht_angefordert (CM_AB_MKB_Anforderung_Cx0_Multikollisionsbremsung_nicht_angefordert), 1=Cx1_Multikollisionsbremsung_angefordert (CM_AB_MKB_Anforderung_Cx1_Multikollisionsbremsung_angefordert)}, range raw 0..1  # Anforderung Multi-Kollisions-Bremsung
          signal AB_Versorgungsspannung_XIX_Airbag_01_XIX_E3V_K2CANFD: start 41, 1 bit, little-endian, data-type-policy=OVERRIDE, i-signal-type=PRIMITIVE, init-value=0, base-type=BT_AB_Versorgungsspannung, compu {0=Cx0_plausibel (CM_AB_Versorgungsspannung_Cx0_plausibel), 1=Cx1_unplausibel (CM_AB_Versorgungsspannung_Cx1_unplausibel)}, range raw 0..1  # Übertragung der Plausibilitätsinformation Kl.15-Last vs. Kl.15-CAN. Bedienung im Fall Kl.15-Last "EIN" und Kl.15-CAN "AUS" mit Ausgabe Warnung/Akustik im Kombi.
          signal AB_Deaktivierung_HV_XIX_Airbag_01_XIX_E3V_K2CANFD: start 42, 3 bit, little-endian, data-type-policy=OVERRIDE, i-signal-type=PRIMITIVE, init-value=0, base-type=BT_AB_Deaktivierung_HV, invalid-value=Invalid_AB_Deaktivierung_HV_XIX_Airbag_01_XIX_E3V_K2CANFD:7, compu {0=Cx0_keine_Deaktivierung (CM_AB_Deaktivierung_HV_Cx0_keine_Deaktivierung), 1=Cx1_Deaktivierung_1 (CM_AB_Deaktivierung_HV_Cx1_Deaktivierung_1), 2=Cx2_Deaktivierung_2 (CM_AB_Deaktivierung_HV_Cx2_Deaktivierung_2), 3=Cx3_Deaktivierung_3 (CM_AB_Deaktivierung_HV_Cx3_Deaktivierung_3), 4=Cx4_Deaktivierung_4 (CM_AB_Deaktivierung_HV_Cx4_Deaktivierung_4), 5=Cx5_Deaktivierung_5 (CM_AB_Deaktivierung_HV_Cx5_Deaktivierung_5), 6=Cx6_Deaktivierung_6 (CM_AB_Deaktivierung_HV_Cx6_Deaktivierung_6), 7=Cx7_Fehler (CM_AB_Deaktivierung_HV_Cx7_Fehler)}, range raw 0..7, to SAM(timeout 0.5 s)  # Deaktivierung des HV-Systems und der HV-Teilnehmer im Crash (u.a. Hybrid- und Elektrofahrzeuge)
          signal AB_EDR_Trigger_XIX_Airbag_01_XIX_E3V_K2CANFD: start 45, 2 bit, little-endian, data-type-policy=OVERRIDE, i-signal-type=PRIMITIVE, init-value=0, base-type=BT_AB_EDR_Trigger, compu {0=Cx0_No_Event (CM_AB_EDR_Trigger_Cx0_No_Event), 1=Cx1_Start_Event (CM_AB_EDR_Trigger_Cx1_Start_Event), 2=Cx2_NonDeployment_Event (CM_AB_EDR_Trigger_Cx2_NonDeployment_Event), 3=Cx3_Deployment_Event (CM_AB_EDR_Trigger_Cx3_Deployment_Event)}, range raw 0..3  # Triggerbedingung zur dezentralen Aufzeichnung unfallrelevanter Daten im Event Data Recorder
          signal AB_Belegung_VF_XIX_Airbag_01_XIX_E3V_K2CANFD: start 47, 2 bit, little-endian, data-type-policy=OVERRIDE, i-signal-type=PRIMITIVE, init-value=0, base-type=BT_AB_Belegung_VF, invalid-value=Invalid_AB_Belegung_VF_XIX_Airbag_01_XIX_E3V_K2CANFD:1, compu {0=Cx0_nicht_verfuegbar (CM_AB_Belegung_VF_Cx0_nicht_verfuegbar), 1=Cx1_Fehler (CM_AB_Belegung_VF_Cx1_Fehler), 2=Cx2_nicht_belegt (CM_AB_Belegung_VF_Cx2_nicht_belegt), 3=Cx3_belegt (CM_AB_Belegung_VF_Cx3_belegt)}, range raw 0..3  # Belegungserkennung vorne Fahrer.
          signal AB_Gurtschloss_FA_ext_XIX_Airbag_01_XIX_E3V_K2CANFD: start 49, 3 bit, little-endian, data-type-policy=OVERRIDE, i-signal-type=PRIMITIVE, init-value=6, base-type=BT_AB_Gurtschloss_FA_ext, invalid-value=Invalid_AB_Gurtschloss_FA_ext_XIX_Airbag_01_XIX_E3V_K2CANFD:7, compu {0=Cx0_nicht_verbaut (CM_AB_Gurtschloss_FA_ext_Cx0_nicht_verbaut), 1=Cx1_reserviert (CM_AB_Gurtschloss_FA_ext_Cx1_reserviert), 2=Cx2_nicht_gesteckt (CM_AB_Gurtschloss_FA_ext_Cx2_nicht_gesteckt), 3=Cx3_gesteckt (CM_AB_Gurtschloss_FA_ext_Cx3_gesteckt), 4=Cx4_dauerhaft_nicht_gesteckt (CM_AB_Gurtschloss_FA_ext_Cx4_dauerhaft_nicht_gesteckt), 5=Cx5_dauerhaft_gesteckt (CM_AB_Gurtschloss_FA_ext_Cx5_dauerhaft_gesteckt), 6=Cx6_Init (CM_AB_Gurtschloss_FA_ext_Cx6_Init), 7=Cx7_Fehler (CM_AB_Gurtschloss_FA_ext_Cx7_Fehler)}, range raw 0..7  # Das Ergebnis der Basisfunktion "Plausibilisierung Gurtschloss" des Verlassenskonzepts wird im Signal dargestellt.
          signal AB_Gurtschloss_FA_ext_aktiv_XIX_Airbag_01_XIX_E3V_K2CANFD: start 52, 1 bit, little-endian, data-type-policy=OVERRIDE, i-signal-type=PRIMITIVE, init-value=0, base-type=BT_AB_Gurtschloss_FA_ext_aktiv, compu {0=Cx0_inaktiv (CM_AB_Gurtschloss_FA_ext_aktiv_Cx0_inaktiv), 1=Cx1_aktiv (CM_AB_Gurtschloss_FA_ext_aktiv_Cx1_aktiv)}, range raw 0..1  # Über dieses Signal wird signalisiert ob die Erweiterte Gurtdiagnose (Ergebnis wird im Signal AB_Gurtschloss_FA_ext dargestellt) aktiviert oder deaktiviert ist.
          signal AB_eCS_Error_XIX_Airbag_01_XIX_E3V_K2CANFD: start 53, 1 bit, little-endian, data-type-policy=OVERRIDE, i-signal-type=PRIMITIVE, init-value=0, base-type=BT_AB_eCS_Error, compu {0=Cx0_keine_Anzeige (CM_AB_eCS_Error_Cx0_keine_Anzeige), 1=Cx1_Anzeige_anfordern (CM_AB_eCS_Error_Cx1_Anzeige_anfordern)}, range raw 0..1  # Signal zur Anforderung der Anzeige von Störungen im System der elektrischen Gurtverriegelung
          signal AB_PSS_SollZustand_XIX_Airbag_01_XIX_E3V_K2CANFD: start 54, 1 bit, little-endian, data-type-policy=OVERRIDE, i-signal-type=PRIMITIVE, init-value=0, base-type=BT_AB_PSS_SollZustand, compu {0=Cx0_disabled (CM_AB_PSS_SollZustand_Cx0_disabled), 1=Cx1_enabled (CM_AB_PSS_SollZustand_Cx1_enabled)}, range raw 0..1  # Erwartete Auslösefähigkeit
          signal ISignalVoid_Airbag_01_XIX_E3V_K2CANFD_0: start 55, 1 bit, little-endian, system signal SignalVoid_Airbag_01_0, data-type-policy=OVERRIDE, i-signal-type=PRIMITIVE, base-type=BT_SignalVoid
          signal ASM_Masterzeit_02_XIX_Airbag_01_XIX_E3V_K2CANFD: start 56, 8 bit, little-endian, data-type-policy=OVERRIDE, i-signal-type=PRIMITIVE, init-value=255, base-type=BT_ASM_Masterzeit_02, compu {phys=raw*0.04 for raw 0..254, 255=Cxff_Init (CM_ASM_Masterzeit_02_Cxff_Init); unit Unit_Secon}, range phys 0..10.16 Unit_Secon, raw 0..255, unit=Unit_Secon  # Masterzeit für alle ASM Sender
          mapping SG_Airbag_01_XIX_E3V_K2CANFD: i-signal-group=SG_Airbag_01_XIX_E3V_K2CANFD, transfer-property=TRIGGERED-WITHOUT-REPETITION
      frame Airbag_02_XIX_E3V_K2CANFD: id 0x520, to SAM, frame-length=8, can-addressing-mode=STANDARD, can-frame-rx-behavior=CAN-FD, can-frame-tx-behavior=CAN-FD
        pdu Airbag_02_XIX_E3V_K2CANFD_E2E: length=8, minimum-delay=0.02, transmission-mode-true-timing=event-controlled-timing={number-of-repetitions=0, repetition-period=0.0}, unused-bit-pattern=0  # Fuer die Botschaft ist das Cyclic-Timing 0.2 zu verwenden.
          signal Airbag_02_CRC_XIX_Airbag_02_XIX_E3V_K2CANFD: start 0, 8 bit, little-endian, data-type-policy=OVERRIDE, i-signal-type=PRIMITIVE, base-type=BT_Airbag_02_CRC, compu {phys=raw for raw 0..255}, range phys 0..255, raw 0..255, to SAM(timeout 2 s)  # Für MLB: "Berechnung siehe Lastenheft "Kommunikationsabsicherung für FlexRay und CAN"" Ab MQB und MLBevo: "Berechnung siehe Lastenheft "End-to-End Kommunikationsabsicherung"" Endwerte siehe Begleitdokument "S-PDU Kennungsfolgen"
          signal Airbag_02_BZ_XIX_Airbag_02_XIX_E3V_K2CANFD: start 8, 4 bit, little-endian, data-type-policy=OVERRIDE, i-signal-type=PRIMITIVE, base-type=BT_Airbag_02_BZ, compu {phys=raw for raw 0..15}, range phys 0..15, raw 0..15, to SAM(timeout 2 s)
          signal LoGeWa_Event_Kombiwarnung_XIX_Airbag_02_XIX_E3V_K2CANFD: start 12, 4 bit, little-endian, data-type-policy=OVERRIDE, i-signal-type=PRIMITIVE, init-value=0, base-type=BT_LoGeWa_Event_Kombiwarnung, compu {0=Cx0_Init (CM_LoGeWa_Event_Kombiwarnung_Cx0_Init), 1=Cx1_Unfall (CM_LoGeWa_Event_Kombiwarnung_Cx1_Unfall), 2=Cx2_Traktionsverlust (CM_LoGeWa_Event_Kombiwarnung_Cx2_Traktionsverlust), 3=Cx3_Panne (CM_LoGeWa_Event_Kombiwarnung_Cx3_Panne), 4=Cx4_Sichtbehinderung (CM_LoGeWa_Event_Kombiwarnung_Cx4_Sichtbehinderung), 5=Cx5_Aquaplaning (CM_LoGeWa_Event_Kombiwarnung_Cx5_Aquaplaning)}, range raw 0..5  # Event für Kombiwarnung
          signal AB_Anforderung_eCall_XIX_Airbag_02_XIX_E3V_K2CANFD: start 16, 1 bit, little-endian, data-type-policy=OVERRIDE, i-signal-type=PRIMITIVE, init-value=0, base-type=BT_AB_Anforderung_eCall, compu {0=Cx0_keine_Anforderung (CM_AB_Anforderung_eCall_Cx0_keine_Anforderung), 1=Cx1_Anforderung (CM_AB_Anforderung_eCall_Cx1_Anforderung)}, range raw 0..1  # Trigger für Car2X Steuergerät das ein eCall Ereignis erkannt wurde.
          signal AB_Anprall_Seite_Beifahrer_XIX_Airbag_02_XIX_E3V_K2CANFD: start 17, 1 bit, little-endian, data-type-policy=OVERRIDE, i-signal-type=PRIMITIVE, init-value=0, base-type=BT_AB_Anprall_Seite_Beifahrer, compu {0=Cx0_kein_Anprall (CM_AB_Anprall_Seite_Beifahrer_Cx0_kein_Anprall), 1=Cx1_Anprall_erkannt (CM_AB_Anprall_Seite_Beifahrer_Cx1_Anprall_erkannt)}, range raw 0..1  # Uebermittlung der Lage einer Kollision, Anprallzone Beifahrerseite Seite
          signal ISignalVoid_Airbag_02_XIX_E3V_K2CANFD_0: start 18, 1 bit, little-endian, system signal SignalVoid_Airbag_02_0, data-type-policy=OVERRIDE, i-signal-type=PRIMITIVE, base-type=BT_SignalVoid
          signal AB_Anprall_FGS_XIX_Airbag_02_XIX_E3V_K2CANFD: start 19, 1 bit, little-endian, data-type-policy=OVERRIDE, i-signal-type=PRIMITIVE, init-value=0, base-type=BT_AB_Anprall_FGS, compu {0=Cx0_kein_Anprall (CM_AB_Anprall_FGS_Cx0_kein_Anprall), 1=Cx1_Anprall_erkannt (CM_AB_Anprall_FGS_Cx1_Anprall_erkannt)}, range raw 0..1  # Uebermittlung der Lage einer Kollision, Fussgaengerschutz-Aktorik
          signal AB_Anprall_Front_Beifahrer_XIX_Airbag_02_XIX_E3V_K2CANFD: start 20, 1 bit, little-endian, data-type-policy=OVERRIDE, i-signal-type=PRIMITIVE, init-value=0, base-type=BT_AB_Anprall_Front_Beifahrer, compu {0=Cx0_kein_Anprall (CM_AB_Anprall_Front_Beifahrer_Cx0_kein_Anprall), 1=Cx1_Anprall_erkannt (CM_AB_Anprall_Front_Beifahrer_Cx1_Anprall_erkannt)}, range raw 0..1  # Uebermittlung der Lage einer Kollision, Anprallzone Front Beifahrerseite
          signal AB_Anprall_Front_Fahrer_XIX_Airbag_02_XIX_E3V_K2CANFD: start 21, 1 bit, little-endian, data-type-policy=OVERRIDE, i-signal-type=PRIMITIVE, init-value=0, base-type=BT_AB_Anprall_Front_Fahrer, compu {0=Cx0_kein_Anprall (CM_AB_Anprall_Front_Fahrer_Cx0_kein_Anprall), 1=Cx1_Anprall_erkannt (CM_AB_Anprall_Front_Fahrer_Cx1_Anprall_erkannt)}, range raw 0..1  # Uebermittlung der Lage einer Kollision, Anprallzone Front Fahrerseite
          signal ISignalVoid_Airbag_02_XIX_E3V_K2CANFD_1: start 22, 2 bit, little-endian, system signal SignalVoid_Airbag_02_1, data-type-policy=OVERRIDE, i-signal-type=PRIMITIVE, base-type=BT_SignalVoid
          signal AB_Wickelklappung_Reihe2_MI_XIX_Airbag_02_XIX_E3V_K2CANFD: start 24, 2 bit, little-endian, data-type-policy=OVERRIDE, i-signal-type=PRIMITIVE, init-value=1, base-type=BT_AB_Wickelklappung_Reihe2_MI, compu {0=Cx0_nicht_verbaut (CM_AB_Wickelklappung_Reihe2_MI_Cx0_nicht_verbaut), 1=Cx1_nicht_verfuegbar_Fehler_oder_Init (CM_AB_Wickelklappung_Reihe2_MI_Cx1_nicht_verfuegbar_Fehler_oder_Init) (nicht_verfuegbar__Fehler_oder_Init), 2=Cx2_nicht_verriegelt (CM_AB_Wickelklappung_Reihe2_MI_Cx2_nicht_verriegelt), 3=Cx3_verriegelt (CM_AB_Wickelklappung_Reihe2_MI_Cx3_verriegelt)}, range raw 0..3  # Status Wickelklappung 2. Reihe Mitte, Mehrausstattung
          signal AB_Belegung_VB_XIX_Airbag_02_XIX_E3V_K2CANFD: start 26, 2 bit, little-endian, data-type-policy=OVERRIDE, i-signal-type=PRIMITIVE, init-value=0, base-type=BT_AB_Belegung_VB, invalid-value=Invalid_AB_Belegung_VB_XIX_Airbag_02_XIX_E3V_K2CANFD:1, compu {0=Cx0_nicht_verfuegbar (CM_AB_Belegung_VB_Cx0_nicht_verfuegbar), 1=Cx1_Fehler (CM_AB_Belegung_VB_Cx1_Fehler), 2=Cx2_nicht_belegt (CM_AB_Belegung_VB_Cx2_nicht_belegt), 3=Cx3_belegt (CM_AB_Belegung_VB_Cx3_belegt)}, range raw 0..3, to SAM(timeout 2 s)  # Belegungserkennung vorne Beifahrer. Wird in US-Steuergeräten über Bladder-Matte bedient, optional bei RdW, falls SBE_EuroNCAP entschieden wird.
          signal AB_Abschaltanf_SIH_BF_XIX_Airbag_02_XIX_E3V_K2CANFD: start 28, 1 bit, little-endian, data-type-policy=OVERRIDE, i-signal-type=PRIMITIVE, init-value=0, base-type=BT_AB_Abschaltanf_SIH_BF, compu {0=Cx0_Normalbetrieb (CM_AB_Abschaltanf_SIH_BF_Cx0_Normalbetrieb), 1=Cx1_Abschaltung_angefordert (CM_AB_Abschaltanf_SIH_BF_Cx1_Abschaltung_angefordert)}, range raw 0..1  # Die Insassenerkennung auf der Beifahrerseite fordert bei Übertemperatur eine Abschaltung der Sitzheizung an. Die Übertemperatur kann bei niederohmigen Nebenschlüssen der Sitzheizungsmatte als Folge von zu hohem resultierenden Strom auftreten.
          signal AB_Anprall_Seite_Fahrer_XIX_Airbag_02_XIX_E3V_K2CANFD: start 29, 1 bit, little-endian, data-type-policy=OVERRIDE, i-signal-type=PRIMITIVE, init-value=0, base-type=BT_AB_Anprall_Seite_Fahrer, compu {0=Cx0_kein_Anprall (CM_AB_Anprall_Seite_Fahrer_Cx0_kein_Anprall), 1=Cx1_Anprall_erkannt (CM_AB_Anprall_Seite_Fahrer_Cx1_Anprall_erkannt)}, range raw 0..1  # Uebermittlung der Lage einer Kollision, Anprallzone Fahrerseite Seite
          signal SC_PAO_Schriftzug_Anf_XIX_Airbag_02_XIX_E3V_K2CANFD: start 30, 2 bit, little-endian, data-type-policy=OVERRIDE, i-signal-type=PRIMITIVE, init-value=0, base-type=BT_SC_PAO_Schriftzug_Anf, compu {0=Cx0_LED_aus (CM_SC_PAO_Schriftzug_Anf_Cx0_LED_aus) (LED aus), 1=Cx1_LED_an (CM_SC_PAO_Schriftzug_Anf_Cx1_LED_an) (LED an), 2=Cx2_LED_blinken (CM_SC_PAO_Schriftzug_Anf_Cx2_LED_blinken) (LED blinken), 3=Cx3_reserviert (CM_SC_PAO_Schriftzug_Anf_Cx3_reserviert)}, range raw 0..3  # Sollwert für LED "PASSENGER AIRBAG" in Anzeige Passenger Airbag On/Off
          signal SC_PAO_ON_Anf_XIX_Airbag_02_XIX_E3V_K2CANFD: start 32, 2 bit, little-endian, data-type-policy=OVERRIDE, i-signal-type=PRIMITIVE, init-value=0, base-type=BT_SC_PAO_ON_Anf, compu {0=Cx0_LED_aus (CM_SC_PAO_ON_Anf_Cx0_LED_aus) (LED aus), 1=Cx1_LED_an (CM_SC_PAO_ON_Anf_Cx1_LED_an) (LED an), 2=Cx2_LED_blinken (CM_SC_PAO_ON_Anf_Cx2_LED_blinken) (LED blinken), 3=Cx3_reserviert (CM_SC_PAO_ON_Anf_Cx3_reserviert)}, range raw 0..3, to SAM(timeout 2 s)  # Sollwert für LED "ON" in Anzeige Passenger Airbag On/Off
          signal SC_PAO_OFF_Anf_XIX_Airbag_02_XIX_E3V_K2CANFD: start 34, 2 bit, little-endian, data-type-policy=OVERRIDE, i-signal-type=PRIMITIVE, init-value=0, base-type=BT_SC_PAO_OFF_Anf, compu {0=Cx0_LED_aus (CM_SC_PAO_OFF_Anf_Cx0_LED_aus) (LED aus), 1=Cx1_LED_an (CM_SC_PAO_OFF_Anf_Cx1_LED_an) (LED an), 2=Cx2_LED_blinken (CM_SC_PAO_OFF_Anf_Cx2_LED_blinken) (LED blinken), 3=Cx3_reserviert (CM_SC_PAO_OFF_Anf_Cx3_reserviert)}, range raw 0..3, to SAM(timeout 2 s)  # Sollwert für LED "OFF" in Anzeige Passenger Airbag On/Off
          signal AB_Crashschwere_XIX_Airbag_02_XIX_E3V_K2CANFD: start 36, 3 bit, little-endian, data-type-policy=OVERRIDE, i-signal-type=PRIMITIVE, init-value=0, base-type=BT_AB_Crashschwere, invalid-value=Invalid_AB_Crashschwere_XIX_Airbag_02_XIX_E3V_K2CANFD:7, compu {0=Cx0_kein_Ereignis (CM_AB_Crashschwere_Cx0_kein_Ereignis), 1=Cx1_Crashschwere_1 (CM_AB_Crashschwere_Cx1_Crashschwere_1), 2=Cx2_Crashschwere_2 (CM_AB_Crashschwere_Cx2_Crashschwere_2), 3=Cx3_Crashschwere_3 (CM_AB_Crashschwere_Cx3_Crashschwere_3), 4=Cx4_Crashschwere_4 (CM_AB_Crashschwere_Cx4_Crashschwere_4), 5=Cx5_Crashschwere_5 (CM_AB_Crashschwere_Cx5_Crashschwere_5), 6=Cx6_Crashschwere_2_bis_5 (CM_AB_Crashschwere_Cx6_Crashschwere_2_bis_5), 7=Cx7_Fehler (CM_AB_Crashschwere_Cx7_Fehler)}, range raw 0..7  # Übermittlung der Crashschwere an das Gateway (OBDC)
          signal AB_Anforderung_USM_XIX_Airbag_02_XIX_E3V_K2CANFD: start 39, 1 bit, little-endian, data-type-policy=OVERRIDE, i-signal-type=PRIMITIVE, init-value=0, base-type=BT_AB_Anforderung_USM, compu {0=Cx0_keine_Anforderung (CM_AB_Anforderung_USM_Cx0_keine_Anforderung), 1=Cx1_Anforderung (CM_AB_Anforderung_USM_Cx1_Anforderung)}, range raw 0..1  # Trigger für Gateway (OBDC) und MIB/MMI, dass ein USM-Ereignis erkannt wurde.
          signal AB_Gurtschloss_FA_XIX_Airbag_02_XIX_E3V_K2CANFD: start 40, 2 bit, little-endian, data-type-policy=OVERRIDE, i-signal-type=PRIMITIVE, init-value=1, base-type=BT_AB_Gurtschloss_FA, compu {0=Cx0_nicht_verbaut (CM_AB_Gurtschloss_FA_Cx0_nicht_verbaut), 1=Cx1_nicht_verfuegbar_Fehler_oder_Init (CM_AB_Gurtschloss_FA_Cx1_nicht_verfuegbar_Fehler_oder_Init) (nicht_verfügbar (Fehler oder Init)), 2=Cx2_nicht_gesteckt (CM_AB_Gurtschloss_FA_Cx2_nicht_gesteckt), 3=Cx3_gesteckt (CM_AB_Gurtschloss_FA_Cx3_gesteckt)}, range raw 0..3, to SAM(timeout 2 s)  # Gurtschlosstatatus Fahrerseite
          signal AB_Gurtschloss_BF_XIX_Airbag_02_XIX_E3V_K2CANFD: start 42, 2 bit, little-endian, data-type-policy=OVERRIDE, i-signal-type=PRIMITIVE, init-value=1, base-type=BT_AB_Gurtschloss_BF, compu {0=Cx0_nicht_verbaut (CM_AB_Gurtschloss_BF_Cx0_nicht_verbaut), 1=Cx1_nicht_verfuegbar_Fehler_oder_Init (CM_AB_Gurtschloss_BF_Cx1_nicht_verfuegbar_Fehler_oder_Init) (nicht_verfügbar (Fehler oder Init)), 2=Cx2_nicht_gesteckt (CM_AB_Gurtschloss_BF_Cx2_nicht_gesteckt), 3=Cx3_gesteckt (CM_AB_Gurtschloss_BF_Cx3_gesteckt)}, range raw 0..3, to SAM(timeout 2 s)  # Gurtschlossstatus Beifahrerseite
          signal AB_Gurtschloss_Reihe2_FA_XIX_Airbag_02_XIX_E3V_K2CANFD: start 44, 2 bit, little-endian, data-type-policy=OVERRIDE, i-signal-type=PRIMITIVE, init-value=1, base-type=BT_AB_Gurtschloss_Reihe2_FA, compu {0=Cx0_nicht_verbaut (CM_AB_Gurtschloss_Reihe2_FA_Cx0_nicht_verbaut), 1=Cx1_nicht_verfuegbar_Fehler_oder_Init (CM_AB_Gurtschloss_Reihe2_FA_Cx1_nicht_verfuegbar_Fehler_oder_Init) (nicht_verfügbar (Fehler oder Init)), 2=Cx2_nicht_gesteckt (CM_AB_Gurtschloss_Reihe2_FA_Cx2_nicht_gesteckt), 3=Cx3_gesteckt (CM_AB_Gurtschloss_Reihe2_FA_Cx3_gesteckt)}, range raw 0..3  # Gurtschlossstatus 2. Reihe Fahrerseite, Mehrausstattung
          signal AB_Gurtschloss_Reihe2_MI_XIX_Airbag_02_XIX_E3V_K2CANFD: start 46, 2 bit, little-endian, data-type-policy=OVERRIDE, i-signal-type=PRIMITIVE, init-value=1, base-type=BT_AB_Gurtschloss_Reihe2_MI, compu {0=Cx0_nicht_verbaut (CM_AB_Gurtschloss_Reihe2_MI_Cx0_nicht_verbaut), 1=Cx1_nicht_verfuegbar_Fehler_oder_Init (CM_AB_Gurtschloss_Reihe2_MI_Cx1_nicht_verfuegbar_Fehler_oder_Init) (nicht_verfügbar (Fehler oder Init)), 2=Cx2_nicht_gesteckt (CM_AB_Gurtschloss_Reihe2_MI_Cx2_nicht_gesteckt), 3=Cx3_gesteckt (CM_AB_Gurtschloss_Reihe2_MI_Cx3_gesteckt)}, range raw 0..3  # Gurtschlossstatus 2. Reihe Mitte, Mehrausstattung
          signal AB_Gurtschloss_Reihe2_BF_XIX_Airbag_02_XIX_E3V_K2CANFD: start 48, 2 bit, little-endian, data-type-policy=OVERRIDE, i-signal-type=PRIMITIVE, init-value=1, base-type=BT_AB_Gurtschloss_Reihe2_BF, compu {0=Cx0_nicht_verbaut (CM_AB_Gurtschloss_Reihe2_BF_Cx0_nicht_verbaut), 1=Cx1_nicht_verfuegbar_Fehler_oder_Init (CM_AB_Gurtschloss_Reihe2_BF_Cx1_nicht_verfuegbar_Fehler_oder_Init) (nicht_verfügbar (Fehler oder Init)), 2=Cx2_nicht_gesteckt (CM_AB_Gurtschloss_Reihe2_BF_Cx2_nicht_gesteckt), 3=Cx3_gesteckt (CM_AB_Gurtschloss_Reihe2_BF_Cx3_gesteckt)}, range raw 0..3  # Gurtschlossstatus 2. Reihe Beifahrerseite, Mehrausstattung
          signal AB_Gurtschloss_Reihe3_FA_XIX_Airbag_02_XIX_E3V_K2CANFD: start 50, 2 bit, little-endian, data-type-policy=OVERRIDE, i-signal-type=PRIMITIVE, init-value=1, base-type=BT_AB_Gurtschloss_Reihe3_FA, compu {0=Cx0_nicht_verbaut (CM_AB_Gurtschloss_Reihe3_FA_Cx0_nicht_verbaut), 1=Cx1_nicht_verfuegbar_Fehler_oder_Init (CM_AB_Gurtschloss_Reihe3_FA_Cx1_nicht_verfuegbar_Fehler_oder_Init) (nicht_verfügbar (Fehler oder Init)), 2=Cx2_nicht_gesteckt (CM_AB_Gurtschloss_Reihe3_FA_Cx2_nicht_gesteckt), 3=Cx3_gesteckt (CM_AB_Gurtschloss_Reihe3_FA_Cx3_gesteckt)}, range raw 0..3  # Gurtschlossstatus 3. Reihe Fahrerseite, Mehrausstattung
          signal AB_Gurtschloss_Reihe3_MI_XIX_Airbag_02_XIX_E3V_K2CANFD: start 52, 2 bit, little-endian, data-type-policy=OVERRIDE, i-signal-type=PRIMITIVE, init-value=1, base-type=BT_AB_Gurtschloss_Reihe3_MI, compu {0=Cx0_nicht_verbaut (CM_AB_Gurtschloss_Reihe3_MI_Cx0_nicht_verbaut), 1=Cx1_nicht_verfuegbar_Fehler_oder_Init (CM_AB_Gurtschloss_Reihe3_MI_Cx1_nicht_verfuegbar_Fehler_oder_Init) (nicht_verfügbar (Fehler oder Init)), 2=Cx2_nicht_gesteckt (CM_AB_Gurtschloss_Reihe3_MI_Cx2_nicht_gesteckt), 3=Cx3_gesteckt (CM_AB_Gurtschloss_Reihe3_MI_Cx3_gesteckt)}, range raw 0..3  # Gurtschlossstatus 3. Reihe Mitte, Mehrausstattung
          signal AB_Gurtschloss_Reihe3_BF_XIX_Airbag_02_XIX_E3V_K2CANFD: start 54, 2 bit, little-endian, data-type-policy=OVERRIDE, i-signal-type=PRIMITIVE, init-value=1, base-type=BT_AB_Gurtschloss_Reihe3_BF, compu {0=Cx0_nicht_verbaut (CM_AB_Gurtschloss_Reihe3_BF_Cx0_nicht_verbaut), 1=Cx1_nicht_verfuegbar_Fehler_oder_Init (CM_AB_Gurtschloss_Reihe3_BF_Cx1_nicht_verfuegbar_Fehler_oder_Init) (nicht_verfügbar (Fehler oder Init)), 2=Cx2_nicht_gesteckt (CM_AB_Gurtschloss_Reihe3_BF_Cx2_nicht_gesteckt), 3=Cx3_gesteckt (CM_AB_Gurtschloss_Reihe3_BF_Cx3_gesteckt)}, range raw 0..3  # Gurtschlossstatus 3. Reihe Beifahrerseite, Mehrausstattung
          signal AB_Sitzpos_Sens_FA_XIX_Airbag_02_XIX_E3V_K2CANFD: start 56, 2 bit, little-endian, data-type-policy=OVERRIDE, i-signal-type=PRIMITIVE, init-value=0, base-type=BT_AB_Sitzpos_Sens_FA, invalid-value=Invalid_AB_Sitzpos_Sens_FA_XIX_Airbag_02_XIX_E3V_K2CANFD:1, compu {0=Cx0_nicht_verfuegbar (CM_AB_Sitzpos_Sens_FA_Cx0_nicht_verfuegbar), 1=Cx1_Fehler (CM_AB_Sitzpos_Sens_FA_Cx1_Fehler), 2=Cx2_Sitz_nicht_vorne (CM_AB_Sitzpos_Sens_FA_Cx2_Sitz_nicht_vorne), 3=Cx3_Sitz_vorne (CM_AB_Sitzpos_Sens_FA_Cx3_Sitz_vorne)}, range raw 0..3  # Ausgabe Sitzposition Fahrer
          signal AB_Sitzpos_Sens_BF_XIX_Airbag_02_XIX_E3V_K2CANFD: start 58, 2 bit, little-endian, data-type-policy=OVERRIDE, i-signal-type=PRIMITIVE, init-value=0, base-type=BT_AB_Sitzpos_Sens_BF, invalid-value=Invalid_AB_Sitzpos_Sens_BF_XIX_Airbag_02_XIX_E3V_K2CANFD:1, compu {0=Cx0_nicht_verfuegbar (CM_AB_Sitzpos_Sens_BF_Cx0_nicht_verfuegbar), 1=Cx1_Fehler (CM_AB_Sitzpos_Sens_BF_Cx1_Fehler), 2=Cx2_Sitz_nicht_vorne (CM_AB_Sitzpos_Sens_BF_Cx2_Sitz_nicht_vorne), 3=Cx3_Sitz_vorne (CM_AB_Sitzpos_Sens_BF_Cx3_Sitz_vorne)}, range raw 0..3  # Ausgabe Sitzposition Beifahrer
          signal AB_Wickelklappung_Reihe2_BF_XIX_Airbag_02_XIX_E3V_K2CANFD: start 60, 2 bit, little-endian, data-type-policy=OVERRIDE, i-signal-type=PRIMITIVE, init-value=1, base-type=BT_AB_Wickelklappung_Reihe2_BF, compu {0=Cx0_nicht_verbaut (CM_AB_Wickelklappung_Reihe2_BF_Cx0_nicht_verbaut), 1=Cx1_nicht_verfuegbar_Fehler_oder_Init (CM_AB_Wickelklappung_Reihe2_BF_Cx1_nicht_verfuegbar_Fehler_oder_Init) (nicht_verfuegbar__Fehler_oder_Init), 2=Cx2_nicht_verriegelt (CM_AB_Wickelklappung_Reihe2_BF_Cx2_nicht_verriegelt), 3=Cx3_verriegelt (CM_AB_Wickelklappung_Reihe2_BF_Cx3_verriegelt)}, range raw 0..3  # Status Wickelklappung 2. Reihe Beifahrerseite, Mehrausstattung
          signal AB_Wickelklappung_Reihe2_FA_XIX_Airbag_02_XIX_E3V_K2CANFD: start 62, 2 bit, little-endian, data-type-policy=OVERRIDE, i-signal-type=PRIMITIVE, init-value=1, base-type=BT_AB_Wickelklappung_Reihe2_FA, compu {0=Cx0_nicht_verbaut (CM_AB_Wickelklappung_Reihe2_FA_Cx0_nicht_verbaut), 1=Cx1_nicht_verfuegbar_Fehler_oder_Init (CM_AB_Wickelklappung_Reihe2_FA_Cx1_nicht_verfuegbar_Fehler_oder_Init) (nicht_verfuegbar__Fehler_oder_Init), 2=Cx2_nicht_verriegelt (CM_AB_Wickelklappung_Reihe2_FA_Cx2_nicht_verriegelt), 3=Cx3_verriegelt (CM_AB_Wickelklappung_Reihe2_FA_Cx3_verriegelt)}, range raw 0..3  # Status Wickelklappung 2. Reihe Fahrerseite, Mehrausstattung
          mapping SG_Airbag_02_XIX_E3V_K2CANFD: i-signal-group=SG_Airbag_02_XIX_E3V_K2CANFD, transfer-property=TRIGGERED-WITHOUT-REPETITION
      frame Ambex_SAM_01_XIX_E3V_K2CANFD: id 0x12DD54FC, from SAM, frame-length=8, can-addressing-mode=EXTENDED, can-frame-rx-behavior=CAN-FD, can-frame-tx-behavior=CAN-FD
        pdu Ambex_SAM_01_XIX_E3V_K2CANFD: length=8, minimum-delay=0.01, transmission-mode-true-timing={cyclic-timing={time-offset=0.0, time-period=0.5}, event-controlled-timing={number-of-repetitions=5, repetition-period=0.1}}, unused-bit-pattern=0
          signal AMBEX_SAL_Design3_XIX_Ambex_SAM_01_XIX_E3V_K2CANFD: start 0, 1 bit, little-endian, data-type-policy=OVERRIDE, i-signal-type=PRIMITIVE, init-value=0, base-type=BT_AMBEX_SAL_Design3, compu {0=Cx0_Aus (CM_AMBEX_SAL_Design3_Cx0_Aus), 1=Cx1_Ein (CM_AMBEX_SAL_Design3_Cx1_Ein)}, range raw 0..1, transfer-property=TRIGGERED-ON-CHANGE  # Anforderung vom Exterieur Ambientelicht an das SAL für die Signatur 3
          signal AMBEX_SAL_Design4_XIX_Ambex_SAM_01_XIX_E3V_K2CANFD: start 1, 1 bit, little-endian, data-type-policy=OVERRIDE, i-signal-type=PRIMITIVE, init-value=0, base-type=BT_AMBEX_SAL_Design4, compu {0=Cx0_Aus (CM_AMBEX_SAL_Design4_Cx0_Aus), 1=Cx1_Ein (CM_AMBEX_SAL_Design4_Cx1_Ein)}, range raw 0..1, transfer-property=TRIGGERED-ON-CHANGE  # Anforderung vom Exterieur Ambientelicht an das SAL für die Signatur 4
          signal AMBEX_SAL_Design5_XIX_Ambex_SAM_01_XIX_E3V_K2CANFD: start 2, 1 bit, little-endian, data-type-policy=OVERRIDE, i-signal-type=PRIMITIVE, init-value=0, base-type=BT_AMBEX_SAL_Design5, compu {0=Cx0_Aus (CM_AMBEX_SAL_Design5_Cx0_Aus), 1=Cx1_Ein (CM_AMBEX_SAL_Design5_Cx1_Ein)}, range raw 0..1, transfer-property=TRIGGERED-ON-CHANGE  # Anforderung vom Exterieur Ambientelicht an das SAL für die Signatur 5
          signal AMBEX_SAL_Design6_XIX_Ambex_SAM_01_XIX_E3V_K2CANFD: start 3, 1 bit, little-endian, data-type-policy=OVERRIDE, i-signal-type=PRIMITIVE, init-value=0, base-type=BT_AMBEX_SAL_Design6, compu {0=Cx0_Aus (CM_AMBEX_SAL_Design6_Cx0_Aus), 1=Cx1_Ein (CM_AMBEX_SAL_Design6_Cx1_Ein)}, range raw 0..1, transfer-property=TRIGGERED-ON-CHANGE  # Anforderung vom Exterieur Ambientelicht an das SAL für die Signatur 6
          signal Ambex_KY_Anforderung_Zonenortung_XIX_Ambex_SAM_01_XIX_E3V_K2CANFD: start 4, 1 bit, little-endian, data-type-policy=OVERRIDE, i-signal-type=PRIMITIVE, init-value=0, base-type=BT_Ambex_KY_Anforderung_Zonenortung, compu {0=Cx0_Keine_Anforderung (CM_Ambex_KY_Anforderung_Zonenortung_Cx0_Keine_Anforderung), 1=Cx1_Suche_wird_Angefordert (CM_Ambex_KY_Anforderung_Zonenortung_Cx1_Suche_wird_Angefordert)}, range raw 0..1, transfer-property=TRIGGERED-ON-CHANGE  # Gibt an, ob die Funktion Welcome-Light eine Zonenortung bei der Kessy-Funktion anfordert. Die Kessy-Funktion führt die Zonenortung nur durch, wenn mind. 1 Funktion eine Anforderung stellt. Muss dauerhaft gesetzt werden, wenn Welcome-Light aktiv (Bedingungen erfüllt und vom Nutzer aktiviert). Anderenfalls darf keine Zonenortung angefordert werden.
          signal Ambex_SAL_Bgr_Vorne_XIX_Ambex_SAM_01_XIX_E3V_K2CANFD: start 5, 1 bit, little-endian, data-type-policy=OVERRIDE, i-signal-type=PRIMITIVE, init-value=0, base-type=BT_Ambex_SAL_Bgr_Vorne, compu {0=Cx0_Aus (CM_Ambex_SAL_Bgr_Vorne_Cx0_Aus), 1=Cx1_Ein (CM_Ambex_SAL_Bgr_Vorne_Cx1_Ein)}, range raw 0..1, transfer-property=TRIGGERED-ON-CHANGE  # Anforderung vom Exterieur Ambientelicht an das SAL für das Begrenzungslicht vorne
          signal Ambex_SAL_animprofil_XIX_Ambex_SAM_01_XIX_E3V_K2CANFD: start 6, 2 bit, little-endian, data-type-policy=OVERRIDE, i-signal-type=PRIMITIVE, init-value=0, base-type=BT_Ambex_SAL_animprofil, compu {0=Cx0_Default_CH_LH_Animation (CM_Ambex_SAL_animprofil_Cx0_Default_CH_LH_Animation), 1=Cx1_CH_LH_Animation_1 (CM_Ambex_SAL_animprofil_Cx1_CH_LH_Animation_1), 2=Cx2_CH_LH_Animation_2 (CM_Ambex_SAL_animprofil_Cx2_CH_LH_Animation_2), 3=Cx3_CH_LH_Animation_3 (CM_Ambex_SAL_animprofil_Cx3_CH_LH_Animation_3)}, range raw 0..3, transfer-property=TRIGGERED-ON-CHANGE  # Anforderung vom Exterieur Ambientelicht an das SAL für eine Animation beim CH/LH
          signal Ambex_DLI_Soll_Vertikal_R_XIX_Ambex_SAM_01_XIX_E3V_K2CANFD: start 8, 12 bit, little-endian, data-type-policy=OVERRIDE, i-signal-type=PRIMITIVE, init-value=4095, base-type=BT_Ambex_DLI_Soll_Vertikal_R, compu {phys=raw*0.5-1023 for raw 0..4091, 4095=Cxfff_Init (CM_Ambex_DLI_Soll_Vertikal_R_Cxfff_Init); unit Unit_MilliMeter}, range phys -1023..1022.5 Unit_MilliMeter, raw 0..4095, unit=Unit_MilliMeter, transfer-property=TRIGGERED-ON-CHANGE  # Anforderung vom Exterieur Ambientelicht an den DLI zur vertikalen Verstellung des rechten Scheinwerfers
          signal Ambex_DLI_Soll_Vertikal_L_XIX_Ambex_SAM_01_XIX_E3V_K2CANFD: start 20, 12 bit, little-endian, data-type-policy=OVERRIDE, i-signal-type=PRIMITIVE, init-value=4095, base-type=BT_Ambex_DLI_Soll_Vertikal_L, compu {phys=raw*0.5-1023 for raw 0..4091, 4095=Cxfff_Init (CM_Ambex_DLI_Soll_Vertikal_L_Cxfff_Init); unit Unit_MilliMeter}, range phys -1023..1022.5 Unit_MilliMeter, raw 0..4095, unit=Unit_MilliMeter, transfer-property=TRIGGERED-ON-CHANGE  # Anforderung vom Exterieur Ambientelicht an den DLI zur vertikalen Verstellung des linken Scheinwerfers
          signal Ambex_DLI_Soll_Horizontal_R_XIX_Ambex_SAM_01_XIX_E3V_K2CANFD: start 32, 12 bit, little-endian, data-type-policy=OVERRIDE, i-signal-type=PRIMITIVE, init-value=4095, base-type=BT_Ambex_DLI_Soll_Horizontal_R, compu {phys=raw/64-31.96875 for raw 0..4091, 4095=Cxfff_Init (CM_Ambex_DLI_Soll_Horizontal_R_Cxfff_Init); unit Unit_DegreOfArc}, range phys -31.96875..31.953125 Unit_DegreOfArc, raw 0..4095, unit=Unit_DegreOfArc, transfer-property=TRIGGERED-ON-CHANGE  # Anforderung vom Exterieur Ambientelicht an den DLI zur horizontalen Verstellung des rechten Scheinwerfers
          signal Ambex_DLI_Soll_Horizontal_L_XIX_Ambex_SAM_01_XIX_E3V_K2CANFD: start 44, 12 bit, little-endian, data-type-policy=OVERRIDE, i-signal-type=PRIMITIVE, init-value=4095, base-type=BT_Ambex_DLI_Soll_Horizontal_L, compu {phys=raw/64-31.96875 for raw 0..4091, 4095=Cxfff_Init (CM_Ambex_DLI_Soll_Horizontal_L_Cxfff_Init); unit Unit_DegreOfArc}, range phys -31.96875..31.953125 Unit_DegreOfArc, raw 0..4095, unit=Unit_DegreOfArc, transfer-property=TRIGGERED-ON-CHANGE  # Anforderung vom Exterieur Ambientelicht an den DLI zur horizontalen Verstellung des linken Scheinwerfers
          signal Ambex_SAL_Abl_Vorne_XIX_Ambex_SAM_01_XIX_E3V_K2CANFD: start 56, 1 bit, little-endian, data-type-policy=OVERRIDE, i-signal-type=PRIMITIVE, init-value=0, base-type=BT_Ambex_SAL_Abl_Vorne, compu {0=Cx0_Aus (CM_Ambex_SAL_Abl_Vorne_Cx0_Aus), 1=Cx1_Ein (CM_Ambex_SAL_Abl_Vorne_Cx1_Ein)}, range raw 0..1, transfer-property=TRIGGERED-ON-CHANGE  # Anforderung vom Exterieur Ambientelicht an das SAL für das Abblendlicht vorne
          signal Ambex_SAL_Design1_XIX_Ambex_SAM_01_XIX_E3V_K2CANFD: start 57, 1 bit, little-endian, data-type-policy=OVERRIDE, i-signal-type=PRIMITIVE, init-value=0, base-type=BT_Ambex_SAL_Design1, compu {0=Cx0_Aus (CM_Ambex_SAL_Design1_Cx0_Aus), 1=Cx1_Ein (CM_Ambex_SAL_Design1_Cx1_Ein)}, range raw 0..1, transfer-property=TRIGGERED-ON-CHANGE  # Anforderung vom Exterieur Ambientelicht an das SAL für die Signatur 1
          signal Ambex_SAL_Design2_XIX_Ambex_SAM_01_XIX_E3V_K2CANFD: start 58, 1 bit, little-endian, data-type-policy=OVERRIDE, i-signal-type=PRIMITIVE, init-value=0, base-type=BT_Ambex_SAL_Design2, compu {0=Cx0_Aus (CM_Ambex_SAL_Design2_Cx0_Aus), 1=Cx1_Ein (CM_Ambex_SAL_Design2_Cx1_Ein)}, range raw 0..1, transfer-property=TRIGGERED-ON-CHANGE  # Anforderung vom Exterieur Ambientelicht an das SAL für die Signatur 2
          signal Ambex_SAL_Kzl_XIX_Ambex_SAM_01_XIX_E3V_K2CANFD: start 59, 1 bit, little-endian, data-type-policy=OVERRIDE, i-signal-type=PRIMITIVE, init-value=0, base-type=BT_Ambex_SAL_Kzl, compu {0=Cx0_Aus (CM_Ambex_SAL_Kzl_Cx0_Aus), 1=Cx1_Ein (CM_Ambex_SAL_Kzl_Cx1_Ein)}, range raw 0..1, transfer-property=TRIGGERED-ON-CHANGE  # Anforderung vom Exterieur Ambientelicht an das SAL für die Kennzeichenleuchte
          signal Ambex_SAL_Schlusslicht_XIX_Ambex_SAM_01_XIX_E3V_K2CANFD: start 60, 1 bit, little-endian, data-type-policy=OVERRIDE, i-signal-type=PRIMITIVE, init-value=0, base-type=BT_Ambex_SAL_Schlusslicht, compu {0=Cx0_Aus (CM_Ambex_SAL_Schlusslicht_Cx0_Aus), 1=Cx1_Ein (CM_Ambex_SAL_Schlusslicht_Cx1_Ein)}, range raw 0..1, transfer-property=TRIGGERED-ON-CHANGE  # Anforderung vom Exterieur Ambientelicht an das SAL für das Schlusslicht
          signal Ambex_DLI_InszStatus_XIX_Ambex_SAM_01_XIX_E3V_K2CANFD: start 61, 3 bit, little-endian, data-type-policy=OVERRIDE, i-signal-type=PRIMITIVE, init-value=0, base-type=BT_Ambex_DLI_InszStatus, invalid-value=Invalid_Ambex_DLI_InszStatus_XIX_Ambex_SAM_01_XIX_E3V_K2CANFD:4, compu {0=Cx0_Init (CM_Ambex_DLI_InszStatus_Cx0_Init), 1=Cx1_Referenzlaufanforderung (CM_Ambex_DLI_InszStatus_Cx1_Referenzlaufanforderung), 2=Cx2_Animationlaeuft (CM_Ambex_DLI_InszStatus_Cx2_Animationlaeuft), 3=Cx3_Animationfertig (CM_Ambex_DLI_InszStatus_Cx3_Animationfertig), 4=Cx4_Fehler (CM_Ambex_DLI_InszStatus_Cx4_Fehler)}, range raw 0..4, transfer-property=TRIGGERED-ON-CHANGE  # Status vom Exterieur Ambientelicht an den DLI
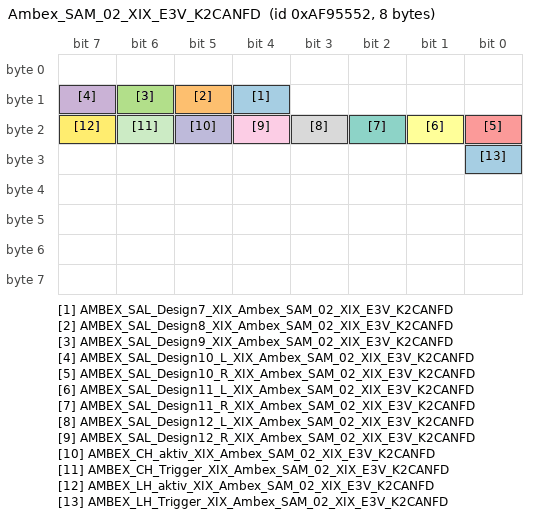
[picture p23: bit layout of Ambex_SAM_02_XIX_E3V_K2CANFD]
      frame Ambex_SAM_02_XIX_E3V_K2CANFD: id 0xAF95552, from SAM, frame-length=8, can-addressing-mode=EXTENDED, can-frame-rx-behavior=CAN-FD, can-frame-tx-behavior=CAN-FD
        pdu Ambex_SAM_02_XIX_E3V_K2CANFD: length=8, minimum-delay=0.01, transmission-mode-true-timing={cyclic-timing={time-offset=0, time-period=0.1}, event-controlled-timing={number-of-repetitions=0, repetition-period=0.0}}, unused-bit-pattern=0
          signal AMBEX_SAL_Design7_XIX_Ambex_SAM_02_XIX_E3V_K2CANFD: start 12, 1 bit, little-endian, data-type-policy=OVERRIDE, i-signal-type=PRIMITIVE, init-value=0, base-type=BT_AMBEX_SAL_Design7, compu {0=Cx0_Aus (CM_AMBEX_SAL_Design7_Cx0_Aus), 1=Cx1_Ein (CM_AMBEX_SAL_Design7_Cx1_Ein)}, range raw 0..1, transfer-property=TRIGGERED-ON-CHANGE-WITHOUT-REPETITION  # Anforderung vom Exterieur Ambientelicht an das SAL für die Signatur 7
          signal AMBEX_SAL_Design8_XIX_Ambex_SAM_02_XIX_E3V_K2CANFD: start 13, 1 bit, little-endian, data-type-policy=OVERRIDE, i-signal-type=PRIMITIVE, init-value=0, base-type=BT_AMBEX_SAL_Design8, compu {0=Cx0_Aus (CM_AMBEX_SAL_Design8_Cx0_Aus), 1=Cx1_Ein (CM_AMBEX_SAL_Design8_Cx1_Ein)}, range raw 0..1, transfer-property=TRIGGERED-ON-CHANGE-WITHOUT-REPETITION  # Anforderung vom Exterieur Ambientelicht an das SAL für die Signatur 8
          signal AMBEX_SAL_Design9_XIX_Ambex_SAM_02_XIX_E3V_K2CANFD: start 14, 1 bit, little-endian, data-type-policy=OVERRIDE, i-signal-type=PRIMITIVE, init-value=0, base-type=BT_AMBEX_SAL_Design9, compu {0=Cx0_Aus (CM_AMBEX_SAL_Design9_Cx0_Aus), 1=Cx1_Ein (CM_AMBEX_SAL_Design9_Cx1_Ein)}, range raw 0..1, transfer-property=TRIGGERED-ON-CHANGE-WITHOUT-REPETITION  # Anforderung vom Exterieur Ambientelicht an das SAL für die Signatur 9
          signal AMBEX_SAL_Design10_L_XIX_Ambex_SAM_02_XIX_E3V_K2CANFD: start 15, 1 bit, little-endian, data-type-policy=OVERRIDE, i-signal-type=PRIMITIVE, init-value=0, base-type=BT_AMBEX_SAL_Design10_L, compu {0=Cx0_Aus (CM_AMBEX_SAL_Design10_L_Cx0_Aus), 1=Cx1_Ein (CM_AMBEX_SAL_Design10_L_Cx1_Ein)}, range raw 0..1, transfer-property=TRIGGERED-ON-CHANGE-WITHOUT-REPETITION  # Anforderung vom Exterieur Ambientelicht an das SAL für die Signatur 10 Links
          signal AMBEX_SAL_Design10_R_XIX_Ambex_SAM_02_XIX_E3V_K2CANFD: start 16, 1 bit, little-endian, data-type-policy=OVERRIDE, i-signal-type=PRIMITIVE, init-value=0, base-type=BT_AMBEX_SAL_Design10_R, compu {0=Cx0_Aus (CM_AMBEX_SAL_Design10_R_Cx0_Aus), 1=Cx1_Ein (CM_AMBEX_SAL_Design10_R_Cx1_Ein)}, range raw 0..1, transfer-property=TRIGGERED-ON-CHANGE-WITHOUT-REPETITION  # Anforderung vom Exterieur Ambientelicht an das SAL für die Signatur 10 Rechts
          signal AMBEX_SAL_Design11_L_XIX_Ambex_SAM_02_XIX_E3V_K2CANFD: start 17, 1 bit, little-endian, data-type-policy=OVERRIDE, i-signal-type=PRIMITIVE, init-value=0, base-type=BT_AMBEX_SAL_Design11_L, compu {0=Cx0_Aus (CM_AMBEX_SAL_Design11_L_Cx0_Aus), 1=Cx1_Ein (CM_AMBEX_SAL_Design11_L_Cx1_Ein)}, range raw 0..1, transfer-property=TRIGGERED-ON-CHANGE-WITHOUT-REPETITION  # Anforderung vom Exterieur Ambientelicht an das SAL für die Signatur 11 Links
          signal AMBEX_SAL_Design11_R_XIX_Ambex_SAM_02_XIX_E3V_K2CANFD: start 18, 1 bit, little-endian, data-type-policy=OVERRIDE, i-signal-type=PRIMITIVE, init-value=0, base-type=BT_AMBEX_SAL_Design11_R, compu {0=Cx0_Aus (CM_AMBEX_SAL_Design11_R_Cx0_Aus), 1=Cx1_Ein (CM_AMBEX_SAL_Design11_R_Cx1_Ein)}, range raw 0..1, transfer-property=TRIGGERED-ON-CHANGE-WITHOUT-REPETITION  # Anforderung vom Exterieur Ambientelicht an das SAL für die Signatur 11 Rechts
          signal AMBEX_SAL_Design12_L_XIX_Ambex_SAM_02_XIX_E3V_K2CANFD: start 19, 1 bit, little-endian, data-type-policy=OVERRIDE, i-signal-type=PRIMITIVE, init-value=0, base-type=BT_AMBEX_SAL_Design12_L, compu {0=Cx0_Aus (CM_AMBEX_SAL_Design12_L_Cx0_Aus), 1=Cx1_Ein (CM_AMBEX_SAL_Design12_L_Cx1_Ein)}, range raw 0..1, transfer-property=TRIGGERED-ON-CHANGE-WITHOUT-REPETITION  # Anforderung vom Exterieur Ambientelicht an das SAL für die Signatur 12 Links
          signal AMBEX_SAL_Design12_R_XIX_Ambex_SAM_02_XIX_E3V_K2CANFD: start 20, 1 bit, little-endian, data-type-policy=OVERRIDE, i-signal-type=PRIMITIVE, init-value=0, base-type=BT_AMBEX_SAL_Design12_R, compu {0=Cx0_Aus (CM_AMBEX_SAL_Design12_R_Cx0_Aus), 1=Cx1_Ein (CM_AMBEX_SAL_Design12_R_Cx1_Ein)}, range raw 0..1, transfer-property=TRIGGERED-ON-CHANGE-WITHOUT-REPETITION  # Anforderung vom Exterieur Ambientelicht an das SAL für die Signatur 12 Rechts
          signal AMBEX_CH_aktiv_XIX_Ambex_SAM_02_XIX_E3V_K2CANFD: start 21, 1 bit, little-endian, data-type-policy=OVERRIDE, i-signal-type=PRIMITIVE, init-value=0, base-type=BT_AMBEX_CH_aktiv, compu {0=Cx0_nicht_aktiv (CM_AMBEX_CH_aktiv_Cx0_nicht_aktiv), 1=Cx1_aktiv (CM_AMBEX_CH_aktiv_Cx1_aktiv)}, range raw 0..1, transfer-property=TRIGGERED-ON-CHANGE-WITHOUT-REPETITION  # Statussignal vom Exterieur Ambiente. Gibt an, ob eine Coming Home-Animation aktiv ist.
          signal AMBEX_CH_Trigger_XIX_Ambex_SAM_02_XIX_E3V_K2CANFD: start 22, 1 bit, little-endian, data-type-policy=OVERRIDE, i-signal-type=PRIMITIVE, init-value=0, base-type=BT_AMBEX_CH_Trigger, compu {0=Cx0_nicht_aktiv (CM_AMBEX_CH_Trigger_Cx0_nicht_aktiv), 1=Cx1_aktiv (CM_AMBEX_CH_Trigger_Cx1_aktiv)}, range raw 0..1, transfer-property=TRIGGERED-ON-CHANGE-WITHOUT-REPETITION  # Triggersignal vom Exterieur Ambiente. Gibt an, wann eine Animation während einer Coming Home-Inszenierung gestartet werden soll.
          signal AMBEX_LH_aktiv_XIX_Ambex_SAM_02_XIX_E3V_K2CANFD: start 23, 1 bit, little-endian, data-type-policy=OVERRIDE, i-signal-type=PRIMITIVE, init-value=0, base-type=BT_AMBEX_LH_aktiv, compu {0=Cx0_nicht_aktiv (CM_AMBEX_LH_aktiv_Cx0_nicht_aktiv), 1=Cx1_aktiv (CM_AMBEX_LH_aktiv_Cx1_aktiv)}, range raw 0..1, transfer-property=TRIGGERED-ON-CHANGE-WITHOUT-REPETITION  # Statussignal vom Exterieur Ambiente. Gibt an, ob eine Leaving Home-Animation aktiv ist.
          signal AMBEX_LH_Trigger_XIX_Ambex_SAM_02_XIX_E3V_K2CANFD: start 24, 1 bit, little-endian, data-type-policy=OVERRIDE, i-signal-type=PRIMITIVE, init-value=0, base-type=BT_AMBEX_LH_Trigger, compu {0=Cx0_nicht_aktiv (CM_AMBEX_LH_Trigger_Cx0_nicht_aktiv), 1=Cx1_aktiv (CM_AMBEX_LH_Trigger_Cx1_aktiv)}, range raw 0..1, transfer-property=TRIGGERED-ON-CHANGE-WITHOUT-REPETITION  # Triggersignal vom Exterieur Ambiente. Gibt an, wann eine Animation während einer Leaving Home-Inszenierung gestartet werden soll.
